[part 9 of 10: package /SoftwareComponents/CompositionSWComponents]
AUTOSAR XML (schema 00053)
package /SoftwareComponents/CompositionSWComponents  (continued)
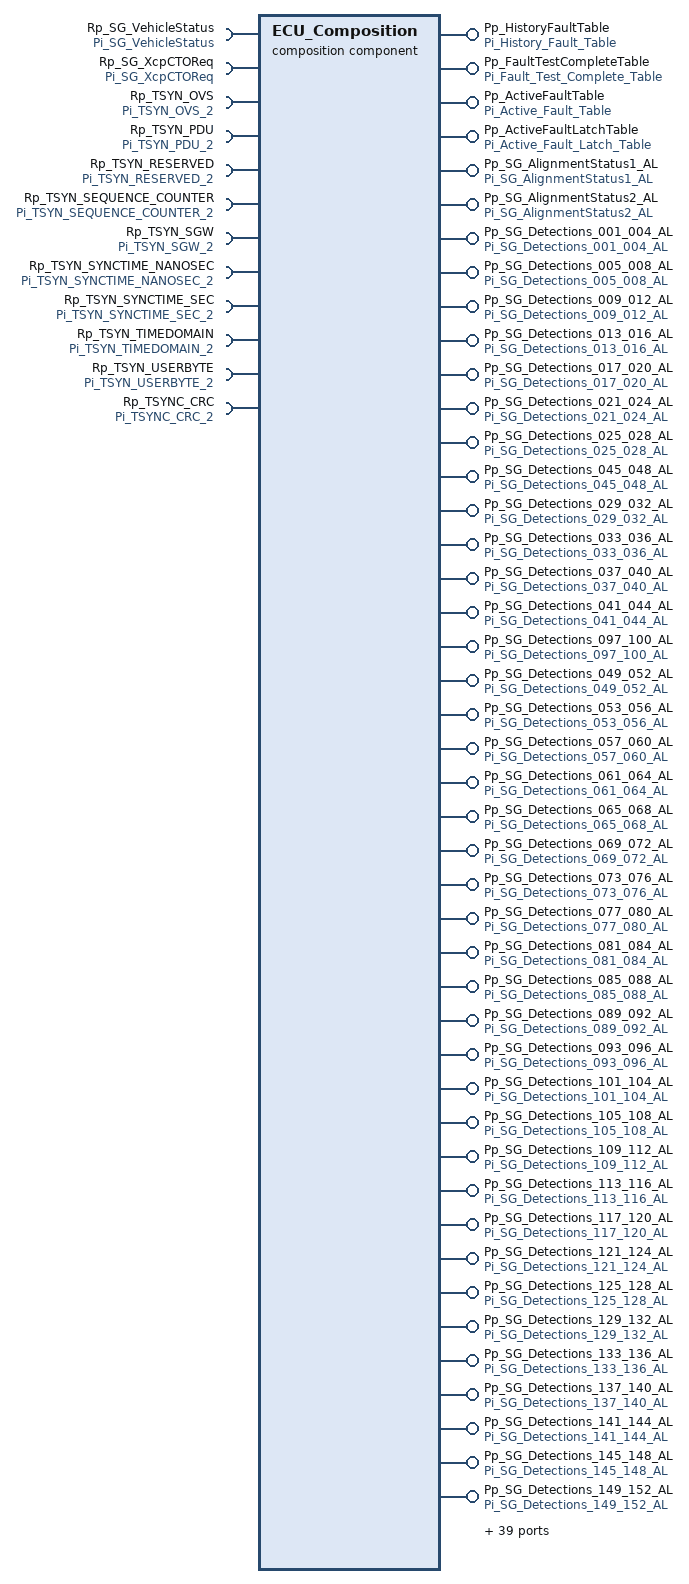
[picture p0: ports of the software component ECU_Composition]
  composition sw component type ECU_Composition  (continued)
    189 x provide port:  (continued)
      Pp_SG_Detections_361_364: nonqueued-sender-com-spec{data-element=Vdp_SG_Detections_361_364, init-value=fields=[DET_AZIMUTH_361:0, DET_AZIMUTH_362:0, DET_AZIMUTH_363:0, DET_AZIMUTH_364:0, DET_AZIMUTH_ERR_361:0, DET_AZIMUTH_ERR_362:0, DET_AZIMUTH_ERR_363:0, DET_AZIMUTH_ERR_364:0, DET_BI_STATIC_FLAG_361:0, DET_BI_STATIC_FLAG_362:0, DET_BI_STATIC_FLAG_363:0, DET_BI_STATIC_FLAG_364:0, DET_CONFD_AZIMUTH_361:0, DET_CONFD_AZIMUTH_362:0, DET_CONFD_AZIMUTH_363:0, DET_CONFD_AZIMUTH_364:0, DET_CONFD_ELEVATION_361:0, DET_CONFD_ELEVATION_362:0, DET_CONFD_ELEVATION_363:0, DET_CONFD_ELEVATION_364:0, DET_ELEVATION_361:0, DET_ELEVATION_362:0, DET_ELEVATION_363:0, DET_ELEVATION_364:0, DET_ELEVATION_ERR_361:0, DET_ELEVATION_ERR_362:0, DET_ELEVATION_ERR_363:0, DET_ELEVATION_ERR_364:0, DET_EXISTENCE_PROB_361:0, DET_EXISTENCE_PROB_362:0, DET_EXISTENCE_PROB_363:0, DET_EXISTENCE_PROB_364:0, DET_HVC_FLAG_361:0, DET_HVC_FLAG_362:0, DET_HVC_FLAG_363:0, DET_HVC_FLAG_364:0, DET_MH_CRC16_361_364:0, DET_MH_CYCLE_COUNTER_361_364:0, DET_MH_SCAN_INDEX_4LSB_361_364:0, DET_OUTSIDE_SECTOR_361:0, DET_OUTSIDE_SECTOR_362:0, DET_OUTSIDE_SECTOR_363:0, DET_OUTSIDE_SECTOR_364:0, DET_POINT_TARGET_PROB_361:0, DET_POINT_TARGET_PROB_362:0, DET_POINT_TARGET_PROB_363:0, DET_POINT_TARGET_PROB_364:0, DET_RANGE_361:0, DET_RANGE_362:0, DET_RANGE_363:0, DET_RANGE_364:0, DET_RANGE_ERR_361:0, DET_RANGE_ERR_362:0, DET_RANGE_ERR_363:0, DET_RANGE_ERR_364:0, DET_RANGE_VELOCITY_361:16384, DET_RANGE_VELOCITY_362:16384, DET_RANGE_VELOCITY_363:16384, DET_RANGE_VELOCITY_364:16384, DET_RANGE_VELOCITY_ERR_361:0, DET_RANGE_VELOCITY_ERR_362:0, DET_RANGE_VELOCITY_ERR_363:0, DET_RANGE_VELOCITY_ERR_364:0, DET_RCS_361:128, DET_RCS_362:128, DET_RCS_363:128, DET_RCS_364:128, DET_SNR_361:0, DET_SNR_362:0, DET_SNR_363:0, DET_SNR_364:0, DET_SUPER_RES_TARGET_361:0, DET_SUPER_RES_TARGET_362:0, DET_SUPER_RES_TARGET_363:0, DET_SUPER_RES_TARGET_364:0, DET_VALID_FLAG_361:0, DET_VALID_FLAG_362:0, DET_VALID_FLAG_363:0, DET_VALID_FLAG_364:0]}, provided-interface=Pi_SG_Detections_361_364
      Pp_SG_Detections_365_368: nonqueued-sender-com-spec{data-element=Vdp_SG_Detections_365_368, init-value=fields=[DET_AZIMUTH_365:0, DET_AZIMUTH_366:0, DET_AZIMUTH_367:0, DET_AZIMUTH_368:0, DET_AZIMUTH_ERR_365:0, DET_AZIMUTH_ERR_366:0, DET_AZIMUTH_ERR_367:0, DET_AZIMUTH_ERR_368:0, DET_BI_STATIC_FLAG_365:0, DET_BI_STATIC_FLAG_366:0, DET_BI_STATIC_FLAG_367:0, DET_BI_STATIC_FLAG_368:0, DET_CONFD_AZIMUTH_365:0, DET_CONFD_AZIMUTH_366:0, DET_CONFD_AZIMUTH_367:0, DET_CONFD_AZIMUTH_368:0, DET_CONFD_ELEVATION_365:0, DET_CONFD_ELEVATION_366:0, DET_CONFD_ELEVATION_367:0, DET_CONFD_ELEVATION_368:0, DET_ELEVATION_365:0, DET_ELEVATION_366:0, DET_ELEVATION_367:0, DET_ELEVATION_368:0, DET_ELEVATION_ERR_365:0, DET_ELEVATION_ERR_366:0, DET_ELEVATION_ERR_367:0, DET_ELEVATION_ERR_368:0, DET_EXISTENCE_PROB_365:0, DET_EXISTENCE_PROB_366:0, DET_EXISTENCE_PROB_367:0, DET_EXISTENCE_PROB_368:0, DET_HVC_FLAG_365:0, DET_HVC_FLAG_366:0, DET_HVC_FLAG_367:0, DET_HVC_FLAG_368:0, DET_MH_CRC16_365_368:0, DET_MH_CYCLE_COUNTER_365_368:0, DET_MH_SCAN_INDEX_4LSB_365_368:0, DET_OUTSIDE_SECTOR_365:0, DET_OUTSIDE_SECTOR_366:0, DET_OUTSIDE_SECTOR_367:0, DET_OUTSIDE_SECTOR_368:0, DET_POINT_TARGET_PROB_365:0, DET_POINT_TARGET_PROB_366:0, DET_POINT_TARGET_PROB_367:0, DET_POINT_TARGET_PROB_368:0, DET_RANGE_365:0, DET_RANGE_366:0, DET_RANGE_367:0, DET_RANGE_368:0, DET_RANGE_ERR_365:0, DET_RANGE_ERR_366:0, DET_RANGE_ERR_367:0, DET_RANGE_ERR_368:0, DET_RANGE_VELOCITY_365:16384, DET_RANGE_VELOCITY_366:16384, DET_RANGE_VELOCITY_367:16384, DET_RANGE_VELOCITY_368:16384, DET_RANGE_VELOCITY_ERR_365:0, DET_RANGE_VELOCITY_ERR_366:0, DET_RANGE_VELOCITY_ERR_367:0, DET_RANGE_VELOCITY_ERR_368:0, DET_RCS_365:128, DET_RCS_366:128, DET_RCS_367:128, DET_RCS_368:128, DET_SNR_365:0, DET_SNR_366:0, DET_SNR_367:0, DET_SNR_368:0, DET_SUPER_RES_TARGET_365:0, DET_SUPER_RES_TARGET_366:0, DET_SUPER_RES_TARGET_367:0, DET_SUPER_RES_TARGET_368:0, DET_VALID_FLAG_365:0, DET_VALID_FLAG_366:0, DET_VALID_FLAG_367:0, DET_VALID_FLAG_368:0]}, provided-interface=Pi_SG_Detections_365_368
      Pp_SG_Detections_369_372: nonqueued-sender-com-spec{data-element=Vdp_SG_Detections_369_372, init-value=fields=[DET_AZIMUTH_369:0, DET_AZIMUTH_370:0, DET_AZIMUTH_371:0, DET_AZIMUTH_372:0, DET_AZIMUTH_ERR_369:0, DET_AZIMUTH_ERR_370:0, DET_AZIMUTH_ERR_371:0, DET_AZIMUTH_ERR_372:0, DET_BI_STATIC_FLAG_369:0, DET_BI_STATIC_FLAG_370:0, DET_BI_STATIC_FLAG_371:0, DET_BI_STATIC_FLAG_372:0, DET_CONFD_AZIMUTH_369:0, DET_CONFD_AZIMUTH_370:0, DET_CONFD_AZIMUTH_371:0, DET_CONFD_AZIMUTH_372:0, DET_CONFD_ELEVATION_369:0, DET_CONFD_ELEVATION_370:0, DET_CONFD_ELEVATION_371:0, DET_CONFD_ELEVATION_372:0, DET_ELEVATION_369:0, DET_ELEVATION_370:0, DET_ELEVATION_371:0, DET_ELEVATION_372:0, DET_ELEVATION_ERR_369:0, DET_ELEVATION_ERR_370:0, DET_ELEVATION_ERR_371:0, DET_ELEVATION_ERR_372:0, DET_EXISTENCE_PROB_369:0, DET_EXISTENCE_PROB_370:0, DET_EXISTENCE_PROB_371:0, DET_EXISTENCE_PROB_372:0, DET_HVC_FLAG_369:0, DET_HVC_FLAG_370:0, DET_HVC_FLAG_371:0, DET_HVC_FLAG_372:0, DET_MH_CRC16_369_372:0, DET_MH_CYCLE_COUNTER_369_372:0, DET_MH_SCAN_INDEX_4LSB_369_372:0, DET_OUTSIDE_SECTOR_369:0, DET_OUTSIDE_SECTOR_370:0, DET_OUTSIDE_SECTOR_371:0, DET_OUTSIDE_SECTOR_372:0, DET_POINT_TARGET_PROB_369:0, DET_POINT_TARGET_PROB_370:0, DET_POINT_TARGET_PROB_371:0, DET_POINT_TARGET_PROB_372:0, DET_RANGE_369:0, DET_RANGE_370:0, DET_RANGE_371:0, DET_RANGE_372:0, DET_RANGE_ERR_369:0, DET_RANGE_ERR_370:0, DET_RANGE_ERR_371:0, DET_RANGE_ERR_372:0, DET_RANGE_VELOCITY_369:16384, DET_RANGE_VELOCITY_370:16384, DET_RANGE_VELOCITY_371:16384, DET_RANGE_VELOCITY_372:16384, DET_RANGE_VELOCITY_ERR_369:0, DET_RANGE_VELOCITY_ERR_370:0, DET_RANGE_VELOCITY_ERR_371:0, DET_RANGE_VELOCITY_ERR_372:0, DET_RCS_369:128, DET_RCS_370:128, DET_RCS_371:128, DET_RCS_372:128, DET_SNR_369:0, DET_SNR_370:0, DET_SNR_371:0, DET_SNR_372:0, DET_SUPER_RES_TARGET_369:0, DET_SUPER_RES_TARGET_370:0, DET_SUPER_RES_TARGET_371:0, DET_SUPER_RES_TARGET_372:0, DET_VALID_FLAG_369:0, DET_VALID_FLAG_370:0, DET_VALID_FLAG_371:0, DET_VALID_FLAG_372:0]}, provided-interface=Pi_SG_Detections_369_372
      Pp_SG_Detections_373_376: nonqueued-sender-com-spec{data-element=Vdp_SG_Detections_373_376, init-value=fields=[DET_AZIMUTH_373:0, DET_AZIMUTH_374:0, DET_AZIMUTH_375:0, DET_AZIMUTH_376:0, DET_AZIMUTH_ERR_373:0, DET_AZIMUTH_ERR_374:0, DET_AZIMUTH_ERR_375:0, DET_AZIMUTH_ERR_376:0, DET_BI_STATIC_FLAG_373:0, DET_BI_STATIC_FLAG_374:0, DET_BI_STATIC_FLAG_375:0, DET_BI_STATIC_FLAG_376:0, DET_CONFD_AZIMUTH_373:0, DET_CONFD_AZIMUTH_374:0, DET_CONFD_AZIMUTH_375:0, DET_CONFD_AZIMUTH_376:0, DET_CONFD_ELEVATION_373:0, DET_CONFD_ELEVATION_374:0, DET_CONFD_ELEVATION_375:0, DET_CONFD_ELEVATION_376:0, DET_ELEVATION_373:0, DET_ELEVATION_374:0, DET_ELEVATION_375:0, DET_ELEVATION_376:0, DET_ELEVATION_ERR_373:0, DET_ELEVATION_ERR_374:0, DET_ELEVATION_ERR_375:0, DET_ELEVATION_ERR_376:0, DET_EXISTENCE_PROB_373:0, DET_EXISTENCE_PROB_374:0, DET_EXISTENCE_PROB_375:0, DET_EXISTENCE_PROB_376:0, DET_HVC_FLAG_373:0, DET_HVC_FLAG_374:0, DET_HVC_FLAG_375:0, DET_HVC_FLAG_376:0, DET_MH_CRC16_373_376:0, DET_MH_CYCLE_COUNTER_373_376:0, DET_MH_SCAN_INDEX_4LSB_373_376:0, DET_OUTSIDE_SECTOR_373:0, DET_OUTSIDE_SECTOR_374:0, DET_OUTSIDE_SECTOR_375:0, DET_OUTSIDE_SECTOR_376:0, DET_POINT_TARGET_PROB_373:0, DET_POINT_TARGET_PROB_374:0, DET_POINT_TARGET_PROB_375:0, DET_POINT_TARGET_PROB_376:0, DET_RANGE_373:0, DET_RANGE_374:0, DET_RANGE_375:0, DET_RANGE_376:0, DET_RANGE_ERR_373:0, DET_RANGE_ERR_374:0, DET_RANGE_ERR_375:0, DET_RANGE_ERR_376:0, DET_RANGE_VELOCITY_373:16384, DET_RANGE_VELOCITY_374:16384, DET_RANGE_VELOCITY_375:16384, DET_RANGE_VELOCITY_376:16384, DET_RANGE_VELOCITY_ERR_373:0, DET_RANGE_VELOCITY_ERR_374:0, DET_RANGE_VELOCITY_ERR_375:0, DET_RANGE_VELOCITY_ERR_376:0, DET_RCS_373:128, DET_RCS_374:128, DET_RCS_375:128, DET_RCS_376:128, DET_SNR_373:0, DET_SNR_374:0, DET_SNR_375:0, DET_SNR_376:0, DET_SUPER_RES_TARGET_373:0, DET_SUPER_RES_TARGET_374:0, DET_SUPER_RES_TARGET_375:0, DET_SUPER_RES_TARGET_376:0, DET_VALID_FLAG_373:0, DET_VALID_FLAG_374:0, DET_VALID_FLAG_375:0, DET_VALID_FLAG_376:0]}, provided-interface=Pi_SG_Detections_373_376
      Pp_SG_Detections_377_380: nonqueued-sender-com-spec{data-element=Vdp_SG_Detections_377_380, init-value=fields=[DET_AZIMUTH_377:0, DET_AZIMUTH_378:0, DET_AZIMUTH_379:0, DET_AZIMUTH_380:0, DET_AZIMUTH_ERR_377:0, DET_AZIMUTH_ERR_378:0, DET_AZIMUTH_ERR_379:0, DET_AZIMUTH_ERR_380:0, DET_BI_STATIC_FLAG_377:0, DET_BI_STATIC_FLAG_378:0, DET_BI_STATIC_FLAG_379:0, DET_BI_STATIC_FLAG_380:0, DET_CONFD_AZIMUTH_377:0, DET_CONFD_AZIMUTH_378:0, DET_CONFD_AZIMUTH_379:0, DET_CONFD_AZIMUTH_380:0, DET_CONFD_ELEVATION_377:0, DET_CONFD_ELEVATION_378:0, DET_CONFD_ELEVATION_379:0, DET_CONFD_ELEVATION_380:0, DET_ELEVATION_377:0, DET_ELEVATION_378:0, DET_ELEVATION_379:0, DET_ELEVATION_380:0, DET_ELEVATION_ERR_377:0, DET_ELEVATION_ERR_378:0, DET_ELEVATION_ERR_379:0, DET_ELEVATION_ERR_380:0, DET_EXISTENCE_PROB_377:0, DET_EXISTENCE_PROB_378:0, DET_EXISTENCE_PROB_379:0, DET_EXISTENCE_PROB_380:0, DET_HVC_FLAG_377:0, DET_HVC_FLAG_378:0, DET_HVC_FLAG_379:0, DET_HVC_FLAG_380:0, DET_MH_CRC16_377_380:0, DET_MH_CYCLE_COUNTER_377_380:0, DET_MH_SCAN_INDEX_4LSB_377_380:0, DET_OUTSIDE_SECTOR_377:0, DET_OUTSIDE_SECTOR_378:0, DET_OUTSIDE_SECTOR_379:0, DET_OUTSIDE_SECTOR_380:0, DET_POINT_TARGET_PROB_377:0, DET_POINT_TARGET_PROB_378:0, DET_POINT_TARGET_PROB_379:0, DET_POINT_TARGET_PROB_380:0, DET_RANGE_377:0, DET_RANGE_378:0, DET_RANGE_379:0, DET_RANGE_380:0, DET_RANGE_ERR_377:0, DET_RANGE_ERR_378:0, DET_RANGE_ERR_379:0, DET_RANGE_ERR_380:0, DET_RANGE_VELOCITY_377:16384, DET_RANGE_VELOCITY_378:16384, DET_RANGE_VELOCITY_379:16384, DET_RANGE_VELOCITY_380:16384, DET_RANGE_VELOCITY_ERR_377:0, DET_RANGE_VELOCITY_ERR_378:0, DET_RANGE_VELOCITY_ERR_379:0, DET_RANGE_VELOCITY_ERR_380:0, DET_RCS_377:128, DET_RCS_378:128, DET_RCS_379:128, DET_RCS_380:128, DET_SNR_377:0, DET_SNR_378:0, DET_SNR_379:0, DET_SNR_380:0, DET_SUPER_RES_TARGET_377:0, DET_SUPER_RES_TARGET_378:0, DET_SUPER_RES_TARGET_379:0, DET_SUPER_RES_TARGET_380:0, DET_VALID_FLAG_377:0, DET_VALID_FLAG_378:0, DET_VALID_FLAG_379:0, DET_VALID_FLAG_380:0]}, provided-interface=Pi_SG_Detections_377_380
      Pp_SG_Detections_381_384: nonqueued-sender-com-spec{data-element=Vdp_SG_Detections_381_384, init-value=fields=[DET_AZIMUTH_381:0, DET_AZIMUTH_382:0, DET_AZIMUTH_383:0, DET_AZIMUTH_384:0, DET_AZIMUTH_ERR_381:0, DET_AZIMUTH_ERR_382:0, DET_AZIMUTH_ERR_383:0, DET_AZIMUTH_ERR_384:0, DET_BI_STATIC_FLAG_381:0, DET_BI_STATIC_FLAG_382:0, DET_BI_STATIC_FLAG_383:0, DET_BI_STATIC_FLAG_384:0, DET_CONFD_AZIMUTH_381:0, DET_CONFD_AZIMUTH_382:0, DET_CONFD_AZIMUTH_383:0, DET_CONFD_AZIMUTH_384:0, DET_CONFD_ELEVATION_381:0, DET_CONFD_ELEVATION_382:0, DET_CONFD_ELEVATION_383:0, DET_CONFD_ELEVATION_384:0, DET_ELEVATION_381:0, DET_ELEVATION_382:0, DET_ELEVATION_383:0, DET_ELEVATION_384:0, DET_ELEVATION_ERR_381:0, DET_ELEVATION_ERR_382:0, DET_ELEVATION_ERR_383:0, DET_ELEVATION_ERR_384:0, DET_EXISTENCE_PROB_381:0, DET_EXISTENCE_PROB_382:0, DET_EXISTENCE_PROB_383:0, DET_EXISTENCE_PROB_384:0, DET_HVC_FLAG_381:0, DET_HVC_FLAG_382:0, DET_HVC_FLAG_383:0, DET_HVC_FLAG_384:0, DET_MH_CRC16_381_384:0, DET_MH_CYCLE_COUNTER_381_384:0, DET_MH_SCAN_INDEX_4LSB_381_384:0, DET_OUTSIDE_SECTOR_381:0, DET_OUTSIDE_SECTOR_382:0, DET_OUTSIDE_SECTOR_383:0, DET_OUTSIDE_SECTOR_384:0, DET_POINT_TARGET_PROB_381:0, DET_POINT_TARGET_PROB_382:0, DET_POINT_TARGET_PROB_383:0, DET_POINT_TARGET_PROB_384:0, DET_RANGE_381:0, DET_RANGE_382:0, DET_RANGE_383:0, DET_RANGE_384:0, DET_RANGE_ERR_381:0, DET_RANGE_ERR_382:0, DET_RANGE_ERR_383:0, DET_RANGE_ERR_384:0, DET_RANGE_VELOCITY_381:16384, DET_RANGE_VELOCITY_382:16384, DET_RANGE_VELOCITY_383:16384, DET_RANGE_VELOCITY_384:16384, DET_RANGE_VELOCITY_ERR_381:0, DET_RANGE_VELOCITY_ERR_382:0, DET_RANGE_VELOCITY_ERR_383:0, DET_RANGE_VELOCITY_ERR_384:0, DET_RCS_381:128, DET_RCS_382:128, DET_RCS_383:128, DET_RCS_384:128, DET_SNR_381:0, DET_SNR_382:0, DET_SNR_383:0, DET_SNR_384:0, DET_SUPER_RES_TARGET_381:0, DET_SUPER_RES_TARGET_382:0, DET_SUPER_RES_TARGET_383:0, DET_SUPER_RES_TARGET_384:0, DET_VALID_FLAG_381:0, DET_VALID_FLAG_382:0, DET_VALID_FLAG_383:0, DET_VALID_FLAG_384:0]}, provided-interface=Pi_SG_Detections_381_384
      Pp_SG_Detections_385_388: nonqueued-sender-com-spec{data-element=Vdp_SG_Detections_385_388, init-value=fields=[DET_AZIMUTH_385:0, DET_AZIMUTH_386:0, DET_AZIMUTH_387:0, DET_AZIMUTH_388:0, DET_AZIMUTH_ERR_385:0, DET_AZIMUTH_ERR_386:0, DET_AZIMUTH_ERR_387:0, DET_AZIMUTH_ERR_388:0, DET_BI_STATIC_FLAG_385:0, DET_BI_STATIC_FLAG_386:0, DET_BI_STATIC_FLAG_387:0, DET_BI_STATIC_FLAG_388:0, DET_CONFD_AZIMUTH_385:0, DET_CONFD_AZIMUTH_386:0, DET_CONFD_AZIMUTH_387:0, DET_CONFD_AZIMUTH_388:0, DET_CONFD_ELEVATION_385:0, DET_CONFD_ELEVATION_386:0, DET_CONFD_ELEVATION_387:0, DET_CONFD_ELEVATION_388:0, DET_ELEVATION_385:0, DET_ELEVATION_386:0, DET_ELEVATION_387:0, DET_ELEVATION_388:0, DET_ELEVATION_ERR_385:0, DET_ELEVATION_ERR_386:0, DET_ELEVATION_ERR_387:0, DET_ELEVATION_ERR_388:0, DET_EXISTENCE_PROB_385:0, DET_EXISTENCE_PROB_386:0, DET_EXISTENCE_PROB_387:0, DET_EXISTENCE_PROB_388:0, DET_HVC_FLAG_385:0, DET_HVC_FLAG_386:0, DET_HVC_FLAG_387:0, DET_HVC_FLAG_388:0, DET_MH_CRC16_385_388:0, DET_MH_CYCLE_COUNTER_385_388:0, DET_MH_SCAN_INDEX_4LSB_385_388:0, DET_OUTSIDE_SECTOR_385:0, DET_OUTSIDE_SECTOR_386:0, DET_OUTSIDE_SECTOR_387:0, DET_OUTSIDE_SECTOR_388:0, DET_POINT_TARGET_PROB_385:0, DET_POINT_TARGET_PROB_386:0, DET_POINT_TARGET_PROB_387:0, DET_POINT_TARGET_PROB_388:0, DET_RANGE_385:0, DET_RANGE_386:0, DET_RANGE_387:0, DET_RANGE_388:0, DET_RANGE_ERR_385:0, DET_RANGE_ERR_386:0, DET_RANGE_ERR_387:0, DET_RANGE_ERR_388:0, DET_RANGE_VELOCITY_385:16384, DET_RANGE_VELOCITY_386:16384, DET_RANGE_VELOCITY_387:16384, DET_RANGE_VELOCITY_388:16384, DET_RANGE_VELOCITY_ERR_385:0, DET_RANGE_VELOCITY_ERR_386:0, DET_RANGE_VELOCITY_ERR_387:0, DET_RANGE_VELOCITY_ERR_388:0, DET_RCS_385:128, DET_RCS_386:128, DET_RCS_387:128, DET_RCS_388:128, DET_SNR_385:0, DET_SNR_386:0, DET_SNR_387:0, DET_SNR_388:0, DET_SUPER_RES_TARGET_385:0, DET_SUPER_RES_TARGET_386:0, DET_SUPER_RES_TARGET_387:0, DET_SUPER_RES_TARGET_388:0, DET_VALID_FLAG_385:0, DET_VALID_FLAG_386:0, DET_VALID_FLAG_387:0, DET_VALID_FLAG_388:0]}, provided-interface=Pi_SG_Detections_385_388
      Pp_SG_Detections_389_392: nonqueued-sender-com-spec{data-element=Vdp_SG_Detections_389_392, init-value=fields=[DET_AZIMUTH_389:0, DET_AZIMUTH_390:0, DET_AZIMUTH_391:0, DET_AZIMUTH_392:0, DET_AZIMUTH_ERR_389:0, DET_AZIMUTH_ERR_390:0, DET_AZIMUTH_ERR_391:0, DET_AZIMUTH_ERR_392:0, DET_BI_STATIC_FLAG_389:0, DET_BI_STATIC_FLAG_390:0, DET_BI_STATIC_FLAG_391:0, DET_BI_STATIC_FLAG_392:0, DET_CONFD_AZIMUTH_389:0, DET_CONFD_AZIMUTH_390:0, DET_CONFD_AZIMUTH_391:0, DET_CONFD_AZIMUTH_392:0, DET_CONFD_ELEVATION_389:0, DET_CONFD_ELEVATION_390:0, DET_CONFD_ELEVATION_391:0, DET_CONFD_ELEVATION_392:0, DET_ELEVATION_389:0, DET_ELEVATION_390:0, DET_ELEVATION_391:0, DET_ELEVATION_392:0, DET_ELEVATION_ERR_389:0, DET_ELEVATION_ERR_390:0, DET_ELEVATION_ERR_391:0, DET_ELEVATION_ERR_392:0, DET_EXISTENCE_PROB_389:0, DET_EXISTENCE_PROB_390:0, DET_EXISTENCE_PROB_391:0, DET_EXISTENCE_PROB_392:0, DET_HVC_FLAG_389:0, DET_HVC_FLAG_390:0, DET_HVC_FLAG_391:0, DET_HVC_FLAG_392:0, DET_MH_CRC16_389_392:0, DET_MH_CYCLE_COUNTER_389_392:0, DET_MH_SCAN_INDEX_4LSB_389_392:0, DET_OUTSIDE_SECTOR_389:0, DET_OUTSIDE_SECTOR_390:0, DET_OUTSIDE_SECTOR_391:0, DET_OUTSIDE_SECTOR_392:0, DET_POINT_TARGET_PROB_389:0, DET_POINT_TARGET_PROB_390:0, DET_POINT_TARGET_PROB_391:0, DET_POINT_TARGET_PROB_392:0, DET_RANGE_389:0, DET_RANGE_390:0, DET_RANGE_391:0, DET_RANGE_392:0, DET_RANGE_ERR_389:0, DET_RANGE_ERR_390:0, DET_RANGE_ERR_391:0, DET_RANGE_ERR_392:0, DET_RANGE_VELOCITY_389:16384, DET_RANGE_VELOCITY_390:16384, DET_RANGE_VELOCITY_391:16384, DET_RANGE_VELOCITY_392:16384, DET_RANGE_VELOCITY_ERR_389:0, DET_RANGE_VELOCITY_ERR_390:0, DET_RANGE_VELOCITY_ERR_391:0, DET_RANGE_VELOCITY_ERR_392:0, DET_RCS_389:128, DET_RCS_390:128, DET_RCS_391:128, DET_RCS_392:128, DET_SNR_389:0, DET_SNR_390:0, DET_SNR_391:0, DET_SNR_392:0, DET_SUPER_RES_TARGET_389:0, DET_SUPER_RES_TARGET_390:0, DET_SUPER_RES_TARGET_391:0, DET_SUPER_RES_TARGET_392:0, DET_VALID_FLAG_389:0, DET_VALID_FLAG_390:0, DET_VALID_FLAG_391:0, DET_VALID_FLAG_392:0]}, provided-interface=Pi_SG_Detections_389_392
      Pp_SG_Detections_393_396: nonqueued-sender-com-spec{data-element=Vdp_SG_Detections_393_396, init-value=fields=[DET_AZIMUTH_393:0, DET_AZIMUTH_394:0, DET_AZIMUTH_395:0, DET_AZIMUTH_396:0, DET_AZIMUTH_ERR_393:0, DET_AZIMUTH_ERR_394:0, DET_AZIMUTH_ERR_395:0, DET_AZIMUTH_ERR_396:0, DET_BI_STATIC_FLAG_393:0, DET_BI_STATIC_FLAG_394:0, DET_BI_STATIC_FLAG_395:0, DET_BI_STATIC_FLAG_396:0, DET_CONFD_AZIMUTH_393:0, DET_CONFD_AZIMUTH_394:0, DET_CONFD_AZIMUTH_395:0, DET_CONFD_AZIMUTH_396:0, DET_CONFD_ELEVATION_393:0, DET_CONFD_ELEVATION_394:0, DET_CONFD_ELEVATION_395:0, DET_CONFD_ELEVATION_396:0, DET_ELEVATION_393:0, DET_ELEVATION_394:0, DET_ELEVATION_395:0, DET_ELEVATION_396:0, DET_ELEVATION_ERR_393:0, DET_ELEVATION_ERR_394:0, DET_ELEVATION_ERR_395:0, DET_ELEVATION_ERR_396:0, DET_EXISTENCE_PROB_393:0, DET_EXISTENCE_PROB_394:0, DET_EXISTENCE_PROB_395:0, DET_EXISTENCE_PROB_396:0, DET_HVC_FLAG_393:0, DET_HVC_FLAG_394:0, DET_HVC_FLAG_395:0, DET_HVC_FLAG_396:0, DET_MH_CRC16_393_396:0, DET_MH_CYCLE_COUNTER_393_396:0, DET_MH_SCAN_INDEX_4LSB_393_396:0, DET_OUTSIDE_SECTOR_393:0, DET_OUTSIDE_SECTOR_394:0, DET_OUTSIDE_SECTOR_395:0, DET_OUTSIDE_SECTOR_396:0, DET_POINT_TARGET_PROB_393:0, DET_POINT_TARGET_PROB_394:0, DET_POINT_TARGET_PROB_395:0, DET_POINT_TARGET_PROB_396:0, DET_RANGE_393:0, DET_RANGE_394:0, DET_RANGE_395:0, DET_RANGE_396:0, DET_RANGE_ERR_393:0, DET_RANGE_ERR_394:0, DET_RANGE_ERR_395:0, DET_RANGE_ERR_396:0, DET_RANGE_VELOCITY_393:16384, DET_RANGE_VELOCITY_394:16384, DET_RANGE_VELOCITY_395:16384, DET_RANGE_VELOCITY_396:16384, DET_RANGE_VELOCITY_ERR_393:0, DET_RANGE_VELOCITY_ERR_394:0, DET_RANGE_VELOCITY_ERR_395:0, DET_RANGE_VELOCITY_ERR_396:0, DET_RCS_393:128, DET_RCS_394:128, DET_RCS_395:128, DET_RCS_396:128, DET_SNR_393:0, DET_SNR_394:0, DET_SNR_395:0, DET_SNR_396:0, DET_SUPER_RES_TARGET_393:0, DET_SUPER_RES_TARGET_394:0, DET_SUPER_RES_TARGET_395:0, DET_SUPER_RES_TARGET_396:0, DET_VALID_FLAG_393:0, DET_VALID_FLAG_394:0, DET_VALID_FLAG_395:0, DET_VALID_FLAG_396:0]}, provided-interface=Pi_SG_Detections_393_396
      Pp_SG_Detections_397_400: nonqueued-sender-com-spec{data-element=Vdp_SG_Detections_397_400, init-value=fields=[DET_AZIMUTH_397:0, DET_AZIMUTH_398:0, DET_AZIMUTH_399:0, DET_AZIMUTH_400:0, DET_AZIMUTH_ERR_397:0, DET_AZIMUTH_ERR_398:0, DET_AZIMUTH_ERR_399:0, DET_AZIMUTH_ERR_400:0, DET_BI_STATIC_FLAG_397:0, DET_BI_STATIC_FLAG_398:0, DET_BI_STATIC_FLAG_399:0, DET_BI_STATIC_FLAG_400:0, DET_CONFD_AZIMUTH_397:0, DET_CONFD_AZIMUTH_398:0, DET_CONFD_AZIMUTH_399:0, DET_CONFD_AZIMUTH_400:0, DET_CONFD_ELEVATION_397:0, DET_CONFD_ELEVATION_398:0, DET_CONFD_ELEVATION_399:0, DET_CONFD_ELEVATION_400:0, DET_ELEVATION_397:0, DET_ELEVATION_398:0, DET_ELEVATION_399:0, DET_ELEVATION_400:0, DET_ELEVATION_ERR_397:0, DET_ELEVATION_ERR_398:0, DET_ELEVATION_ERR_399:0, DET_ELEVATION_ERR_400:0, DET_EXISTENCE_PROB_397:0, DET_EXISTENCE_PROB_398:0, DET_EXISTENCE_PROB_399:0, DET_EXISTENCE_PROB_400:0, DET_HVC_FLAG_397:0, DET_HVC_FLAG_398:0, DET_HVC_FLAG_399:0, DET_HVC_FLAG_400:0, DET_MH_CRC16_397_400:0, DET_MH_CYCLE_COUNTER_397_400:0, DET_MH_SCAN_INDEX_4LSB_397_400:0, DET_OUTSIDE_SECTOR_397:0, DET_OUTSIDE_SECTOR_398:0, DET_OUTSIDE_SECTOR_399:0, DET_OUTSIDE_SECTOR_400:0, DET_POINT_TARGET_PROB_397:0, DET_POINT_TARGET_PROB_398:0, DET_POINT_TARGET_PROB_399:0, DET_POINT_TARGET_PROB_400:0, DET_RANGE_397:0, DET_RANGE_398:0, DET_RANGE_399:0, DET_RANGE_400:0, DET_RANGE_ERR_397:0, DET_RANGE_ERR_398:0, DET_RANGE_ERR_399:0, DET_RANGE_ERR_400:0, DET_RANGE_VELOCITY_397:16384, DET_RANGE_VELOCITY_398:16384, DET_RANGE_VELOCITY_399:16384, DET_RANGE_VELOCITY_400:16384, DET_RANGE_VELOCITY_ERR_397:0, DET_RANGE_VELOCITY_ERR_398:0, DET_RANGE_VELOCITY_ERR_399:0, DET_RANGE_VELOCITY_ERR_400:0, DET_RCS_397:128, DET_RCS_398:128, DET_RCS_399:128, DET_RCS_400:128, DET_SNR_397:0, DET_SNR_398:0, DET_SNR_399:0, DET_SNR_400:0, DET_SUPER_RES_TARGET_397:0, DET_SUPER_RES_TARGET_398:0, DET_SUPER_RES_TARGET_399:0, DET_SUPER_RES_TARGET_400:0, DET_VALID_FLAG_397:0, DET_VALID_FLAG_398:0, DET_VALID_FLAG_399:0, DET_VALID_FLAG_400:0]}, provided-interface=Pi_SG_Detections_397_400
      Pp_SG_RadarCapability: nonqueued-sender-com-spec{data-element=Vdp_SG_RadarCapability, init-value=fields=[CAP_AngleAzimuthRangeEnd:0, CAP_AngleAzimuthRangeStart:0, CAP_BlockageActive:1, CAP_BlockageProbability:0, CAP_BlockageSensitivity:1, CAP_BlockageStatus:3, CAP_BlockageValue:5, CAP_CYCLE_COUNTER:0, CAP_DampingActive:0, CAP_DampingCurrent:25500, CAP_DampingStandardDeviation:0, CAP_DampingStatus:3, CAP_FreeSightCheckActive:0, CAP_FreeSightCheckStatus:0, CAP_MaxDetectionRangeCar:0, CAP_MaxDetRangeMotorbike:0, CAP_MaxDetRangePedestrian:0, CAP_MH_CRC16:0, CAP_RangeEstimationActive:1, CAP_RangeEstimationStatus:3, CAP_SideLobeLevelBeamformer:0, CAP_SLBlockageFilterValue:0, CAP_SLBlockageFlag:0, CAP_SLLMonitoringActive:1, CAP_SLLMonitoringStatus:3]}, provided-interface=Pi_SG_RadarCapability
      Pp_SG_RadarHeader: nonqueued-sender-com-spec{data-element=Vdp_SG_RadarHeader, init-value=fields=[HED_AF_TIME_INST:0, HED_AF_TIME_PEAK:0, HED_ALIGN_HOR_QF:0, HED_ALIGN_HOR_REF:0, HED_ALIGN_VER_QF:0, HED_ALIGN_VER_REF:0, HED_DATA_QUALIFIER:0, HED_DET_BI_STATIC_COUNT:0, HED_DET_NUM_OF_1PASS:0, HED_DET_NUM_OF_2PASS:0, HED_DET_RANGE_MAX:0, HED_DET_RANGE_MIN:0, HED_DET_SPEED_RANGE_MAX:32768, HED_DET_SPEED_RANGE_MIN:32768, HED_FOV_HOR_MAX:0, HED_FOV_HOR_MIN:0, HED_FOV_VER_MAX:0, HED_FOV_VER_MIN:0, HED_INTRFC_VERSION_ID_MAJOR:0, HED_INTRFC_VERSION_ID_MINOR:0, HED_INTRFC_VERSION_ID_PATCH:0, HED_LOOK_ID:0, HED_LOOK_INDEX:0, HED_MAIN_CORE_TIME_INST:0, HED_MAIN_CORE_TIME_PEAK:0, HED_MAX_NUM_OF_DETECTIONS:0, HED_MH_CRC16:0, HED_MH_CYCLE_COUNTER:0, HED_NUM_OF_RESTBINS_USED:0, HED_NUM_OF_VALID_DETECTIONS:0, HED_OPERATION_MODE:0, HED_PROCESSED_RANGE:0, HED_RDD_CORE_TIME_INST:0, HED_RDD_CORE_TIME_PEAK:0, HED_SCAN_INDEX:0, HED_SENSOR_TIME_STAMP_NS:0, HED_SENSOR_TIME_STAMP_SEC:0, HED_SLOPE_CORR_EXECUTIONFLAG:0, HED_SP_CORE_TIME_INST:0, HED_SP_CORE_TIME_PEAK:0, HED_TIME_SYNC_SRC_MASTER:0, HED_TIME_SYNC_VALIDITY_FLAG:0, HED_TRIGGER_TIME:0]}, provided-interface=Pi_SG_RadarHeader
      Pp_SG_RadarStatus1: nonqueued-sender-com-spec{data-element=Vdp_SG_RadarStatus1, init-value=fields=[STS_DET_DBC_BASE_VER_MAJOR:0, STS_DET_DBC_BASE_VER_MINOR:0, STS_HARDWARE_VERSION:0, STS_MH_001_CRC16:0, STS_MH_001_CYCLE_COUNTER:0, STS_PBL_VERSION_FIELD1:0, STS_PBL_VERSION_FIELD2:0, STS_PBL_VERSION_FIELD3:0, STS_PBL_VERSION_FIELD4:0, STS_PCAN_PROTOCOL_VER_MAJOR:0, STS_PCAN_PROTOCOL_VER_MINOR:0, STS_PLATFORM_VARIANT:0, STS_SENSOR_HEIGHT:0, STS_SENSOR_MOUNT_LOCATION:0, STS_SENSOR_MOUNT_ORNT_PITCH:3927, STS_SENSOR_MOUNT_ORNT_ROLL:3927, STS_SENSOR_MOUNT_ORNT_YAW:3927, STS_SENSOR_MOUNT_POS_X:0, STS_SENSOR_MOUNT_POS_Y:0, STS_SENSOR_MOUNT_POS_Z:0, STS_SENSOR_POSITION:0, STS_SERIAL_NUM_JULIAN_DAY:0, STS_SERIAL_NUM_JULIAN_YEAR:0, STS_SERIAL_NUMBER_SEQUENCE:0, STS_SMC_CAL_VER_MAJOR:0, STS_SMC_CAL_VER_MINOR:0, STS_SMC_PLATFROM_VERSION:0, STS_SMC_SECTION_COMPTBLITY:0, STS_SW_VERSION_FIELD1:0, STS_SW_VERSION_FIELD2:0, STS_SW_VERSION_FIELD3:0, STS_SW_VERSION_FIELD4:0, STS_TIME_SINCE_POWER_ON:0, STS_USC_CAL_VER_MAJOR:0, STS_USC_CAL_VER_MINOR:0, STS_USC_SECTION_COMPTBLITY:0]}, provided-interface=Pi_SG_RadarStatus1
      Pp_SG_RadarStatus2: nonqueued-sender-com-spec{data-element=Vdp_SG_RadarStatus2, init-value=fields=[STS_AF_CORE_THROUGHPUT:0, STS_BRR_STATUS:0, STS_CORE_ACTIVE_FAULTS:0, STS_MCU_TEMP:0, STS_MH_002_CRC16:0, STS_MH_002_CYCLE_COUNTER:0, 0, STS_MMIC_TEMP_RX:0, STS_MMIC_TEMP_TX0:0, STS_MMIC_TEMP_TX1_2:0, STS_MMIC_TEMP_TX3_4:0, STS_NO_TSYN_ERROR:0, STS_POINT_OF_TRIGGER:0, STS_RDD_CORE_THROUGHPUT:0, STS_SCAN_TYPE:0, STS_STEERING_ANGLE:0, STS_STEERING_ANGLE_SIGN:0, STS_TIME_SYNC_OFFSET:0, STS_VEH_SPEED_DIRECTION:0, STS_VEHICLE_SPEED_CALC:0, STS_VEHICLE_SUPPLY_VOLTAGE:0, STS_XCVR_OPERATIONAL:0, STS_YAW_RATE_BIAS:0]}, provided-interface=Pi_SG_RadarStatus2
      Pp_SG_TrackerHeader: nonqueued-sender-com-spec{data-element=Vdp_SG_TrackerHeader, init-value=fields=[HED_MH_002_CRC16:0, HED_MH_002_CYCLE_COUNTER:0, HED_TRKR_DATA_QUALIFIER:0, HED_TRKR_IDX:0, HED_TRKR_NUM_OF_ACTIV_OBJS:0, HED_TRKR_OBJLST_TIME_STAMP_NS:0, HED_TRKR_OBJLST_TIME_STAMP_SC:0, HED_TRKR_TIME_INST:0, HED_TRKR_TIME_PEAK:0, HED_TRKR_VEH_COORD_TYPE:0, HED_TRKR_VEHICLE_IDX:0]}, provided-interface=Pi_SG_TrackerHeader
      Pp_SG_TrackerObject{001..064}: nonqueued-sender-com-spec{data-element=Vdp_SG_TrackerObject{001..064}, init-value=fields=[OBJ_ACCEL_ERR_CRR_COEF_{001..064}:120, OBJ_ACCELERATION_LAT_{001..064}:400, OBJ_ACCELERATION_LAT_ERR_{001..064}:0, OBJ_ACCELERATION_LONG_{001..064}:400, OBJ_ACCELERATION_LONG_ERR_{001..064}:0, OBJ_ALIVE_TIME_{001..064}:0, OBJ_CLS_TYPE1_{001..064}:0, OBJ_CLS_TYPE1_PROB_{001..064}:0, OBJ_CLS_TYPE2_{001..064}:0, OBJ_CLS_TYPE2_PROB_{001..064}:0, OBJ_CLS_TYPE3_{001..064}:0, OBJ_CLS_TYPE3_PROB_{001..064}:0, OBJ_CLS_TYPE4_{001..064}:0, OBJ_CLS_TYPE4_PROB_{001..064}:0, OBJ_CLS_TYPE5_{001..064}:0, OBJ_CLS_TYPE5_PROB_{001..064}:0, OBJ_CLS_TYPE6_{001..064}:0, OBJ_CLS_TYPE6_PROB_{001..064}:0, OBJ_DIMENSION_LENGTH_{001..064}:0, OBJ_DIMENSION_LENGTH_ERR_{001..064}:0, OBJ_DIMENSION_WIDTH_{001..064}:0, OBJ_DIMENSION_WIDTH_ERR_{001..064}:0, OBJ_EXISTENCE_PROB_{001..064}:0, OBJ_GROUP_ID_{001..064}:0, OBJ_ID_{001..064}:0, OBJ_MEASUREMENT_STATUS_{001..064}:0, OBJ_MH_CRC16_{001..064}:0, OBJ_MH_CYCLE_COUNTER_{001..064}:0, OBJ_MOVEMENT_STATUS_{001..064}:0, OBJ_POS_ERR_CRR_COEF_{001..064}:120, OBJ_POS_LAT_{001..064}:32700, OBJ_POS_LAT_ERR_{001..064}:0, OBJ_POS_LONG_{001..064}:32700, OBJ_POS_LONG_ERR_{001..064}:0, OBJ_RCS_{001..064}:64, OBJ_REF_PT_LAT_OFFSET_{001..064}:0, OBJ_REF_PT_LONG_OFFSET_{001..064}:0, OBJ_TIMESTAMP_OFFSET_{001..064}:127, OBJ_TRACK_MOTION_MODEL_{001..064}:0, OBJ_VEH_TRACK_FLAG_{001..064}:0, OBJ_VELOCITY_ERR_CRR_COEF_{001..064}:120, OBJ_VELOCITY_LAT_{001..064}:16300, OBJ_VELOCITY_LAT_ERR_{001..064}:0, OBJ_VELOCITY_LONG_{001..064}:16300, OBJ_VELOCITY_LONG_ERR_{001..064}:0, OBJ_YAW_ANGLE_{001..064}:2000, OBJ_YAW_ANGLE_ERR_{001..064}:0, OBJ_YAW_RATE_{001..064}:448, OBJ_YAW_RATE_ERR_{001..064}:0]}, provided-interface=Pi_SG_TrackerObject{001..064}
      Pp_SG_TrackerStatus: nonqueued-sender-com-spec{data-element=Vdp_SG_TrackerStatus, init-value=fields=[STS_MH_003_CRC16:0, STS_MH_003_CYCLE_COUNTER:0, STS_OBJ_DBC_BASE_VER_MAJOR:0, STS_OBJ_DBC_BASE_VER_MINOR:0, STS_PERCEPTION_MODULE_ID:0, STS_TRKR_MAJOR_VERSION:0, STS_TRKR_MINOR_VERSION:0, STS_TRKR_PATCH_VERSION:0]}, provided-interface=Pi_SG_TrackerStatus
      Pp_SG_XcpCTOResp: nonqueued-sender-com-spec{data-element=Vdp_SG_XcpCTOResp, init-value=fields=[STS_XCP_RES_CTO_Byte0:0, STS_XCP_RES_CTO_Byte1:0, STS_XCP_RES_CTO_Byte2:0, STS_XCP_RES_CTO_Byte3:0, STS_XCP_RES_CTO_Byte4:0, STS_XCP_RES_CTO_Byte5:0, STS_XCP_RES_CTO_Byte6:0, STS_XCP_RES_CTO_Byte7:0, STS_XCP_RES_CTO_Byte8:0, STS_XCP_RES_CTO_Byte9:0, STS_XCP_RES_CTO_Byte10:0, STS_XCP_RES_CTO_Byte11:0, STS_XCP_RES_CTO_Byte12:0, STS_XCP_RES_CTO_Byte13:0, STS_XCP_RES_CTO_Byte14:0, STS_XCP_RES_CTO_Byte15:0, STS_XCP_RES_CTO_Byte16:0, STS_XCP_RES_CTO_Byte17:0, STS_XCP_RES_CTO_Byte18:0, STS_XCP_RES_CTO_Byte19:0, STS_XCP_RES_CTO_Byte20:0, STS_XCP_RES_CTO_Byte21:0, STS_XCP_RES_CTO_Byte22:0, STS_XCP_RES_CTO_Byte23:0, STS_XCP_RES_CTO_Byte24:0, STS_XCP_RES_CTO_Byte25:0, STS_XCP_RES_CTO_Byte26:0, STS_XCP_RES_CTO_Byte27:0, STS_XCP_RES_CTO_Byte28:0, STS_XCP_RES_CTO_Byte29:0, STS_XCP_RES_CTO_Byte30:0, STS_XCP_RES_CTO_Byte31:0, STS_XCP_RES_CTO_Byte32:0, STS_XCP_RES_CTO_Byte33:0, STS_XCP_RES_CTO_Byte34:0, STS_XCP_RES_CTO_Byte35:0, STS_XCP_RES_CTO_Byte36:0, STS_XCP_RES_CTO_Byte37:0, STS_XCP_RES_CTO_Byte38:0, STS_XCP_RES_CTO_Byte39:0, STS_XCP_RES_CTO_Byte40:0, STS_XCP_RES_CTO_Byte41:0, STS_XCP_RES_CTO_Byte42:0, STS_XCP_RES_CTO_Byte43:0, STS_XCP_RES_CTO_Byte44:0, STS_XCP_RES_CTO_Byte45:0, STS_XCP_RES_CTO_Byte46:0, STS_XCP_RES_CTO_Byte47:0, STS_XCP_RES_CTO_Byte48:0, STS_XCP_RES_CTO_Byte49:0, STS_XCP_RES_CTO_Byte50:0, STS_XCP_RES_CTO_Byte51:0, STS_XCP_RES_CTO_Byte52:0, STS_XCP_RES_CTO_Byte53:0, STS_XCP_RES_CTO_Byte54:0, STS_XCP_RES_CTO_Byte55:0, STS_XCP_RES_CTO_Byte56:0, STS_XCP_RES_CTO_Byte57:0, STS_XCP_RES_CTO_Byte58:0, STS_XCP_RES_CTO_Byte59:0, STS_XCP_RES_CTO_Byte60:0, STS_XCP_RES_CTO_Byte61:0, STS_XCP_RES_CTO_Byte62:0, STS_XCP_RES_CTO_Byte63:0]}, provided-interface=Pi_SG_XcpCTOResp
      Pp_SG_XcpDAQResp: nonqueued-sender-com-spec{data-element=Vdp_SG_XcpDAQResp, init-value=fields=[STS_XCP_RES_DAQ_Byte0:0, STS_XCP_RES_DAQ_Byte1:0, STS_XCP_RES_DAQ_Byte2:0, STS_XCP_RES_DAQ_Byte3:0, STS_XCP_RES_DAQ_Byte4:0, STS_XCP_RES_DAQ_Byte5:0, STS_XCP_RES_DAQ_Byte6:0, STS_XCP_RES_DAQ_Byte7:0, STS_XCP_RES_DAQ_Byte8:0, STS_XCP_RES_DAQ_Byte9:0, STS_XCP_RES_DAQ_Byte10:0, STS_XCP_RES_DAQ_Byte11:0, STS_XCP_RES_DAQ_Byte12:0, STS_XCP_RES_DAQ_Byte13:0, STS_XCP_RES_DAQ_Byte14:0, STS_XCP_RES_DAQ_Byte15:0, STS_XCP_RES_DAQ_Byte16:0, STS_XCP_RES_DAQ_Byte17:0, STS_XCP_RES_DAQ_Byte18:0, STS_XCP_RES_DAQ_Byte19:0, STS_XCP_RES_DAQ_Byte20:0, STS_XCP_RES_DAQ_Byte21:0, STS_XCP_RES_DAQ_Byte22:0, STS_XCP_RES_DAQ_Byte23:0, STS_XCP_RES_DAQ_Byte24:0, STS_XCP_RES_DAQ_Byte25:0, STS_XCP_RES_DAQ_Byte26:0, STS_XCP_RES_DAQ_Byte27:0, STS_XCP_RES_DAQ_Byte28:0, STS_XCP_RES_DAQ_Byte29:0, STS_XCP_RES_DAQ_Byte30:0, STS_XCP_RES_DAQ_Byte31:0, STS_XCP_RES_DAQ_Byte32:0, STS_XCP_RES_DAQ_Byte33:0, STS_XCP_RES_DAQ_Byte34:0, STS_XCP_RES_DAQ_Byte35:0, STS_XCP_RES_DAQ_Byte36:0, STS_XCP_RES_DAQ_Byte37:0, STS_XCP_RES_DAQ_Byte38:0, STS_XCP_RES_DAQ_Byte39:0, STS_XCP_RES_DAQ_Byte40:0, STS_XCP_RES_DAQ_Byte41:0, STS_XCP_RES_DAQ_Byte42:0, STS_XCP_RES_DAQ_Byte43:0, STS_XCP_RES_DAQ_Byte44:0, STS_XCP_RES_DAQ_Byte45:0, STS_XCP_RES_DAQ_Byte46:0, STS_XCP_RES_DAQ_Byte47:0, STS_XCP_RES_DAQ_Byte48:0, STS_XCP_RES_DAQ_Byte49:0, STS_XCP_RES_DAQ_Byte50:0, STS_XCP_RES_DAQ_Byte51:0, STS_XCP_RES_DAQ_Byte52:0, STS_XCP_RES_DAQ_Byte53:0, STS_XCP_RES_DAQ_Byte54:0, STS_XCP_RES_DAQ_Byte55:0, STS_XCP_RES_DAQ_Byte56:0, STS_XCP_RES_DAQ_Byte57:0, STS_XCP_RES_DAQ_Byte58:0, STS_XCP_RES_DAQ_Byte59:0, STS_XCP_RES_DAQ_Byte60:0, STS_XCP_RES_DAQ_Byte61:0, STS_XCP_RES_DAQ_Byte62:0, STS_XCP_RES_DAQ_Byte63:0]}, provided-interface=Pi_SG_XcpDAQResp
    12 x require port:
      Rp_SG_VehicleStatus: nonqueued-receiver-com-spec{data-element=Vdp_SG_VehicleStatus, init-value=fields=[SSTS_CAN_PCAN_MAJOR_ADAS:0, SSTS_CAN_PCAN_MINOR_ADAS:0, SSTS_DRIVE_DIR:0, SSTS_DRIVE_REVERSE:0, SSTS_GEAR_POSITION:0, SSTS_IGN_STATUS:0, SSTS_LROS_DRIVE_DIR:0, SSTS_LROS_DRIVE_REVERSE:0, SSTS_MH_VS_CRC16:0, SSTS_MH_VS_CYCLE_COUNTER:0, SSTS_STEERING_ANGLE:0, SSTS_STEERING_ANGLE_SIGN:0, SSTS_SW_VERSION_ADAS:0, SSTS_VEH_AbsoluteTime_Day:1, SSTS_VEH_AbsoluteTime_Hour:0, SSTS_VEH_AbsoluteTime_Minute:0, SSTS_VEH_AbsoluteTime_Month:1, SSTS_VEH_AbsoluteTime_Second:0, SSTS_VEH_AbsoluteTime_Year:0, SSTS_VEH_ODOMETER:0, SSTS_VEH_POWER_MODE_STATUS:0, SSTS_VEH_SPD_COMP_FACTOR:0, SSTS_VEH_SYSTEM_VOLTAGE:0, SSTS_VEHICLE_SPEED_CALC:0, SSTS_VEHICLE_SPEED_CALC_QF:0, SSTS_VEHICLE_STATE:0, SSTS_YAW_RATE_BIAS:0, SSTS_YAW_RATE_CALC:448, SSTS_YAW_RATE_CALC_QF:0]}, required-interface=Pi_SG_VehicleStatus
      Rp_SG_XcpCTOReq: nonqueued-receiver-com-spec{data-element=Vdp_SG_XcpCTOReq, init-value=fields=[STS_PID:0, STS_XCP_REQ_CTO_Byte1:0, STS_XCP_REQ_CTO_Byte2:0, STS_XCP_REQ_CTO_Byte3:0, STS_XCP_REQ_CTO_Byte4:0, STS_XCP_REQ_CTO_Byte5:0, STS_XCP_REQ_CTO_Byte6:0, STS_XCP_REQ_CTO_Byte7:0, STS_XCP_REQ_CTO_Byte8:0, STS_XCP_REQ_CTO_Byte9:0, STS_XCP_REQ_CTO_Byte10:0, STS_XCP_REQ_CTO_Byte11:0, STS_XCP_REQ_CTO_Byte12:0, STS_XCP_REQ_CTO_Byte13:0, STS_XCP_REQ_CTO_Byte14:0, STS_XCP_REQ_CTO_Byte15:0, STS_XCP_REQ_CTO_Byte16:0, STS_XCP_REQ_CTO_Byte17:0, STS_XCP_REQ_CTO_Byte18:0, STS_XCP_REQ_CTO_Byte19:0, STS_XCP_REQ_CTO_Byte20:0, STS_XCP_REQ_CTO_Byte21:0, STS_XCP_REQ_CTO_Byte22:0, STS_XCP_REQ_CTO_Byte23:0, STS_XCP_REQ_CTO_Byte24:0, STS_XCP_REQ_CTO_Byte25:0, STS_XCP_REQ_CTO_Byte26:0, STS_XCP_REQ_CTO_Byte27:0, STS_XCP_REQ_CTO_Byte28:0, STS_XCP_REQ_CTO_Byte29:0, STS_XCP_REQ_CTO_Byte30:0, STS_XCP_REQ_CTO_Byte31:0, STS_XCP_REQ_CTO_Byte32:0, STS_XCP_REQ_CTO_Byte33:0, STS_XCP_REQ_CTO_Byte34:0, STS_XCP_REQ_CTO_Byte35:0, STS_XCP_REQ_CTO_Byte36:0, STS_XCP_REQ_CTO_Byte37:0, STS_XCP_REQ_CTO_Byte38:0, STS_XCP_REQ_CTO_Byte39:0, STS_XCP_REQ_CTO_Byte40:0, STS_XCP_REQ_CTO_Byte41:0, STS_XCP_REQ_CTO_Byte42:0, STS_XCP_REQ_CTO_Byte43:0, STS_XCP_REQ_CTO_Byte44:0, STS_XCP_REQ_CTO_Byte45:0, STS_XCP_REQ_CTO_Byte46:0, STS_XCP_REQ_CTO_Byte47:0, STS_XCP_REQ_CTO_Byte48:0, STS_XCP_REQ_CTO_Byte49:0, STS_XCP_REQ_CTO_Byte50:0, STS_XCP_REQ_CTO_Byte51:0, STS_XCP_REQ_CTO_Byte52:0, STS_XCP_REQ_CTO_Byte53:0, STS_XCP_REQ_CTO_Byte54:0, STS_XCP_REQ_CTO_Byte55:0, STS_XCP_REQ_CTO_Byte56:0, STS_XCP_REQ_CTO_Byte57:0, STS_XCP_REQ_CTO_Byte58:0, STS_XCP_REQ_CTO_Byte59:0, STS_XCP_REQ_CTO_Byte60:0, STS_XCP_REQ_CTO_Byte61:0, STS_XCP_REQ_CTO_Byte62:0, STS_XCP_REQ_CTO_Byte63:0]}, required-interface=Pi_SG_XcpCTOReq
      Rp_TSYN_OVS: nonqueued-receiver-com-spec{data-element=Vdp_TSYN_OVS, init-value=0}, required-interface=Pi_TSYN_OVS_2
      Rp_TSYN_PDU: nonqueued-receiver-com-spec{data-element=Vdp_TSYN_PDU, init-value=40}, required-interface=Pi_TSYN_PDU_2
      Rp_TSYN_RESERVED: nonqueued-receiver-com-spec{data-element=Vdp_TSYN_RESERVED, init-value=0}, required-interface=Pi_TSYN_RESERVED_2
      Rp_TSYN_SEQUENCE_COUNTER: nonqueued-receiver-com-spec{data-element=Vdp_TSYN_SEQUENCE_COUNTER, init-value=0}, required-interface=Pi_TSYN_SEQUENCE_COUNTER_2
      Rp_TSYN_SGW: nonqueued-receiver-com-spec{data-element=Vdp_TSYN_SGW, init-value=0}, required-interface=Pi_TSYN_SGW_2
      Rp_TSYN_SYNCTIME_NANOSEC: nonqueued-receiver-com-spec{data-element=Vdp_TSYN_SYNCTIME_NANOSEC, init-value=0}, required-interface=Pi_TSYN_SYNCTIME_NANOSEC_2
      Rp_TSYN_SYNCTIME_SEC: nonqueued-receiver-com-spec{data-element=Vdp_TSYN_SYNCTIME_SEC, init-value=0}, required-interface=Pi_TSYN_SYNCTIME_SEC_2
      Rp_TSYN_TIMEDOMAIN: nonqueued-receiver-com-spec{data-element=Vdp_TSYN_TIMEDOMAIN, init-value=0}, required-interface=Pi_TSYN_TIMEDOMAIN_2
      Rp_TSYN_USERBYTE: nonqueued-receiver-com-spec{data-element=Vdp_TSYN_USERBYTE, init-value=0}, required-interface=Pi_TSYN_USERBYTE_2
      Rp_TSYNC_CRC: nonqueued-receiver-com-spec{data-element=Vdp_TSYNC_CRC, init-value=0}, required-interface=Pi_TSYNC_CRC_2
    106 x provide port:
      Pp_HistoryFaultTable: nonqueued-sender-com-spec{data-element=De_HistoryFaultTable, init-value=constant-reference=C_Fault_T}, provided-interface=Pi_History_Fault_Table
      Pp_FaultTestCompleteTable: nonqueued-sender-com-spec{data-element=De_FaultTestCompleteTable, init-value=constant-reference=C_Fault_T}, provided-interface=Pi_Fault_Test_Complete_Table
      Pp_ActiveFaultTable: nonqueued-sender-com-spec{data-element=De_ActiveFaultTable, init-value=constant-reference=C_Fault_T}, provided-interface=Pi_Active_Fault_Table
      Pp_ActiveFaultLatchTable: nonqueued-sender-com-spec{data-element=De_ActiveFaultLatchTable, init-value=constant-reference=C_Fault_T}, provided-interface=Pi_Active_Fault_Latch_Table
      Pp_SG_AlignmentStatus1_AL: nonqueued-sender-com-spec{data-element=Vdp_SG_AlignmentStatus1_AL, init-value=fields=[AL_STS_001_CYCLE_COUNTER:0, AL_STS_001_MH_CRC16:0, STS_AAAzimuthStd:0, STS_AACurrentAzimuth:0, STS_AACurrentElevation:0, STS_AACurrentRoll:0, STS_AAElevationStd:0, STS_AARoll_Std:0, STS_AlignmentAutoStatus:0, STS_AlignmentAzimuth:0, STS_AlignmentElevation:0, STS_AlignmentError:0, STS_AlignmentModeIn:0, STS_AlignmentModeOut:0, STS_AutoAlignmentFailRootCause:5, STS_AzimuthErrorNegative:0, STS_AzimuthErrorPositive:0, STS_AzimuthStd:0, STS_AzimuthUpdates:0, STS_CalDisplay:0, STS_CalTime:0, STS_CoordinateSystemInput:0, STS_ElevationErrorNegative:0, STS_ElevationErrorPositive:0, STS_ElevationStd:0, STS_ElevationUpdates:0, STS_HostSpdCompensationFactorQF:0, STS_HostSpeedCompensationFactor:100, 0, 0, 0, 0, 100, 0, STS_ProgressPercent:0, STS_RadarTypeInput:0, STS_Roll_Updates:0, STS_RollErrorNegative:0, STS_RollErrorPositive:0, STS_StartAzimuth:0, STS_StartElevation:0, STS_StartRoll:0]}, provided-interface=Pi_SG_AlignmentStatus1_AL
      Pp_SG_AlignmentStatus2_AL: nonqueued-sender-com-spec{data-element=Vdp_SG_AlignmentStatus2_AL, init-value=fields=[AL_STS_002_CYCLE_COUNTER:0, AL_STS_002_MH_CRC16:0, STS_AlignmentServiceStatus:0, STS_AlignmentShortTrackStatus:0, STS_AlignmentStaticStatus:0, STS_AverageNumberOfDetections:0, STS_AverageSpeed:0, STS_DistanceAbsolute:0, STS_DistanceEffective:0, STS_DurationAbsolute:0, STS_DurationEffective:0, STS_ImpactByInterference:0, STS_Measured_Range:0, STS_MeasuredAmpSTD:0, STS_MeasuredRangeRate:0, STS_MeasuredRangeRateStd:0, STS_MeasuredRangeStd:0, STS_MeasuredRawAmplitude:0, STS_VehicleCondition:6]}, provided-interface=Pi_SG_AlignmentStatus2_AL
      Pp_SG_Detections_001_004_AL: nonqueued-sender-com-spec{data-element=Vdp_SG_Detections_001_004_AL, init-value=fields=[DET_AZIMUTH_001:0, DET_AZIMUTH_002:0, DET_AZIMUTH_003:0, DET_AZIMUTH_004:0, DET_AZIMUTH_ERR_001:0, DET_AZIMUTH_ERR_002:0, DET_AZIMUTH_ERR_003:0, DET_AZIMUTH_ERR_004:0, DET_BELOW_RAIN_THOLD_001:0, DET_BELOW_RAIN_THOLD_002:0, DET_BELOW_RAIN_THOLD_003:0, DET_BELOW_RAIN_THOLD_004:0, DET_BI_STATIC_FLAG_001:0, DET_BI_STATIC_FLAG_002:0, DET_BI_STATIC_FLAG_003:0, DET_BI_STATIC_FLAG_004:0, DET_CONFD_AZIMUTH_001:0, DET_CONFD_AZIMUTH_002:0, DET_CONFD_AZIMUTH_003:0, DET_CONFD_AZIMUTH_004:0, DET_CONFD_ELEVATION_001:0, DET_CONFD_ELEVATION_002:0, DET_CONFD_ELEVATION_003:0, DET_CONFD_ELEVATION_004:0, DET_ELEVATION_001:0, DET_ELEVATION_002:0, DET_ELEVATION_003:0, DET_ELEVATION_004:0, DET_ELEVATION_ERR_001:0, DET_ELEVATION_ERR_002:0, DET_ELEVATION_ERR_003:0, DET_ELEVATION_ERR_004:0, DET_EXISTENCE_PROB_001:0, DET_EXISTENCE_PROB_002:0, DET_EXISTENCE_PROB_003:0, DET_EXISTENCE_PROB_004:0, DET_HVC_FLAG_001:0, DET_HVC_FLAG_002:0, DET_HVC_FLAG_003:0, DET_HVC_FLAG_004:0, DET_IDM_001:0, DET_IDM_002:0, DET_IDM_003:0, DET_IDM_004:0, DET_MH_CRC16_001_004:0, DET_MH_CYCLE_COUNTER_001_004:0, DET_MH_SCAN_INDEX_4LSB_001_004:0, DET_MTD_001:0, DET_MTD_002:0, DET_MTD_003:0, DET_MTD_004:0, DET_PROB_1STAZHYPO_001:0, DET_PROB_1STAZHYPO_002:0, DET_PROB_1STAZHYPO_003:0, DET_PROB_1STAZHYPO_004:0, DET_RANGE_001:0, DET_RANGE_002:0, DET_RANGE_003:0, DET_RANGE_004:0, DET_RANGE_ERR_001:0, DET_RANGE_ERR_002:0, DET_RANGE_ERR_003:0, DET_RANGE_ERR_004:0, DET_RANGE_VELOCITY_001:16384, DET_RANGE_VELOCITY_002:16384, DET_RANGE_VELOCITY_003:16384, DET_RANGE_VELOCITY_004:16384, DET_RANGE_VELOCITY_ERR_001:0, DET_RANGE_VELOCITY_ERR_002:0, DET_RANGE_VELOCITY_ERR_003:0, DET_RANGE_VELOCITY_ERR_004:0, DET_RCS_001:128, DET_RCS_002:128, DET_RCS_003:128, DET_RCS_004:128, DET_SNR_001:0, DET_SNR_002:0, DET_SNR_003:0, DET_SNR_004:0, DET_SUPER_RES_TARGET_001:0, DET_SUPER_RES_TARGET_002:0, DET_SUPER_RES_TARGET_003:0, DET_SUPER_RES_TARGET_004:0]}, provided-interface=Pi_SG_Detections_001_004_AL
      Pp_SG_Detections_005_008_AL: nonqueued-sender-com-spec{data-element=Vdp_SG_Detections_005_008_AL, init-value=fields=[DET_AZIMUTH_005:0, DET_AZIMUTH_006:0, DET_AZIMUTH_007:0, DET_AZIMUTH_008:0, DET_AZIMUTH_ERR_005:0, DET_AZIMUTH_ERR_006:0, DET_AZIMUTH_ERR_007:0, DET_AZIMUTH_ERR_008:0, DET_BELOW_RAIN_THOLD_005:0, DET_BELOW_RAIN_THOLD_006:0, DET_BELOW_RAIN_THOLD_007:0, DET_BELOW_RAIN_THOLD_008:0, DET_BI_STATIC_FLAG_005:0, DET_BI_STATIC_FLAG_006:0, DET_BI_STATIC_FLAG_007:0, DET_BI_STATIC_FLAG_008:0, DET_CONFD_AZIMUTH_005:0, DET_CONFD_AZIMUTH_006:0, DET_CONFD_AZIMUTH_007:0, DET_CONFD_AZIMUTH_008:0, DET_CONFD_ELEVATION_005:0, DET_CONFD_ELEVATION_006:0, DET_CONFD_ELEVATION_007:0, DET_CONFD_ELEVATION_008:0, DET_ELEVATION_005:0, DET_ELEVATION_006:0, DET_ELEVATION_007:0, DET_ELEVATION_008:0, DET_ELEVATION_ERR_005:0, DET_ELEVATION_ERR_006:0, DET_ELEVATION_ERR_007:0, DET_ELEVATION_ERR_008:0, DET_EXISTENCE_PROB_005:0, DET_EXISTENCE_PROB_006:0, DET_EXISTENCE_PROB_007:0, DET_EXISTENCE_PROB_008:0, DET_HVC_FLAG_005:0, DET_HVC_FLAG_006:0, DET_HVC_FLAG_007:0, DET_HVC_FLAG_008:0, DET_IDM_005:0, DET_IDM_006:0, DET_IDM_007:0, DET_IDM_008:0, DET_MH_CRC16_005_008:0, DET_MH_CYCLE_COUNTER_005_008:0, DET_MH_SCAN_INDEX_4LSB_005_008:0, DET_MTD_005:0, DET_MTD_006:0, DET_MTD_007:0, DET_MTD_008:0, DET_PROB_1STAZHYPO_005:0, DET_PROB_1STAZHYPO_006:0, DET_PROB_1STAZHYPO_007:0, DET_PROB_1STAZHYPO_008:0, DET_RANGE_005:0, DET_RANGE_006:0, DET_RANGE_007:0, DET_RANGE_008:0, DET_RANGE_ERR_005:0, DET_RANGE_ERR_006:0, DET_RANGE_ERR_007:0, DET_RANGE_ERR_008:0, DET_RANGE_VELOCITY_005:16384, DET_RANGE_VELOCITY_006:16384, DET_RANGE_VELOCITY_007:16384, DET_RANGE_VELOCITY_008:16384, DET_RANGE_VELOCITY_ERR_005:0, DET_RANGE_VELOCITY_ERR_006:0, DET_RANGE_VELOCITY_ERR_007:0, DET_RANGE_VELOCITY_ERR_008:0, DET_RCS_005:128, DET_RCS_006:128, DET_RCS_007:128, DET_RCS_008:128, DET_SNR_005:0, DET_SNR_006:0, DET_SNR_007:0, DET_SNR_008:0, DET_SUPER_RES_TARGET_005:0, DET_SUPER_RES_TARGET_006:0, DET_SUPER_RES_TARGET_007:0, DET_SUPER_RES_TARGET_008:0]}, provided-interface=Pi_SG_Detections_005_008_AL
      Pp_SG_Detections_009_012_AL: nonqueued-sender-com-spec{data-element=Vdp_SG_Detections_009_012_AL, init-value=fields=[DET_AZIMUTH_009:0, DET_AZIMUTH_010:0, DET_AZIMUTH_011:0, DET_AZIMUTH_012:0, DET_AZIMUTH_ERR_009:0, DET_AZIMUTH_ERR_010:0, DET_AZIMUTH_ERR_011:0, DET_AZIMUTH_ERR_012:0, DET_BELOW_RAIN_THOLD_009:0, DET_BELOW_RAIN_THOLD_010:0, DET_BELOW_RAIN_THOLD_011:0, DET_BELOW_RAIN_THOLD_012:0, DET_BI_STATIC_FLAG_009:0, DET_BI_STATIC_FLAG_010:0, DET_BI_STATIC_FLAG_011:0, DET_BI_STATIC_FLAG_012:0, DET_CONFD_AZIMUTH_009:0, DET_CONFD_AZIMUTH_010:0, DET_CONFD_AZIMUTH_011:0, DET_CONFD_AZIMUTH_012:0, DET_CONFD_ELEVATION_009:0, DET_CONFD_ELEVATION_010:0, DET_CONFD_ELEVATION_011:0, DET_CONFD_ELEVATION_012:0, DET_ELEVATION_009:0, DET_ELEVATION_010:0, DET_ELEVATION_011:0, DET_ELEVATION_012:0, DET_ELEVATION_ERR_009:0, DET_ELEVATION_ERR_010:0, DET_ELEVATION_ERR_011:0, DET_ELEVATION_ERR_012:0, DET_EXISTENCE_PROB_009:0, DET_EXISTENCE_PROB_010:0, DET_EXISTENCE_PROB_011:0, DET_EXISTENCE_PROB_012:0, DET_HVC_FLAG_009:0, DET_HVC_FLAG_010:0, DET_HVC_FLAG_011:0, DET_HVC_FLAG_012:0, DET_IDM_009:0, DET_IDM_010:0, DET_IDM_011:0, DET_IDM_012:0, DET_MH_CRC16_009_012:0, DET_MH_CYCLE_COUNTER_009_012:0, DET_MH_SCAN_INDEX_4LSB_009_012:0, DET_MTD_009:0, DET_MTD_010:0, DET_MTD_011:0, DET_MTD_012:0, DET_PROB_1STAZHYPO_009:0, DET_PROB_1STAZHYPO_010:0, DET_PROB_1STAZHYPO_011:0, DET_PROB_1STAZHYPO_012:0, DET_RANGE_009:0, DET_RANGE_010:0, DET_RANGE_011:0, DET_RANGE_012:0, DET_RANGE_ERR_009:0, DET_RANGE_ERR_010:0, DET_RANGE_ERR_011:0, DET_RANGE_ERR_012:0, DET_RANGE_VELOCITY_009:16384, DET_RANGE_VELOCITY_010:16384, DET_RANGE_VELOCITY_011:16384, DET_RANGE_VELOCITY_012:16384, DET_RANGE_VELOCITY_ERR_009:0, DET_RANGE_VELOCITY_ERR_010:0, DET_RANGE_VELOCITY_ERR_011:0, DET_RANGE_VELOCITY_ERR_012:0, DET_RCS_009:128, DET_RCS_010:128, DET_RCS_011:128, DET_RCS_012:128, DET_SNR_009:0, DET_SNR_010:0, DET_SNR_011:0, DET_SNR_012:0, DET_SUPER_RES_TARGET_009:0, DET_SUPER_RES_TARGET_010:0, DET_SUPER_RES_TARGET_011:0, DET_SUPER_RES_TARGET_012:0]}, provided-interface=Pi_SG_Detections_009_012_AL
      Pp_SG_Detections_013_016_AL: nonqueued-sender-com-spec{data-element=Vdp_SG_Detections_013_016_AL, init-value=fields=[DET_AZIMUTH_013:0, DET_AZIMUTH_014:0, DET_AZIMUTH_015:0, DET_AZIMUTH_016:0, DET_AZIMUTH_ERR_013:0, DET_AZIMUTH_ERR_014:0, DET_AZIMUTH_ERR_015:0, DET_AZIMUTH_ERR_016:0, DET_BELOW_RAIN_THOLD_013:0, DET_BELOW_RAIN_THOLD_014:0, DET_BELOW_RAIN_THOLD_015:0, DET_BELOW_RAIN_THOLD_016:0, DET_BI_STATIC_FLAG_013:0, DET_BI_STATIC_FLAG_014:0, DET_BI_STATIC_FLAG_015:0, DET_BI_STATIC_FLAG_016:0, DET_CONFD_AZIMUTH_013:0, DET_CONFD_AZIMUTH_014:0, DET_CONFD_AZIMUTH_015:0, DET_CONFD_AZIMUTH_016:0, DET_CONFD_ELEVATION_013:0, DET_CONFD_ELEVATION_014:0, DET_CONFD_ELEVATION_015:0, DET_CONFD_ELEVATION_016:0, DET_ELEVATION_013:0, DET_ELEVATION_014:0, DET_ELEVATION_015:0, DET_ELEVATION_016:0, DET_ELEVATION_ERR_013:0, DET_ELEVATION_ERR_014:0, DET_ELEVATION_ERR_015:0, DET_ELEVATION_ERR_016:0, DET_EXISTENCE_PROB_013:0, DET_EXISTENCE_PROB_014:0, DET_EXISTENCE_PROB_015:0, DET_EXISTENCE_PROB_016:0, DET_HVC_FLAG_013:0, DET_HVC_FLAG_014:0, DET_HVC_FLAG_015:0, DET_HVC_FLAG_016:0, DET_IDM_013:0, DET_IDM_014:0, DET_IDM_015:0, DET_IDM_016:0, DET_MH_CRC16_013_016:0, DET_MH_CYCLE_COUNTER_013_016:0, DET_MH_SCAN_INDEX_4LSB_013_016:0, DET_MTD_013:0, DET_MTD_014:0, DET_MTD_015:0, DET_MTD_016:0, DET_PROB_1STAZHYPO_013:0, DET_PROB_1STAZHYPO_014:0, DET_PROB_1STAZHYPO_015:0, DET_PROB_1STAZHYPO_016:0, DET_RANGE_013:0, DET_RANGE_014:0, DET_RANGE_015:0, DET_RANGE_016:0, DET_RANGE_ERR_013:0, DET_RANGE_ERR_014:0, DET_RANGE_ERR_015:0, DET_RANGE_ERR_016:0, DET_RANGE_VELOCITY_013:16384, DET_RANGE_VELOCITY_014:16384, DET_RANGE_VELOCITY_015:16384, DET_RANGE_VELOCITY_016:16384, DET_RANGE_VELOCITY_ERR_013:0, DET_RANGE_VELOCITY_ERR_014:0, DET_RANGE_VELOCITY_ERR_015:0, DET_RANGE_VELOCITY_ERR_016:0, DET_RCS_013:128, DET_RCS_014:128, DET_RCS_015:128, DET_RCS_016:128, DET_SNR_013:0, DET_SNR_014:0, DET_SNR_015:0, DET_SNR_016:0, DET_SUPER_RES_TARGET_013:0, DET_SUPER_RES_TARGET_014:0, DET_SUPER_RES_TARGET_015:0, DET_SUPER_RES_TARGET_016:0]}, provided-interface=Pi_SG_Detections_013_016_AL
      Pp_SG_Detections_017_020_AL: nonqueued-sender-com-spec{data-element=Vdp_SG_Detections_017_020_AL, init-value=fields=[DET_AZIMUTH_017:0, DET_AZIMUTH_018:0, DET_AZIMUTH_019:0, DET_AZIMUTH_020:0, DET_AZIMUTH_ERR_017:0, DET_AZIMUTH_ERR_018:0, DET_AZIMUTH_ERR_019:0, DET_AZIMUTH_ERR_020:0, DET_BELOW_RAIN_THOLD_017:0, DET_BELOW_RAIN_THOLD_018:0, DET_BELOW_RAIN_THOLD_019:0, DET_BELOW_RAIN_THOLD_020:0, DET_BI_STATIC_FLAG_017:0, DET_BI_STATIC_FLAG_018:0, DET_BI_STATIC_FLAG_019:0, DET_BI_STATIC_FLAG_020:0, DET_CONFD_AZIMUTH_017:0, DET_CONFD_AZIMUTH_018:0, DET_CONFD_AZIMUTH_019:0, DET_CONFD_AZIMUTH_020:0, DET_CONFD_ELEVATION_017:0, DET_CONFD_ELEVATION_018:0, DET_CONFD_ELEVATION_019:0, DET_CONFD_ELEVATION_020:0, DET_ELEVATION_017:0, DET_ELEVATION_018:0, DET_ELEVATION_019:0, DET_ELEVATION_020:0, DET_ELEVATION_ERR_017:0, DET_ELEVATION_ERR_018:0, DET_ELEVATION_ERR_019:0, DET_ELEVATION_ERR_020:0, DET_EXISTENCE_PROB_017:0, DET_EXISTENCE_PROB_018:0, DET_EXISTENCE_PROB_019:0, DET_EXISTENCE_PROB_020:0, DET_HVC_FLAG_017:0, DET_HVC_FLAG_018:0, DET_HVC_FLAG_019:0, DET_HVC_FLAG_020:0, DET_IDM_017:0, DET_IDM_018:0, DET_IDM_019:0, DET_IDM_020:0, DET_MH_CRC16_017_020:0, DET_MH_CYCLE_COUNTER_017_020:0, DET_MH_SCAN_INDEX_4LSB_017_020:0, DET_MTD_017:0, DET_MTD_018:0, DET_MTD_019:0, DET_MTD_020:0, DET_PROB_1STAZHYPO_017:0, DET_PROB_1STAZHYPO_018:0, DET_PROB_1STAZHYPO_019:0, DET_PROB_1STAZHYPO_020:0, DET_RANGE_017:0, DET_RANGE_018:0, DET_RANGE_019:0, DET_RANGE_020:0, DET_RANGE_ERR_017:0, DET_RANGE_ERR_018:0, DET_RANGE_ERR_019:0, DET_RANGE_ERR_020:0, DET_RANGE_VELOCITY_017:16384, DET_RANGE_VELOCITY_018:16384, DET_RANGE_VELOCITY_019:16384, DET_RANGE_VELOCITY_020:16384, DET_RANGE_VELOCITY_ERR_017:0, DET_RANGE_VELOCITY_ERR_018:0, DET_RANGE_VELOCITY_ERR_019:0, DET_RANGE_VELOCITY_ERR_020:0, DET_RCS_017:128, DET_RCS_018:128, DET_RCS_019:128, DET_RCS_020:128, DET_SNR_017:0, DET_SNR_018:0, DET_SNR_019:0, DET_SNR_020:0, DET_SUPER_RES_TARGET_017:0, DET_SUPER_RES_TARGET_018:0, DET_SUPER_RES_TARGET_019:0, DET_SUPER_RES_TARGET_020:0]}, provided-interface=Pi_SG_Detections_017_020_AL
      Pp_SG_Detections_021_024_AL: nonqueued-sender-com-spec{data-element=Vdp_SG_Detections_021_024_AL, init-value=fields=[DET_AZIMUTH_021:0, DET_AZIMUTH_022:0, DET_AZIMUTH_023:0, DET_AZIMUTH_024:0, DET_AZIMUTH_ERR_021:0, DET_AZIMUTH_ERR_022:0, DET_AZIMUTH_ERR_023:0, DET_AZIMUTH_ERR_024:0, DET_BELOW_RAIN_THOLD_021:0, DET_BELOW_RAIN_THOLD_022:0, DET_BELOW_RAIN_THOLD_023:0, DET_BELOW_RAIN_THOLD_024:0, DET_BI_STATIC_FLAG_021:0, DET_BI_STATIC_FLAG_022:0, DET_BI_STATIC_FLAG_023:0, DET_BI_STATIC_FLAG_024:0, DET_CONFD_AZIMUTH_021:0, DET_CONFD_AZIMUTH_022:0, DET_CONFD_AZIMUTH_023:0, DET_CONFD_AZIMUTH_024:0, DET_CONFD_ELEVATION_021:0, DET_CONFD_ELEVATION_022:0, DET_CONFD_ELEVATION_023:0, DET_CONFD_ELEVATION_024:0, DET_ELEVATION_021:0, DET_ELEVATION_022:0, DET_ELEVATION_023:0, DET_ELEVATION_024:0, DET_ELEVATION_ERR_021:0, DET_ELEVATION_ERR_022:0, DET_ELEVATION_ERR_023:0, DET_ELEVATION_ERR_024:0, DET_EXISTENCE_PROB_021:0, DET_EXISTENCE_PROB_022:0, DET_EXISTENCE_PROB_023:0, DET_EXISTENCE_PROB_024:0, DET_HVC_FLAG_021:0, DET_HVC_FLAG_022:0, DET_HVC_FLAG_023:0, DET_HVC_FLAG_024:0, DET_IDM_021:0, DET_IDM_022:0, DET_IDM_023:0, DET_IDM_024:0, DET_MH_CRC16_021_024:0, DET_MH_CYCLE_COUNTER_021_024:0, DET_MH_SCAN_INDEX_4LSB_021_024:0, DET_MTD_021:0, DET_MTD_022:0, DET_MTD_023:0, DET_MTD_024:0, DET_PROB_1STAZHYPO_021:0, DET_PROB_1STAZHYPO_022:0, DET_PROB_1STAZHYPO_023:0, DET_PROB_1STAZHYPO_024:0, DET_RANGE_021:0, DET_RANGE_022:0, DET_RANGE_023:0, DET_RANGE_024:0, DET_RANGE_ERR_021:0, DET_RANGE_ERR_022:0, DET_RANGE_ERR_023:0, DET_RANGE_ERR_024:0, DET_RANGE_VELOCITY_021:16384, DET_RANGE_VELOCITY_022:16384, DET_RANGE_VELOCITY_023:16384, DET_RANGE_VELOCITY_024:16384, DET_RANGE_VELOCITY_ERR_021:0, DET_RANGE_VELOCITY_ERR_022:0, DET_RANGE_VELOCITY_ERR_023:0, DET_RANGE_VELOCITY_ERR_024:0, DET_RCS_021:128, DET_RCS_022:128, DET_RCS_023:128, DET_RCS_024:128, DET_SNR_021:0, DET_SNR_022:0, DET_SNR_023:0, DET_SNR_024:0, DET_SUPER_RES_TARGET_021:0, DET_SUPER_RES_TARGET_022:0, DET_SUPER_RES_TARGET_023:0, DET_SUPER_RES_TARGET_024:0]}, provided-interface=Pi_SG_Detections_021_024_AL
      Pp_SG_Detections_025_028_AL: nonqueued-sender-com-spec{data-element=Vdp_SG_Detections_025_028_AL, init-value=fields=[DET_AZIMUTH_025:0, DET_AZIMUTH_026:0, DET_AZIMUTH_027:0, DET_AZIMUTH_028:0, DET_AZIMUTH_ERR_025:0, DET_AZIMUTH_ERR_026:0, DET_AZIMUTH_ERR_027:0, DET_AZIMUTH_ERR_028:0, DET_BELOW_RAIN_THOLD_025:0, DET_BELOW_RAIN_THOLD_026:0, DET_BELOW_RAIN_THOLD_027:0, DET_BELOW_RAIN_THOLD_028:0, DET_BI_STATIC_FLAG_025:0, DET_BI_STATIC_FLAG_026:0, DET_BI_STATIC_FLAG_027:0, DET_BI_STATIC_FLAG_028:0, DET_CONFD_AZIMUTH_025:0, DET_CONFD_AZIMUTH_026:0, DET_CONFD_AZIMUTH_027:0, DET_CONFD_AZIMUTH_028:0, DET_CONFD_ELEVATION_025:0, DET_CONFD_ELEVATION_026:0, DET_CONFD_ELEVATION_027:0, DET_CONFD_ELEVATION_028:0, DET_ELEVATION_025:0, DET_ELEVATION_026:0, DET_ELEVATION_027:0, DET_ELEVATION_028:0, DET_ELEVATION_ERR_025:0, DET_ELEVATION_ERR_026:0, DET_ELEVATION_ERR_027:0, DET_ELEVATION_ERR_028:0, DET_EXISTENCE_PROB_025:0, DET_EXISTENCE_PROB_026:0, DET_EXISTENCE_PROB_027:0, DET_EXISTENCE_PROB_028:0, DET_HVC_FLAG_025:0, DET_HVC_FLAG_026:0, DET_HVC_FLAG_027:0, DET_HVC_FLAG_028:0, DET_IDM_025:0, DET_IDM_026:0, DET_IDM_027:0, DET_IDM_028:0, DET_MH_CRC16_025_028:0, DET_MH_CYCLE_COUNTER_025_028:0, DET_MH_SCAN_INDEX_4LSB_025_028:0, DET_MTD_025:0, DET_MTD_026:0, DET_MTD_027:0, DET_MTD_028:0, DET_PROB_1STAZHYPO_025:0, DET_PROB_1STAZHYPO_026:0, DET_PROB_1STAZHYPO_027:0, DET_PROB_1STAZHYPO_028:0, DET_RANGE_025:0, DET_RANGE_026:0, DET_RANGE_027:0, DET_RANGE_028:0, DET_RANGE_ERR_025:0, DET_RANGE_ERR_026:0, DET_RANGE_ERR_027:0, DET_RANGE_ERR_028:0, DET_RANGE_VELOCITY_025:16384, DET_RANGE_VELOCITY_026:16384, DET_RANGE_VELOCITY_027:16384, DET_RANGE_VELOCITY_028:16384, DET_RANGE_VELOCITY_ERR_025:0, DET_RANGE_VELOCITY_ERR_026:0, DET_RANGE_VELOCITY_ERR_027:0, DET_RANGE_VELOCITY_ERR_028:0, DET_RCS_025:128, DET_RCS_026:128, DET_RCS_027:128, DET_RCS_028:128, DET_SNR_025:0, DET_SNR_026:0, DET_SNR_027:0, DET_SNR_028:0, DET_SUPER_RES_TARGET_025:0, DET_SUPER_RES_TARGET_026:0, DET_SUPER_RES_TARGET_027:0, DET_SUPER_RES_TARGET_028:0]}, provided-interface=Pi_SG_Detections_025_028_AL
      Pp_SG_Detections_045_048_AL: nonqueued-sender-com-spec{data-element=Vdp_SG_Detections_045_048_AL, init-value=fields=[DET_AZIMUTH_045:0, DET_AZIMUTH_046:0, DET_AZIMUTH_047:0, DET_AZIMUTH_048:0, DET_AZIMUTH_ERR_045:0, DET_AZIMUTH_ERR_046:0, DET_AZIMUTH_ERR_047:0, DET_AZIMUTH_ERR_048:0, DET_BELOW_RAIN_THOLD_045:0, DET_BELOW_RAIN_THOLD_046:0, DET_BELOW_RAIN_THOLD_047:0, DET_BELOW_RAIN_THOLD_048:0, DET_BI_STATIC_FLAG_045:0, DET_BI_STATIC_FLAG_046:0, DET_BI_STATIC_FLAG_047:0, DET_BI_STATIC_FLAG_048:0, DET_CONFD_AZIMUTH_045:0, DET_CONFD_AZIMUTH_046:0, DET_CONFD_AZIMUTH_047:0, DET_CONFD_AZIMUTH_048:0, DET_CONFD_ELEVATION_045:0, DET_CONFD_ELEVATION_046:0, DET_CONFD_ELEVATION_047:0, DET_CONFD_ELEVATION_048:0, DET_ELEVATION_045:0, DET_ELEVATION_046:0, DET_ELEVATION_047:0, DET_ELEVATION_048:0, DET_ELEVATION_ERR_045:0, DET_ELEVATION_ERR_046:0, DET_ELEVATION_ERR_047:0, DET_ELEVATION_ERR_048:0, DET_EXISTENCE_PROB_045:0, DET_EXISTENCE_PROB_046:0, DET_EXISTENCE_PROB_047:0, DET_EXISTENCE_PROB_048:0, DET_HVC_FLAG_045:0, DET_HVC_FLAG_046:0, DET_HVC_FLAG_047:0, DET_HVC_FLAG_048:0, DET_IDM_045:0, DET_IDM_046:0, DET_IDM_047:0, DET_IDM_048:0, DET_MH_CRC16_045_048:0, DET_MH_CYCLE_COUNTER_045_048:0, DET_MH_SCAN_INDEX_4LSB_045_048:0, DET_MTD_045:0, DET_MTD_046:0, DET_MTD_047:0, DET_MTD_048:0, DET_PROB_1STAZHYPO_045:0, DET_PROB_1STAZHYPO_046:0, DET_PROB_1STAZHYPO_047:0, DET_PROB_1STAZHYPO_048:0, DET_RANGE_045:0, DET_RANGE_046:0, DET_RANGE_047:0, DET_RANGE_048:0, DET_RANGE_ERR_045:0, DET_RANGE_ERR_046:0, DET_RANGE_ERR_047:0, DET_RANGE_ERR_048:0, DET_RANGE_VELOCITY_045:16384, DET_RANGE_VELOCITY_046:16384, DET_RANGE_VELOCITY_047:16384, DET_RANGE_VELOCITY_048:16384, DET_RANGE_VELOCITY_ERR_045:0, DET_RANGE_VELOCITY_ERR_046:0, DET_RANGE_VELOCITY_ERR_047:0, DET_RANGE_VELOCITY_ERR_048:0, DET_RCS_045:128, DET_RCS_046:128, DET_RCS_047:128, DET_RCS_048:128, DET_SNR_045:0, DET_SNR_046:0, DET_SNR_047:0, DET_SNR_048:0, DET_SUPER_RES_TARGET_045:0, DET_SUPER_RES_TARGET_046:0, DET_SUPER_RES_TARGET_047:0, DET_SUPER_RES_TARGET_048:0]}, provided-interface=Pi_SG_Detections_045_048_AL
      Pp_SG_Detections_029_032_AL: nonqueued-sender-com-spec{data-element=Vdp_SG_Detections_029_032_AL, init-value=fields=[DET_AZIMUTH_029:0, DET_AZIMUTH_030:0, DET_AZIMUTH_031:0, DET_AZIMUTH_032:0, DET_AZIMUTH_ERR_029:0, DET_AZIMUTH_ERR_030:0, DET_AZIMUTH_ERR_031:0, DET_AZIMUTH_ERR_032:0, DET_BELOW_RAIN_THOLD_029:0, DET_BELOW_RAIN_THOLD_030:0, DET_BELOW_RAIN_THOLD_031:0, DET_BELOW_RAIN_THOLD_032:0, DET_BI_STATIC_FLAG_029:0, DET_BI_STATIC_FLAG_030:0, DET_BI_STATIC_FLAG_031:0, DET_BI_STATIC_FLAG_032:0, DET_CONFD_AZIMUTH_029:0, DET_CONFD_AZIMUTH_030:0, DET_CONFD_AZIMUTH_031:0, DET_CONFD_AZIMUTH_032:0, DET_CONFD_ELEVATION_029:0, DET_CONFD_ELEVATION_030:0, DET_CONFD_ELEVATION_031:0, DET_CONFD_ELEVATION_032:0, DET_ELEVATION_029:0, DET_ELEVATION_030:0, DET_ELEVATION_031:0, DET_ELEVATION_032:0, DET_ELEVATION_ERR_029:0, DET_ELEVATION_ERR_030:0, DET_ELEVATION_ERR_031:0, DET_ELEVATION_ERR_032:0, DET_EXISTENCE_PROB_029:0, DET_EXISTENCE_PROB_030:0, DET_EXISTENCE_PROB_031:0, DET_EXISTENCE_PROB_032:0, DET_HVC_FLAG_029:0, DET_HVC_FLAG_030:0, DET_HVC_FLAG_031:0, DET_HVC_FLAG_032:0, DET_IDM_029:0, DET_IDM_030:0, DET_IDM_031:0, DET_IDM_032:0, DET_MH_CRC16_029_032:0, DET_MH_CYCLE_COUNTER_029_032:0, DET_MH_SCAN_INDEX_4LSB_029_032:0, DET_MTD_029:0, DET_MTD_030:0, DET_MTD_031:0, DET_MTD_032:0, DET_PROB_1STAZHYPO_029:0, DET_PROB_1STAZHYPO_030:0, DET_PROB_1STAZHYPO_031:0, DET_PROB_1STAZHYPO_032:0, DET_RANGE_029:0, DET_RANGE_030:0, DET_RANGE_031:0, DET_RANGE_032:0, DET_RANGE_ERR_029:0, DET_RANGE_ERR_030:0, DET_RANGE_ERR_031:0, DET_RANGE_ERR_032:0, DET_RANGE_VELOCITY_029:16384, DET_RANGE_VELOCITY_030:16384, DET_RANGE_VELOCITY_031:16384, DET_RANGE_VELOCITY_032:16384, DET_RANGE_VELOCITY_ERR_029:0, DET_RANGE_VELOCITY_ERR_030:0, DET_RANGE_VELOCITY_ERR_031:0, DET_RANGE_VELOCITY_ERR_032:0, DET_RCS_029:128, DET_RCS_030:128, DET_RCS_031:128, DET_RCS_032:128, DET_SNR_029:0, DET_SNR_030:0, DET_SNR_031:0, DET_SNR_032:0, DET_SUPER_RES_TARGET_029:0, DET_SUPER_RES_TARGET_030:0, DET_SUPER_RES_TARGET_031:0, DET_SUPER_RES_TARGET_032:0]}, provided-interface=Pi_SG_Detections_029_032_AL
      Pp_SG_Detections_033_036_AL: nonqueued-sender-com-spec{data-element=Vdp_SG_Detections_033_036_AL, init-value=fields=[DET_AZIMUTH_033:0, DET_AZIMUTH_034:0, DET_AZIMUTH_035:0, DET_AZIMUTH_036:0, DET_AZIMUTH_ERR_033:0, DET_AZIMUTH_ERR_034:0, DET_AZIMUTH_ERR_035:0, DET_AZIMUTH_ERR_036:0, DET_BELOW_RAIN_THOLD_033:0, DET_BELOW_RAIN_THOLD_034:0, DET_BELOW_RAIN_THOLD_035:0, DET_BELOW_RAIN_THOLD_036:0, DET_BI_STATIC_FLAG_033:0, DET_BI_STATIC_FLAG_034:0, DET_BI_STATIC_FLAG_035:0, DET_BI_STATIC_FLAG_036:0, DET_CONFD_AZIMUTH_033:0, DET_CONFD_AZIMUTH_034:0, DET_CONFD_AZIMUTH_035:0, DET_CONFD_AZIMUTH_036:0, DET_CONFD_ELEVATION_033:0, DET_CONFD_ELEVATION_034:0, DET_CONFD_ELEVATION_035:0, DET_CONFD_ELEVATION_036:0, DET_ELEVATION_033:0, DET_ELEVATION_034:0, DET_ELEVATION_035:0, DET_ELEVATION_036:0, DET_ELEVATION_ERR_033:0, DET_ELEVATION_ERR_034:0, DET_ELEVATION_ERR_035:0, DET_ELEVATION_ERR_036:0, DET_EXISTENCE_PROB_033:0, DET_EXISTENCE_PROB_034:0, DET_EXISTENCE_PROB_035:0, DET_EXISTENCE_PROB_036:0, DET_HVC_FLAG_033:0, DET_HVC_FLAG_034:0, DET_HVC_FLAG_035:0, DET_HVC_FLAG_036:0, DET_IDM_033:0, DET_IDM_034:0, DET_IDM_035:0, DET_IDM_036:0, DET_MH_CRC16_033_036:0, DET_MH_CYCLE_COUNTER_033_036:0, DET_MH_SCAN_INDEX_4LSB_033_036:0, DET_MTD_033:0, DET_MTD_034:0, DET_MTD_035:0, DET_MTD_036:0, DET_PROB_1STAZHYPO_033:0, DET_PROB_1STAZHYPO_034:0, DET_PROB_1STAZHYPO_035:0, DET_PROB_1STAZHYPO_036:0, DET_RANGE_033:0, DET_RANGE_034:0, DET_RANGE_035:0, DET_RANGE_036:0, DET_RANGE_ERR_033:0, DET_RANGE_ERR_034:0, DET_RANGE_ERR_035:0, DET_RANGE_ERR_036:0, DET_RANGE_VELOCITY_033:16384, DET_RANGE_VELOCITY_034:16384, DET_RANGE_VELOCITY_035:16384, DET_RANGE_VELOCITY_036:16384, DET_RANGE_VELOCITY_ERR_033:0, DET_RANGE_VELOCITY_ERR_034:0, DET_RANGE_VELOCITY_ERR_035:0, DET_RANGE_VELOCITY_ERR_036:0, DET_RCS_033:128, DET_RCS_034:128, DET_RCS_035:128, DET_RCS_036:128, DET_SNR_033:0, DET_SNR_034:0, DET_SNR_035:0, DET_SNR_036:0, DET_SUPER_RES_TARGET_033:0, DET_SUPER_RES_TARGET_034:0, DET_SUPER_RES_TARGET_035:0, DET_SUPER_RES_TARGET_036:0]}, provided-interface=Pi_SG_Detections_033_036_AL
      Pp_SG_Detections_037_040_AL: nonqueued-sender-com-spec{data-element=Vdp_SG_Detections_037_040_AL, init-value=fields=[DET_AZIMUTH_037:0, DET_AZIMUTH_038:0, DET_AZIMUTH_039:0, DET_AZIMUTH_040:0, DET_AZIMUTH_ERR_037:0, DET_AZIMUTH_ERR_038:0, DET_AZIMUTH_ERR_039:0, DET_AZIMUTH_ERR_040:0, DET_BELOW_RAIN_THOLD_037:0, DET_BELOW_RAIN_THOLD_038:0, DET_BELOW_RAIN_THOLD_039:0, DET_BELOW_RAIN_THOLD_040:0, DET_BI_STATIC_FLAG_037:0, DET_BI_STATIC_FLAG_038:0, DET_BI_STATIC_FLAG_039:0, DET_BI_STATIC_FLAG_040:0, DET_CONFD_AZIMUTH_037:0, DET_CONFD_AZIMUTH_038:0, DET_CONFD_AZIMUTH_039:0, DET_CONFD_AZIMUTH_040:0, DET_CONFD_ELEVATION_037:0, DET_CONFD_ELEVATION_038:0, DET_CONFD_ELEVATION_039:0, DET_CONFD_ELEVATION_040:0, DET_ELEVATION_037:0, DET_ELEVATION_038:0, DET_ELEVATION_039:0, DET_ELEVATION_040:0, DET_ELEVATION_ERR_037:0, DET_ELEVATION_ERR_038:0, DET_ELEVATION_ERR_039:0, DET_ELEVATION_ERR_040:0, DET_EXISTENCE_PROB_037:0, DET_EXISTENCE_PROB_038:0, DET_EXISTENCE_PROB_039:0, DET_EXISTENCE_PROB_040:0, DET_HVC_FLAG_037:0, DET_HVC_FLAG_038:0, DET_HVC_FLAG_039:0, DET_HVC_FLAG_040:0, DET_IDM_037:0, DET_IDM_038:0, DET_IDM_039:0, DET_IDM_040:0, DET_MH_CRC16_037_040:0, DET_MH_CYCLE_COUNTER_037_040:0, DET_MH_SCAN_INDEX_4LSB_037_040:0, DET_MTD_037:0, DET_MTD_038:0, DET_MTD_039:0, DET_MTD_040:0, DET_PROB_1STAZHYPO_037:0, DET_PROB_1STAZHYPO_038:0, DET_PROB_1STAZHYPO_039:0, DET_PROB_1STAZHYPO_040:0, DET_RANGE_037:0, DET_RANGE_038:0, DET_RANGE_039:0, DET_RANGE_040:0, DET_RANGE_ERR_037:0, DET_RANGE_ERR_038:0, DET_RANGE_ERR_039:0, DET_RANGE_ERR_040:0, DET_RANGE_VELOCITY_037:16384, DET_RANGE_VELOCITY_038:16384, DET_RANGE_VELOCITY_039:16384, DET_RANGE_VELOCITY_040:16384, DET_RANGE_VELOCITY_ERR_037:0, DET_RANGE_VELOCITY_ERR_038:0, DET_RANGE_VELOCITY_ERR_039:0, DET_RANGE_VELOCITY_ERR_040:0, DET_RCS_037:128, DET_RCS_038:128, DET_RCS_039:128, DET_RCS_040:128, DET_SNR_037:0, DET_SNR_038:0, DET_SNR_039:0, DET_SNR_040:0, DET_SUPER_RES_TARGET_037:0, DET_SUPER_RES_TARGET_038:0, DET_SUPER_RES_TARGET_039:0, DET_SUPER_RES_TARGET_040:0]}, provided-interface=Pi_SG_Detections_037_040_AL
      Pp_SG_Detections_041_044_AL: nonqueued-sender-com-spec{data-element=Vdp_SG_Detections_041_044_AL, init-value=fields=[DET_AZIMUTH_041:0, DET_AZIMUTH_042:0, DET_AZIMUTH_043:0, DET_AZIMUTH_044:0, DET_AZIMUTH_ERR_041:0, DET_AZIMUTH_ERR_042:0, DET_AZIMUTH_ERR_043:0, DET_AZIMUTH_ERR_044:0, DET_BELOW_RAIN_THOLD_041:0, DET_BELOW_RAIN_THOLD_042:0, DET_BELOW_RAIN_THOLD_043:0, DET_BELOW_RAIN_THOLD_044:0, DET_BI_STATIC_FLAG_041:0, DET_BI_STATIC_FLAG_042:0, DET_BI_STATIC_FLAG_043:0, DET_BI_STATIC_FLAG_044:0, DET_CONFD_AZIMUTH_041:0, DET_CONFD_AZIMUTH_042:0, DET_CONFD_AZIMUTH_043:0, DET_CONFD_AZIMUTH_044:0, DET_CONFD_ELEVATION_041:0, DET_CONFD_ELEVATION_042:0, DET_CONFD_ELEVATION_043:0, DET_CONFD_ELEVATION_044:0, DET_ELEVATION_041:0, DET_ELEVATION_042:0, DET_ELEVATION_043:0, DET_ELEVATION_044:0, DET_ELEVATION_ERR_041:0, DET_ELEVATION_ERR_042:0, DET_ELEVATION_ERR_043:0, DET_ELEVATION_ERR_044:0, DET_EXISTENCE_PROB_041:0, DET_EXISTENCE_PROB_042:0, DET_EXISTENCE_PROB_043:0, DET_EXISTENCE_PROB_044:0, DET_HVC_FLAG_041:0, DET_HVC_FLAG_042:0, DET_HVC_FLAG_043:0, DET_HVC_FLAG_044:0, DET_IDM_041:0, DET_IDM_042:0, DET_IDM_043:0, DET_IDM_044:0, DET_MH_CRC16_041_044:0, DET_MH_CYCLE_COUNTER_041_044:0, DET_MH_SCAN_INDEX_4LSB_041_044:0, DET_MTD_041:0, DET_MTD_042:0, DET_MTD_043:0, DET_MTD_044:0, DET_PROB_1STAZHYPO_041:0, DET_PROB_1STAZHYPO_042:0, DET_PROB_1STAZHYPO_043:0, DET_PROB_1STAZHYPO_044:0, DET_RANGE_041:0, DET_RANGE_042:0, DET_RANGE_043:0, DET_RANGE_044:0, DET_RANGE_ERR_041:0, DET_RANGE_ERR_042:0, DET_RANGE_ERR_043:0, DET_RANGE_ERR_044:0, DET_RANGE_VELOCITY_041:16384, DET_RANGE_VELOCITY_042:16384, DET_RANGE_VELOCITY_043:16384, DET_RANGE_VELOCITY_044:16384, DET_RANGE_VELOCITY_ERR_041:0, DET_RANGE_VELOCITY_ERR_042:0, DET_RANGE_VELOCITY_ERR_043:0, DET_RANGE_VELOCITY_ERR_044:0, DET_RCS_041:128, DET_RCS_042:128, DET_RCS_043:128, DET_RCS_044:128, DET_SNR_041:0, DET_SNR_042:0, DET_SNR_043:0, DET_SNR_044:0, DET_SUPER_RES_TARGET_041:0, DET_SUPER_RES_TARGET_042:0, DET_SUPER_RES_TARGET_043:0, DET_SUPER_RES_TARGET_044:0]}, provided-interface=Pi_SG_Detections_041_044_AL
      Pp_SG_Detections_097_100_AL: nonqueued-sender-com-spec{data-element=Vdp_SG_Detections_097_100_AL, init-value=fields=[DET_AZIMUTH_097:0, DET_AZIMUTH_098:0, DET_AZIMUTH_099:0, DET_AZIMUTH_100:0, DET_AZIMUTH_ERR_097:0, DET_AZIMUTH_ERR_098:0, DET_AZIMUTH_ERR_099:0, DET_AZIMUTH_ERR_100:0, DET_BELOW_RAIN_THOLD_097:0, DET_BELOW_RAIN_THOLD_098:0, DET_BELOW_RAIN_THOLD_099:0, DET_BELOW_RAIN_THOLD_100:0, DET_BI_STATIC_FLAG_097:0, DET_BI_STATIC_FLAG_098:0, DET_BI_STATIC_FLAG_099:0, DET_BI_STATIC_FLAG_100:0, DET_CONFD_AZIMUTH_097:0, DET_CONFD_AZIMUTH_098:0, DET_CONFD_AZIMUTH_099:0, DET_CONFD_AZIMUTH_100:0, DET_CONFD_ELEVATION_097:0, DET_CONFD_ELEVATION_098:0, DET_CONFD_ELEVATION_099:0, DET_CONFD_ELEVATION_100:0, DET_ELEVATION_097:0, DET_ELEVATION_098:0, DET_ELEVATION_099:0, DET_ELEVATION_100:0, DET_ELEVATION_ERR_097:0, DET_ELEVATION_ERR_098:0, DET_ELEVATION_ERR_099:0, DET_ELEVATION_ERR_100:0, DET_EXISTENCE_PROB_097:0, DET_EXISTENCE_PROB_098:0, DET_EXISTENCE_PROB_099:0, DET_EXISTENCE_PROB_100:0, DET_HVC_FLAG_097:0, DET_HVC_FLAG_098:0, DET_HVC_FLAG_099:0, DET_HVC_FLAG_100:0, DET_IDM_097:0, DET_IDM_098:0, DET_IDM_099:0, DET_IDM_100:0, DET_MH_CRC16_097_100:0, DET_MH_CYCLE_COUNTER_097_100:0, DET_MH_SCAN_INDEX_4LSB_097_100:0, DET_MTD_097:0, DET_MTD_098:0, DET_MTD_099:0, DET_MTD_100:0, DET_PROB_1STAZHYPO_097:0, DET_PROB_1STAZHYPO_098:0, DET_PROB_1STAZHYPO_099:0, DET_PROB_1STAZHYPO_100:0, DET_RANGE_097:0, DET_RANGE_098:0, DET_RANGE_099:0, DET_RANGE_100:0, DET_RANGE_ERR_097:0, DET_RANGE_ERR_098:0, DET_RANGE_ERR_099:0, DET_RANGE_ERR_100:0, DET_RANGE_VELOCITY_097:16384, DET_RANGE_VELOCITY_098:16384, DET_RANGE_VELOCITY_099:16384, DET_RANGE_VELOCITY_100:16384, DET_RANGE_VELOCITY_ERR_097:0, DET_RANGE_VELOCITY_ERR_098:0, DET_RANGE_VELOCITY_ERR_099:0, DET_RANGE_VELOCITY_ERR_100:0, DET_RCS_097:128, DET_RCS_098:128, DET_RCS_099:128, DET_RCS_100:128, DET_SNR_097:0, DET_SNR_098:0, DET_SNR_099:0, DET_SNR_100:0, DET_SUPER_RES_TARGET_097:0, DET_SUPER_RES_TARGET_098:0, DET_SUPER_RES_TARGET_099:0, DET_SUPER_RES_TARGET_100:0]}, provided-interface=Pi_SG_Detections_097_100_AL
      Pp_SG_Detections_049_052_AL: nonqueued-sender-com-spec{data-element=Vdp_SG_Detections_049_052_AL, init-value=fields=[DET_AZIMUTH_049:0, DET_AZIMUTH_050:0, DET_AZIMUTH_051:0, DET_AZIMUTH_052:0, DET_AZIMUTH_ERR_049:0, DET_AZIMUTH_ERR_050:0, DET_AZIMUTH_ERR_051:0, DET_AZIMUTH_ERR_052:0, DET_BELOW_RAIN_THOLD_049:0, DET_BELOW_RAIN_THOLD_050:0, DET_BELOW_RAIN_THOLD_051:0, DET_BELOW_RAIN_THOLD_052:0, DET_BI_STATIC_FLAG_049:0, DET_BI_STATIC_FLAG_050:0, DET_BI_STATIC_FLAG_051:0, DET_BI_STATIC_FLAG_052:0, DET_CONFD_AZIMUTH_049:0, DET_CONFD_AZIMUTH_050:0, DET_CONFD_AZIMUTH_051:0, DET_CONFD_AZIMUTH_052:0, DET_CONFD_ELEVATION_049:0, DET_CONFD_ELEVATION_050:0, DET_CONFD_ELEVATION_051:0, DET_CONFD_ELEVATION_052:0, DET_ELEVATION_049:0, DET_ELEVATION_050:0, DET_ELEVATION_051:0, DET_ELEVATION_052:0, DET_ELEVATION_ERR_049:0, DET_ELEVATION_ERR_050:0, DET_ELEVATION_ERR_051:0, DET_ELEVATION_ERR_052:0, DET_EXISTENCE_PROB_049:0, DET_EXISTENCE_PROB_050:0, DET_EXISTENCE_PROB_051:0, DET_EXISTENCE_PROB_052:0, DET_HVC_FLAG_049:0, DET_HVC_FLAG_050:0, DET_HVC_FLAG_051:0, DET_HVC_FLAG_052:0, DET_IDM_049:0, DET_IDM_050:0, DET_IDM_051:0, DET_IDM_052:0, DET_MH_CRC16_049_052:0, DET_MH_CYCLE_COUNTER_049_052:0, DET_MH_SCAN_INDEX_4LSB_049_052:0, DET_MTD_049:0, DET_MTD_050:0, DET_MTD_051:0, DET_MTD_052:0, DET_PROB_1STAZHYPO_049:0, DET_PROB_1STAZHYPO_050:0, DET_PROB_1STAZHYPO_051:0, DET_PROB_1STAZHYPO_052:0, DET_RANGE_049:0, DET_RANGE_050:0, DET_RANGE_051:0, DET_RANGE_052:0, DET_RANGE_ERR_049:0, DET_RANGE_ERR_050:0, DET_RANGE_ERR_051:0, DET_RANGE_ERR_052:0, DET_RANGE_VELOCITY_049:16384, DET_RANGE_VELOCITY_050:16384, DET_RANGE_VELOCITY_051:16384, DET_RANGE_VELOCITY_052:16384, DET_RANGE_VELOCITY_ERR_049:0, DET_RANGE_VELOCITY_ERR_050:0, DET_RANGE_VELOCITY_ERR_051:0, DET_RANGE_VELOCITY_ERR_052:0, DET_RCS_049:128, DET_RCS_050:128, DET_RCS_051:128, DET_RCS_052:128, DET_SNR_049:0, DET_SNR_050:0, DET_SNR_051:0, DET_SNR_052:0, DET_SUPER_RES_TARGET_049:0, DET_SUPER_RES_TARGET_050:0, DET_SUPER_RES_TARGET_051:0, DET_SUPER_RES_TARGET_052:0]}, provided-interface=Pi_SG_Detections_049_052_AL
      Pp_SG_Detections_053_056_AL: nonqueued-sender-com-spec{data-element=Vdp_SG_Detections_053_056_AL, init-value=fields=[DET_AZIMUTH_053:0, DET_AZIMUTH_054:0, DET_AZIMUTH_055:0, DET_AZIMUTH_056:0, DET_AZIMUTH_ERR_053:0, DET_AZIMUTH_ERR_054:0, DET_AZIMUTH_ERR_055:0, DET_AZIMUTH_ERR_056:0, DET_BELOW_RAIN_THOLD_053:0, DET_BELOW_RAIN_THOLD_054:0, DET_BELOW_RAIN_THOLD_055:0, DET_BELOW_RAIN_THOLD_056:0, DET_BI_STATIC_FLAG_053:0, DET_BI_STATIC_FLAG_054:0, DET_BI_STATIC_FLAG_055:0, DET_BI_STATIC_FLAG_056:0, DET_CONFD_AZIMUTH_053:0, DET_CONFD_AZIMUTH_054:0, DET_CONFD_AZIMUTH_055:0, DET_CONFD_AZIMUTH_056:0, DET_CONFD_ELEVATION_053:0, DET_CONFD_ELEVATION_054:0, DET_CONFD_ELEVATION_055:0, DET_CONFD_ELEVATION_056:0, DET_ELEVATION_053:0, DET_ELEVATION_054:0, DET_ELEVATION_055:0, DET_ELEVATION_056:0, DET_ELEVATION_ERR_053:0, DET_ELEVATION_ERR_054:0, DET_ELEVATION_ERR_055:0, DET_ELEVATION_ERR_056:0, DET_EXISTENCE_PROB_053:0, DET_EXISTENCE_PROB_054:0, DET_EXISTENCE_PROB_055:0, DET_EXISTENCE_PROB_056:0, DET_HVC_FLAG_053:0, DET_HVC_FLAG_054:0, DET_HVC_FLAG_055:0, DET_HVC_FLAG_056:0, DET_IDM_053:0, DET_IDM_054:0, DET_IDM_055:0, DET_IDM_056:0, DET_MH_CRC16_053_056:0, DET_MH_CYCLE_COUNTER_053_056:0, DET_MH_SCAN_INDEX_4LSB_053_056:0, DET_MTD_053:0, DET_MTD_054:0, DET_MTD_055:0, DET_MTD_056:0, DET_PROB_1STAZHYPO_053:0, DET_PROB_1STAZHYPO_054:0, DET_PROB_1STAZHYPO_055:0, DET_PROB_1STAZHYPO_056:0, DET_RANGE_053:0, DET_RANGE_054:0, DET_RANGE_055:0, DET_RANGE_056:0, DET_RANGE_ERR_053:0, DET_RANGE_ERR_054:0, DET_RANGE_ERR_055:0, DET_RANGE_ERR_056:0, DET_RANGE_VELOCITY_053:16384, DET_RANGE_VELOCITY_054:16384, DET_RANGE_VELOCITY_055:16384, DET_RANGE_VELOCITY_056:16384, DET_RANGE_VELOCITY_ERR_053:0, DET_RANGE_VELOCITY_ERR_054:0, DET_RANGE_VELOCITY_ERR_055:0, DET_RANGE_VELOCITY_ERR_056:0, DET_RCS_053:128, DET_RCS_054:128, DET_RCS_055:128, DET_RCS_056:128, DET_SNR_053:0, DET_SNR_054:0, DET_SNR_055:0, DET_SNR_056:0, DET_SUPER_RES_TARGET_053:0, DET_SUPER_RES_TARGET_054:0, DET_SUPER_RES_TARGET_055:0, DET_SUPER_RES_TARGET_056:0]}, provided-interface=Pi_SG_Detections_053_056_AL
      Pp_SG_Detections_057_060_AL: nonqueued-sender-com-spec{data-element=Vdp_SG_Detections_057_060_AL, init-value=fields=[DET_AZIMUTH_057:0, DET_AZIMUTH_058:0, DET_AZIMUTH_059:0, DET_AZIMUTH_060:0, DET_AZIMUTH_ERR_057:0, DET_AZIMUTH_ERR_058:0, DET_AZIMUTH_ERR_059:0, DET_AZIMUTH_ERR_060:0, DET_BELOW_RAIN_THOLD_057:0, DET_BELOW_RAIN_THOLD_058:0, DET_BELOW_RAIN_THOLD_059:0, DET_BELOW_RAIN_THOLD_060:0, DET_BI_STATIC_FLAG_057:0, DET_BI_STATIC_FLAG_058:0, DET_BI_STATIC_FLAG_059:0, DET_BI_STATIC_FLAG_060:0, DET_CONFD_AZIMUTH_057:0, DET_CONFD_AZIMUTH_058:0, DET_CONFD_AZIMUTH_059:0, DET_CONFD_AZIMUTH_060:0, DET_CONFD_ELEVATION_057:0, DET_CONFD_ELEVATION_058:0, DET_CONFD_ELEVATION_059:0, DET_CONFD_ELEVATION_060:0, DET_ELEVATION_057:0, DET_ELEVATION_058:0, DET_ELEVATION_059:0, DET_ELEVATION_060:0, DET_ELEVATION_ERR_057:0, DET_ELEVATION_ERR_058:0, DET_ELEVATION_ERR_059:0, DET_ELEVATION_ERR_060:0, DET_EXISTENCE_PROB_057:0, DET_EXISTENCE_PROB_058:0, DET_EXISTENCE_PROB_059:0, DET_EXISTENCE_PROB_060:0, DET_HVC_FLAG_057:0, DET_HVC_FLAG_058:0, DET_HVC_FLAG_059:0, DET_HVC_FLAG_060:0, DET_IDM_057:0, DET_IDM_058:0, DET_IDM_059:0, DET_IDM_060:0, DET_MH_CRC16_057_060:0, DET_MH_CYCLE_COUNTER_057_060:0, DET_MH_SCAN_INDEX_4LSB_057_060:0, DET_MTD_057:0, DET_MTD_058:0, DET_MTD_059:0, DET_MTD_060:0, DET_PROB_1STAZHYPO_057:0, DET_PROB_1STAZHYPO_058:0, DET_PROB_1STAZHYPO_059:0, DET_PROB_1STAZHYPO_060:0, DET_RANGE_057:0, DET_RANGE_058:0, DET_RANGE_059:0, DET_RANGE_060:0, DET_RANGE_ERR_057:0, DET_RANGE_ERR_058:0, DET_RANGE_ERR_059:0, DET_RANGE_ERR_060:0, DET_RANGE_VELOCITY_057:16384, DET_RANGE_VELOCITY_058:16384, DET_RANGE_VELOCITY_059:16384, DET_RANGE_VELOCITY_060:16384, DET_RANGE_VELOCITY_ERR_057:0, DET_RANGE_VELOCITY_ERR_058:0, DET_RANGE_VELOCITY_ERR_059:0, DET_RANGE_VELOCITY_ERR_060:0, DET_RCS_057:128, DET_RCS_058:128, DET_RCS_059:128, DET_RCS_060:128, DET_SNR_057:0, DET_SNR_058:0, DET_SNR_059:0, DET_SNR_060:0, DET_SUPER_RES_TARGET_057:0, DET_SUPER_RES_TARGET_058:0, DET_SUPER_RES_TARGET_059:0, DET_SUPER_RES_TARGET_060:0]}, provided-interface=Pi_SG_Detections_057_060_AL
      Pp_SG_Detections_061_064_AL: nonqueued-sender-com-spec{data-element=Vdp_SG_Detections_061_064_AL, init-value=fields=[DET_AZIMUTH_061:0, DET_AZIMUTH_062:0, DET_AZIMUTH_063:0, DET_AZIMUTH_064:0, DET_AZIMUTH_ERR_061:0, DET_AZIMUTH_ERR_062:0, DET_AZIMUTH_ERR_063:0, DET_AZIMUTH_ERR_064:0, DET_BELOW_RAIN_THOLD_061:0, DET_BELOW_RAIN_THOLD_062:0, DET_BELOW_RAIN_THOLD_063:0, DET_BELOW_RAIN_THOLD_064:0, DET_BI_STATIC_FLAG_061:0, DET_BI_STATIC_FLAG_062:0, DET_BI_STATIC_FLAG_063:0, DET_BI_STATIC_FLAG_064:0, DET_CONFD_AZIMUTH_061:0, DET_CONFD_AZIMUTH_062:0, DET_CONFD_AZIMUTH_063:0, DET_CONFD_AZIMUTH_064:0, DET_CONFD_ELEVATION_061:0, DET_CONFD_ELEVATION_062:0, DET_CONFD_ELEVATION_063:0, DET_CONFD_ELEVATION_064:0, DET_ELEVATION_061:0, DET_ELEVATION_062:0, DET_ELEVATION_063:0, DET_ELEVATION_064:0, DET_ELEVATION_ERR_061:0, DET_ELEVATION_ERR_062:0, DET_ELEVATION_ERR_063:0, DET_ELEVATION_ERR_064:0, DET_EXISTENCE_PROB_061:0, DET_EXISTENCE_PROB_062:0, DET_EXISTENCE_PROB_063:0, DET_EXISTENCE_PROB_064:0, DET_HVC_FLAG_061:0, DET_HVC_FLAG_062:0, DET_HVC_FLAG_063:0, DET_HVC_FLAG_064:0, DET_IDM_061:0, DET_IDM_062:0, DET_IDM_063:0, DET_IDM_064:0, DET_MH_CRC16_061_064:0, DET_MH_CYCLE_COUNTER_061_064:0, DET_MH_SCAN_INDEX_4LSB_061_064:0, DET_MTD_061:0, DET_MTD_062:0, DET_MTD_063:0, DET_MTD_064:0, DET_PROB_1STAZHYPO_061:0, DET_PROB_1STAZHYPO_062:0, DET_PROB_1STAZHYPO_063:0, DET_PROB_1STAZHYPO_064:0, DET_RANGE_061:0, DET_RANGE_062:0, DET_RANGE_063:0, DET_RANGE_064:0, DET_RANGE_ERR_061:0, DET_RANGE_ERR_062:0, DET_RANGE_ERR_063:0, DET_RANGE_ERR_064:0, DET_RANGE_VELOCITY_061:16384, DET_RANGE_VELOCITY_062:16384, DET_RANGE_VELOCITY_063:16384, DET_RANGE_VELOCITY_064:16384, DET_RANGE_VELOCITY_ERR_061:0, DET_RANGE_VELOCITY_ERR_062:0, DET_RANGE_VELOCITY_ERR_063:0, DET_RANGE_VELOCITY_ERR_064:0, DET_RCS_061:128, DET_RCS_062:128, DET_RCS_063:128, DET_RCS_064:128, DET_SNR_061:0, DET_SNR_062:0, DET_SNR_063:0, DET_SNR_064:0, DET_SUPER_RES_TARGET_061:0, DET_SUPER_RES_TARGET_062:0, DET_SUPER_RES_TARGET_063:0, DET_SUPER_RES_TARGET_064:0]}, provided-interface=Pi_SG_Detections_061_064_AL
      Pp_SG_Detections_065_068_AL: nonqueued-sender-com-spec{data-element=Vdp_SG_Detections_065_068_AL, init-value=fields=[DET_AZIMUTH_065:0, DET_AZIMUTH_066:0, DET_AZIMUTH_067:0, DET_AZIMUTH_068:0, DET_AZIMUTH_ERR_065:0, DET_AZIMUTH_ERR_066:0, DET_AZIMUTH_ERR_067:0, DET_AZIMUTH_ERR_068:0, DET_BELOW_RAIN_THOLD_065:0, DET_BELOW_RAIN_THOLD_066:0, DET_BELOW_RAIN_THOLD_067:0, DET_BELOW_RAIN_THOLD_068:0, DET_BI_STATIC_FLAG_065:0, DET_BI_STATIC_FLAG_066:0, DET_BI_STATIC_FLAG_067:0, DET_BI_STATIC_FLAG_068:0, DET_CONFD_AZIMUTH_065:0, DET_CONFD_AZIMUTH_066:0, DET_CONFD_AZIMUTH_067:0, DET_CONFD_AZIMUTH_068:0, DET_CONFD_ELEVATION_065:0, DET_CONFD_ELEVATION_066:0, DET_CONFD_ELEVATION_067:0, DET_CONFD_ELEVATION_068:0, DET_ELEVATION_065:0, DET_ELEVATION_066:0, DET_ELEVATION_067:0, DET_ELEVATION_068:0, DET_ELEVATION_ERR_065:0, DET_ELEVATION_ERR_066:0, DET_ELEVATION_ERR_067:0, DET_ELEVATION_ERR_068:0, DET_EXISTENCE_PROB_065:0, DET_EXISTENCE_PROB_066:0, DET_EXISTENCE_PROB_067:0, DET_EXISTENCE_PROB_068:0, DET_HVC_FLAG_065:0, DET_HVC_FLAG_066:0, DET_HVC_FLAG_067:0, DET_HVC_FLAG_068:0, DET_IDM_065:0, DET_IDM_066:0, DET_IDM_067:0, DET_IDM_068:0, DET_MH_CRC16_065_068:0, DET_MH_CYCLE_COUNTER_065_068:0, DET_MH_SCAN_INDEX_4LSB_065_068:0, DET_MTD_065:0, DET_MTD_066:0, DET_MTD_067:0, DET_MTD_068:0, DET_PROB_1STAZHYPO_065:0, DET_PROB_1STAZHYPO_066:0, DET_PROB_1STAZHYPO_067:0, DET_PROB_1STAZHYPO_068:0, DET_RANGE_065:0, DET_RANGE_066:0, DET_RANGE_067:0, DET_RANGE_068:0, DET_RANGE_ERR_065:0, DET_RANGE_ERR_066:0, DET_RANGE_ERR_067:0, DET_RANGE_ERR_068:0, DET_RANGE_VELOCITY_065:16384, DET_RANGE_VELOCITY_066:16384, DET_RANGE_VELOCITY_067:16384, DET_RANGE_VELOCITY_068:16384, DET_RANGE_VELOCITY_ERR_065:0, DET_RANGE_VELOCITY_ERR_066:0, DET_RANGE_VELOCITY_ERR_067:0, DET_RANGE_VELOCITY_ERR_068:0, DET_RCS_065:128, DET_RCS_066:128, DET_RCS_067:128, DET_RCS_068:128, DET_SNR_065:0, DET_SNR_066:0, DET_SNR_067:0, DET_SNR_068:0, DET_SUPER_RES_TARGET_065:0, DET_SUPER_RES_TARGET_066:0, DET_SUPER_RES_TARGET_067:0, DET_SUPER_RES_TARGET_068:0]}, provided-interface=Pi_SG_Detections_065_068_AL
      Pp_SG_Detections_069_072_AL: nonqueued-sender-com-spec{data-element=Vdp_SG_Detections_069_072_AL, init-value=fields=[DET_AZIMUTH_069:0, DET_AZIMUTH_070:0, DET_AZIMUTH_071:0, DET_AZIMUTH_072:0, DET_AZIMUTH_ERR_069:0, DET_AZIMUTH_ERR_070:0, DET_AZIMUTH_ERR_071:0, DET_AZIMUTH_ERR_072:0, DET_BELOW_RAIN_THOLD_069:0, DET_BELOW_RAIN_THOLD_070:0, DET_BELOW_RAIN_THOLD_071:0, DET_BELOW_RAIN_THOLD_072:0, DET_BI_STATIC_FLAG_069:0, DET_BI_STATIC_FLAG_070:0, DET_BI_STATIC_FLAG_071:0, DET_BI_STATIC_FLAG_072:0, DET_CONFD_AZIMUTH_069:0, DET_CONFD_AZIMUTH_070:0, DET_CONFD_AZIMUTH_071:0, DET_CONFD_AZIMUTH_072:0, DET_CONFD_ELEVATION_069:0, DET_CONFD_ELEVATION_070:0, DET_CONFD_ELEVATION_071:0, DET_CONFD_ELEVATION_072:0, DET_ELEVATION_069:0, DET_ELEVATION_070:0, DET_ELEVATION_071:0, DET_ELEVATION_072:0, DET_ELEVATION_ERR_069:0, DET_ELEVATION_ERR_070:0, DET_ELEVATION_ERR_071:0, DET_ELEVATION_ERR_072:0, DET_EXISTENCE_PROB_069:0, DET_EXISTENCE_PROB_070:0, DET_EXISTENCE_PROB_071:0, DET_EXISTENCE_PROB_072:0, DET_HVC_FLAG_069:0, DET_HVC_FLAG_070:0, DET_HVC_FLAG_071:0, DET_HVC_FLAG_072:0, DET_IDM_069:0, DET_IDM_070:0, DET_IDM_071:0, DET_IDM_072:0, DET_MH_CRC16_069_072:0, DET_MH_CYCLE_COUNTER_069_072:0, DET_MH_SCAN_INDEX_4LSB_069_072:0, DET_MTD_069:0, DET_MTD_070:0, DET_MTD_071:0, DET_MTD_072:0, DET_PROB_1STAZHYPO_069:0, DET_PROB_1STAZHYPO_070:0, DET_PROB_1STAZHYPO_071:0, DET_PROB_1STAZHYPO_072:0, DET_RANGE_069:0, DET_RANGE_070:0, DET_RANGE_071:0, DET_RANGE_072:0, DET_RANGE_ERR_069:0, DET_RANGE_ERR_070:0, DET_RANGE_ERR_071:0, DET_RANGE_ERR_072:0, DET_RANGE_VELOCITY_069:16384, DET_RANGE_VELOCITY_070:16384, DET_RANGE_VELOCITY_071:16384, DET_RANGE_VELOCITY_072:16384, DET_RANGE_VELOCITY_ERR_069:0, DET_RANGE_VELOCITY_ERR_070:0, DET_RANGE_VELOCITY_ERR_071:0, DET_RANGE_VELOCITY_ERR_072:0, DET_RCS_069:128, DET_RCS_070:128, DET_RCS_071:128, DET_RCS_072:128, DET_SNR_069:0, DET_SNR_070:0, DET_SNR_071:0, DET_SNR_072:0, DET_SUPER_RES_TARGET_069:0, DET_SUPER_RES_TARGET_070:0, DET_SUPER_RES_TARGET_071:0, DET_SUPER_RES_TARGET_072:0]}, provided-interface=Pi_SG_Detections_069_072_AL
      Pp_SG_Detections_073_076_AL: nonqueued-sender-com-spec{data-element=Vdp_SG_Detections_073_076_AL, init-value=fields=[DET_AZIMUTH_073:0, DET_AZIMUTH_074:0, DET_AZIMUTH_075:0, DET_AZIMUTH_076:0, DET_AZIMUTH_ERR_073:0, DET_AZIMUTH_ERR_074:0, DET_AZIMUTH_ERR_075:0, DET_AZIMUTH_ERR_076:0, DET_BELOW_RAIN_THOLD_073:0, DET_BELOW_RAIN_THOLD_074:0, DET_BELOW_RAIN_THOLD_075:0, DET_BELOW_RAIN_THOLD_076:0, DET_BI_STATIC_FLAG_073:0, DET_BI_STATIC_FLAG_074:0, DET_BI_STATIC_FLAG_075:0, DET_BI_STATIC_FLAG_076:0, DET_CONFD_AZIMUTH_073:0, DET_CONFD_AZIMUTH_074:0, DET_CONFD_AZIMUTH_075:0, DET_CONFD_AZIMUTH_076:0, DET_CONFD_ELEVATION_073:0, DET_CONFD_ELEVATION_074:0, DET_CONFD_ELEVATION_075:0, DET_CONFD_ELEVATION_076:0, DET_ELEVATION_073:0, DET_ELEVATION_074:0, DET_ELEVATION_075:0, DET_ELEVATION_076:0, DET_ELEVATION_ERR_073:0, DET_ELEVATION_ERR_074:0, DET_ELEVATION_ERR_075:0, DET_ELEVATION_ERR_076:0, DET_EXISTENCE_PROB_073:0, DET_EXISTENCE_PROB_074:0, DET_EXISTENCE_PROB_075:0, DET_EXISTENCE_PROB_076:0, DET_HVC_FLAG_073:0, DET_HVC_FLAG_074:0, DET_HVC_FLAG_075:0, DET_HVC_FLAG_076:0, DET_IDM_073:0, DET_IDM_074:0, DET_IDM_075:0, DET_IDM_076:0, DET_MH_CRC16_073_076:0, DET_MH_CYCLE_COUNTER_073_076:0, DET_MH_SCAN_INDEX_4LSB_073_076:0, DET_MTD_073:0, DET_MTD_074:0, DET_MTD_075:0, DET_MTD_076:0, DET_PROB_1STAZHYPO_073:0, DET_PROB_1STAZHYPO_074:0, DET_PROB_1STAZHYPO_075:0, DET_PROB_1STAZHYPO_076:0, DET_RANGE_073:0, DET_RANGE_074:0, DET_RANGE_075:0, DET_RANGE_076:0, DET_RANGE_ERR_073:0, DET_RANGE_ERR_074:0, DET_RANGE_ERR_075:0, DET_RANGE_ERR_076:0, DET_RANGE_VELOCITY_073:16384, DET_RANGE_VELOCITY_074:16384, DET_RANGE_VELOCITY_075:16384, DET_RANGE_VELOCITY_076:16384, DET_RANGE_VELOCITY_ERR_073:0, DET_RANGE_VELOCITY_ERR_074:0, DET_RANGE_VELOCITY_ERR_075:0, DET_RANGE_VELOCITY_ERR_076:0, DET_RCS_073:128, DET_RCS_074:128, DET_RCS_075:128, DET_RCS_076:128, DET_SNR_073:0, DET_SNR_074:0, DET_SNR_075:0, DET_SNR_076:0, DET_SUPER_RES_TARGET_073:0, DET_SUPER_RES_TARGET_074:0, DET_SUPER_RES_TARGET_075:0, DET_SUPER_RES_TARGET_076:0]}, provided-interface=Pi_SG_Detections_073_076_AL
      Pp_SG_Detections_077_080_AL: nonqueued-sender-com-spec{data-element=Vdp_SG_Detections_077_080_AL, init-value=fields=[DET_AZIMUTH_077:0, DET_AZIMUTH_078:0, DET_AZIMUTH_079:0, DET_AZIMUTH_080:0, DET_AZIMUTH_ERR_077:0, DET_AZIMUTH_ERR_078:0, DET_AZIMUTH_ERR_079:0, DET_AZIMUTH_ERR_080:0, DET_BELOW_RAIN_THOLD_077:0, DET_BELOW_RAIN_THOLD_078:0, DET_BELOW_RAIN_THOLD_079:0, DET_BELOW_RAIN_THOLD_080:0, DET_BI_STATIC_FLAG_077:0, DET_BI_STATIC_FLAG_078:0, DET_BI_STATIC_FLAG_079:0, DET_BI_STATIC_FLAG_080:0, DET_CONFD_AZIMUTH_077:0, DET_CONFD_AZIMUTH_078:0, DET_CONFD_AZIMUTH_079:0, DET_CONFD_AZIMUTH_080:0, DET_CONFD_ELEVATION_077:0, DET_CONFD_ELEVATION_078:0, DET_CONFD_ELEVATION_079:0, DET_CONFD_ELEVATION_080:0, DET_ELEVATION_077:0, DET_ELEVATION_078:0, DET_ELEVATION_079:0, DET_ELEVATION_080:0, DET_ELEVATION_ERR_077:0, DET_ELEVATION_ERR_078:0, DET_ELEVATION_ERR_079:0, DET_ELEVATION_ERR_080:0, DET_EXISTENCE_PROB_077:0, DET_EXISTENCE_PROB_078:0, DET_EXISTENCE_PROB_079:0, DET_EXISTENCE_PROB_080:0, DET_HVC_FLAG_077:0, DET_HVC_FLAG_078:0, DET_HVC_FLAG_079:0, DET_HVC_FLAG_080:0, DET_IDM_077:0, DET_IDM_078:0, DET_IDM_079:0, DET_IDM_080:0, DET_MH_CRC16_077_080:0, DET_MH_CYCLE_COUNTER_077_080:0, DET_MH_SCAN_INDEX_4LSB_077_080:0, DET_MTD_077:0, DET_MTD_078:0, DET_MTD_079:0, DET_MTD_080:0, DET_PROB_1STAZHYPO_077:0, DET_PROB_1STAZHYPO_078:0, DET_PROB_1STAZHYPO_079:0, DET_PROB_1STAZHYPO_080:0, DET_RANGE_077:0, DET_RANGE_078:0, DET_RANGE_079:0, DET_RANGE_080:0, DET_RANGE_ERR_077:0, DET_RANGE_ERR_078:0, DET_RANGE_ERR_079:0, DET_RANGE_ERR_080:0, DET_RANGE_VELOCITY_077:16384, DET_RANGE_VELOCITY_078:16384, DET_RANGE_VELOCITY_079:16384, DET_RANGE_VELOCITY_080:16384, DET_RANGE_VELOCITY_ERR_077:0, DET_RANGE_VELOCITY_ERR_078:0, DET_RANGE_VELOCITY_ERR_079:0, DET_RANGE_VELOCITY_ERR_080:0, DET_RCS_077:128, DET_RCS_078:128, DET_RCS_079:128, DET_RCS_080:128, DET_SNR_077:0, DET_SNR_078:0, DET_SNR_079:0, DET_SNR_080:0, DET_SUPER_RES_TARGET_077:0, DET_SUPER_RES_TARGET_078:0, DET_SUPER_RES_TARGET_079:0, DET_SUPER_RES_TARGET_080:0]}, provided-interface=Pi_SG_Detections_077_080_AL
      Pp_SG_Detections_081_084_AL: nonqueued-sender-com-spec{data-element=Vdp_SG_Detections_081_084_AL, init-value=fields=[DET_AZIMUTH_081:0, DET_AZIMUTH_082:0, DET_AZIMUTH_083:0, DET_AZIMUTH_084:0, DET_AZIMUTH_ERR_081:0, DET_AZIMUTH_ERR_082:0, DET_AZIMUTH_ERR_083:0, DET_AZIMUTH_ERR_084:0, DET_BELOW_RAIN_THOLD_081:0, DET_BELOW_RAIN_THOLD_082:0, DET_BELOW_RAIN_THOLD_083:0, DET_BELOW_RAIN_THOLD_084:0, DET_BI_STATIC_FLAG_081:0, DET_BI_STATIC_FLAG_082:0, DET_BI_STATIC_FLAG_083:0, DET_BI_STATIC_FLAG_084:0, DET_CONFD_AZIMUTH_081:0, DET_CONFD_AZIMUTH_082:0, DET_CONFD_AZIMUTH_083:0, DET_CONFD_AZIMUTH_084:0, DET_CONFD_ELEVATION_081:0, DET_CONFD_ELEVATION_082:0, DET_CONFD_ELEVATION_083:0, DET_CONFD_ELEVATION_084:0, DET_ELEVATION_081:0, DET_ELEVATION_082:0, DET_ELEVATION_083:0, DET_ELEVATION_084:0, DET_ELEVATION_ERR_081:0, DET_ELEVATION_ERR_082:0, DET_ELEVATION_ERR_083:0, DET_ELEVATION_ERR_084:0, DET_EXISTENCE_PROB_081:0, DET_EXISTENCE_PROB_082:0, DET_EXISTENCE_PROB_083:0, DET_EXISTENCE_PROB_084:0, DET_HVC_FLAG_081:0, DET_HVC_FLAG_082:0, DET_HVC_FLAG_083:0, DET_HVC_FLAG_084:0, DET_IDM_081:0, DET_IDM_082:0, DET_IDM_083:0, DET_IDM_084:0, DET_MH_CRC16_081_084:0, DET_MH_CYCLE_COUNTER_081_084:0, DET_MH_SCAN_INDEX_4LSB_081_084:0, DET_MTD_081:0, DET_MTD_082:0, DET_MTD_083:0, DET_MTD_084:0, DET_PROB_1STAZHYPO_081:0, DET_PROB_1STAZHYPO_082:0, DET_PROB_1STAZHYPO_083:0, DET_PROB_1STAZHYPO_084:0, DET_RANGE_081:0, DET_RANGE_082:0, DET_RANGE_083:0, DET_RANGE_084:0, DET_RANGE_ERR_081:0, DET_RANGE_ERR_082:0, DET_RANGE_ERR_083:0, DET_RANGE_ERR_084:0, DET_RANGE_VELOCITY_081:16384, DET_RANGE_VELOCITY_082:16384, DET_RANGE_VELOCITY_083:16384, DET_RANGE_VELOCITY_084:16384, DET_RANGE_VELOCITY_ERR_081:0, DET_RANGE_VELOCITY_ERR_082:0, DET_RANGE_VELOCITY_ERR_083:0, DET_RANGE_VELOCITY_ERR_084:0, DET_RCS_081:128, DET_RCS_082:128, DET_RCS_083:128, DET_RCS_084:128, DET_SNR_081:0, DET_SNR_082:0, DET_SNR_083:0, DET_SNR_084:0, DET_SUPER_RES_TARGET_081:0, DET_SUPER_RES_TARGET_082:0, DET_SUPER_RES_TARGET_083:0, DET_SUPER_RES_TARGET_084:0]}, provided-interface=Pi_SG_Detections_081_084_AL
      Pp_SG_Detections_085_088_AL: nonqueued-sender-com-spec{data-element=Vdp_SG_Detections_085_088_AL, init-value=fields=[DET_AZIMUTH_085:0, DET_AZIMUTH_086:0, DET_AZIMUTH_087:0, DET_AZIMUTH_088:0, DET_AZIMUTH_ERR_085:0, DET_AZIMUTH_ERR_086:0, DET_AZIMUTH_ERR_087:0, DET_AZIMUTH_ERR_088:0, DET_BELOW_RAIN_THOLD_085:0, DET_BELOW_RAIN_THOLD_086:0, DET_BELOW_RAIN_THOLD_087:0, DET_BELOW_RAIN_THOLD_088:0, DET_BI_STATIC_FLAG_085:0, DET_BI_STATIC_FLAG_086:0, DET_BI_STATIC_FLAG_087:0, DET_BI_STATIC_FLAG_088:0, DET_CONFD_AZIMUTH_085:0, DET_CONFD_AZIMUTH_086:0, DET_CONFD_AZIMUTH_087:0, DET_CONFD_AZIMUTH_088:0, DET_CONFD_ELEVATION_085:0, DET_CONFD_ELEVATION_086:0, DET_CONFD_ELEVATION_087:0, DET_CONFD_ELEVATION_088:0, DET_ELEVATION_085:0, DET_ELEVATION_086:0, DET_ELEVATION_087:0, DET_ELEVATION_088:0, DET_ELEVATION_ERR_085:0, DET_ELEVATION_ERR_086:0, DET_ELEVATION_ERR_087:0, DET_ELEVATION_ERR_088:0, DET_EXISTENCE_PROB_085:0, DET_EXISTENCE_PROB_086:0, DET_EXISTENCE_PROB_087:0, DET_EXISTENCE_PROB_088:0, DET_HVC_FLAG_085:0, DET_HVC_FLAG_086:0, DET_HVC_FLAG_087:0, DET_HVC_FLAG_088:0, DET_IDM_085:0, DET_IDM_086:0, DET_IDM_087:0, DET_IDM_088:0, DET_MH_CRC16_085_088:0, DET_MH_CYCLE_COUNTER_085_088:0, DET_MH_SCAN_INDEX_4LSB_085_088:0, DET_MTD_085:0, DET_MTD_086:0, DET_MTD_087:0, DET_MTD_088:0, DET_PROB_1STAZHYPO_085:0, DET_PROB_1STAZHYPO_086:0, DET_PROB_1STAZHYPO_087:0, DET_PROB_1STAZHYPO_088:0, DET_RANGE_085:0, DET_RANGE_086:0, DET_RANGE_087:0, DET_RANGE_088:0, DET_RANGE_ERR_085:0, DET_RANGE_ERR_086:0, DET_RANGE_ERR_087:0, DET_RANGE_ERR_088:0, DET_RANGE_VELOCITY_085:16384, DET_RANGE_VELOCITY_086:16384, DET_RANGE_VELOCITY_087:16384, DET_RANGE_VELOCITY_088:16384, DET_RANGE_VELOCITY_ERR_085:0, DET_RANGE_VELOCITY_ERR_086:0, DET_RANGE_VELOCITY_ERR_087:0, DET_RANGE_VELOCITY_ERR_088:0, DET_RCS_085:128, DET_RCS_086:128, DET_RCS_087:128, DET_RCS_088:128, DET_SNR_085:0, DET_SNR_086:0, DET_SNR_087:0, DET_SNR_088:0, DET_SUPER_RES_TARGET_085:0, DET_SUPER_RES_TARGET_086:0, DET_SUPER_RES_TARGET_087:0, DET_SUPER_RES_TARGET_088:0]}, provided-interface=Pi_SG_Detections_085_088_AL
      Pp_SG_Detections_089_092_AL: nonqueued-sender-com-spec{data-element=Vdp_SG_Detections_089_092_AL, init-value=fields=[DET_AZIMUTH_089:0, DET_AZIMUTH_090:0, DET_AZIMUTH_091:0, DET_AZIMUTH_092:0, DET_AZIMUTH_ERR_089:0, DET_AZIMUTH_ERR_090:0, DET_AZIMUTH_ERR_091:0, DET_AZIMUTH_ERR_092:0, DET_BELOW_RAIN_THOLD_089:0, DET_BELOW_RAIN_THOLD_090:0, DET_BELOW_RAIN_THOLD_091:0, DET_BELOW_RAIN_THOLD_092:0, DET_BI_STATIC_FLAG_089:0, DET_BI_STATIC_FLAG_090:0, DET_BI_STATIC_FLAG_091:0, DET_BI_STATIC_FLAG_092:0, DET_CONFD_AZIMUTH_089:0, DET_CONFD_AZIMUTH_090:0, DET_CONFD_AZIMUTH_091:0, DET_CONFD_AZIMUTH_092:0, DET_CONFD_ELEVATION_089:0, DET_CONFD_ELEVATION_090:0, DET_CONFD_ELEVATION_091:0, DET_CONFD_ELEVATION_092:0, DET_ELEVATION_089:0, DET_ELEVATION_090:0, DET_ELEVATION_091:0, DET_ELEVATION_092:0, DET_ELEVATION_ERR_089:0, DET_ELEVATION_ERR_090:0, DET_ELEVATION_ERR_091:0, DET_ELEVATION_ERR_092:0, DET_EXISTENCE_PROB_089:0, DET_EXISTENCE_PROB_090:0, DET_EXISTENCE_PROB_091:0, DET_EXISTENCE_PROB_092:0, DET_HVC_FLAG_089:0, DET_HVC_FLAG_090:0, DET_HVC_FLAG_091:0, DET_HVC_FLAG_092:0, DET_IDM_089:0, DET_IDM_090:0, DET_IDM_091:0, DET_IDM_092:0, DET_MH_CRC16_089_092:0, DET_MH_CYCLE_COUNTER_089_092:0, DET_MH_SCAN_INDEX_4LSB_089_092:0, DET_MTD_089:0, DET_MTD_090:0, DET_MTD_091:0, DET_MTD_092:0, DET_PROB_1STAZHYPO_089:0, DET_PROB_1STAZHYPO_090:0, DET_PROB_1STAZHYPO_091:0, DET_PROB_1STAZHYPO_092:0, DET_RANGE_089:0, DET_RANGE_090:0, DET_RANGE_091:0, DET_RANGE_092:0, DET_RANGE_ERR_089:0, DET_RANGE_ERR_090:0, DET_RANGE_ERR_091:0, DET_RANGE_ERR_092:0, DET_RANGE_VELOCITY_089:16384, DET_RANGE_VELOCITY_090:16384, DET_RANGE_VELOCITY_091:16384, DET_RANGE_VELOCITY_092:16384, DET_RANGE_VELOCITY_ERR_089:0, DET_RANGE_VELOCITY_ERR_090:0, DET_RANGE_VELOCITY_ERR_091:0, DET_RANGE_VELOCITY_ERR_092:0, DET_RCS_089:128, DET_RCS_090:128, DET_RCS_091:128, DET_RCS_092:128, DET_SNR_089:0, DET_SNR_090:0, DET_SNR_091:0, DET_SNR_092:0, DET_SUPER_RES_TARGET_089:0, DET_SUPER_RES_TARGET_090:0, DET_SUPER_RES_TARGET_091:0, DET_SUPER_RES_TARGET_092:0]}, provided-interface=Pi_SG_Detections_089_092_AL
      Pp_SG_Detections_093_096_AL: nonqueued-sender-com-spec{data-element=Vdp_SG_Detections_093_096_AL, init-value=fields=[DET_AZIMUTH_093:0, DET_AZIMUTH_094:0, DET_AZIMUTH_095:0, DET_AZIMUTH_096:0, DET_AZIMUTH_ERR_093:0, DET_AZIMUTH_ERR_094:0, DET_AZIMUTH_ERR_095:0, DET_AZIMUTH_ERR_096:0, DET_BELOW_RAIN_THOLD_093:0, DET_BELOW_RAIN_THOLD_094:0, DET_BELOW_RAIN_THOLD_095:0, DET_BELOW_RAIN_THOLD_096:0, DET_BI_STATIC_FLAG_093:0, DET_BI_STATIC_FLAG_094:0, DET_BI_STATIC_FLAG_095:0, DET_BI_STATIC_FLAG_096:0, DET_CONFD_AZIMUTH_093:0, DET_CONFD_AZIMUTH_094:0, DET_CONFD_AZIMUTH_095:0, DET_CONFD_AZIMUTH_096:0, DET_CONFD_ELEVATION_093:0, DET_CONFD_ELEVATION_094:0, DET_CONFD_ELEVATION_095:0, DET_CONFD_ELEVATION_096:0, DET_ELEVATION_093:0, DET_ELEVATION_094:0, DET_ELEVATION_095:0, DET_ELEVATION_096:0, DET_ELEVATION_ERR_093:0, DET_ELEVATION_ERR_094:0, DET_ELEVATION_ERR_095:0, DET_ELEVATION_ERR_096:0, DET_EXISTENCE_PROB_093:0, DET_EXISTENCE_PROB_094:0, DET_EXISTENCE_PROB_095:0, DET_EXISTENCE_PROB_096:0, DET_HVC_FLAG_093:0, DET_HVC_FLAG_094:0, DET_HVC_FLAG_095:0, DET_HVC_FLAG_096:0, DET_IDM_093:0, DET_IDM_094:0, DET_IDM_095:0, DET_IDM_096:0, DET_MH_CRC16_093_096:0, DET_MH_CYCLE_COUNTER_093_096:0, DET_MH_SCAN_INDEX_4LSB_093_096:0, DET_MTD_093:0, DET_MTD_094:0, DET_MTD_095:0, DET_MTD_096:0, DET_PROB_1STAZHYPO_093:0, DET_PROB_1STAZHYPO_094:0, DET_PROB_1STAZHYPO_095:0, DET_PROB_1STAZHYPO_096:0, DET_RANGE_093:0, DET_RANGE_094:0, DET_RANGE_095:0, DET_RANGE_096:0, DET_RANGE_ERR_093:0, DET_RANGE_ERR_094:0, DET_RANGE_ERR_095:0, DET_RANGE_ERR_096:0, DET_RANGE_VELOCITY_093:16384, DET_RANGE_VELOCITY_094:16384, DET_RANGE_VELOCITY_095:16384, DET_RANGE_VELOCITY_096:16384, DET_RANGE_VELOCITY_ERR_093:0, DET_RANGE_VELOCITY_ERR_094:0, DET_RANGE_VELOCITY_ERR_095:0, DET_RANGE_VELOCITY_ERR_096:0, DET_RCS_093:128, DET_RCS_094:128, DET_RCS_095:128, DET_RCS_096:128, DET_SNR_093:0, DET_SNR_094:0, DET_SNR_095:0, DET_SNR_096:0, DET_SUPER_RES_TARGET_093:0, DET_SUPER_RES_TARGET_094:0, DET_SUPER_RES_TARGET_095:0, DET_SUPER_RES_TARGET_096:0]}, provided-interface=Pi_SG_Detections_093_096_AL
      Pp_SG_Detections_101_104_AL: nonqueued-sender-com-spec{data-element=Vdp_SG_Detections_101_104_AL, init-value=fields=[DET_AZIMUTH_101:0, DET_AZIMUTH_102:0, DET_AZIMUTH_103:0, DET_AZIMUTH_104:0, DET_AZIMUTH_ERR_101:0, DET_AZIMUTH_ERR_102:0, DET_AZIMUTH_ERR_103:0, DET_AZIMUTH_ERR_104:0, DET_BELOW_RAIN_THOLD_101:0, DET_BELOW_RAIN_THOLD_102:0, DET_BELOW_RAIN_THOLD_103:0, DET_BELOW_RAIN_THOLD_104:0, DET_BI_STATIC_FLAG_101:0, DET_BI_STATIC_FLAG_102:0, DET_BI_STATIC_FLAG_103:0, DET_BI_STATIC_FLAG_104:0, DET_CONFD_AZIMUTH_101:0, DET_CONFD_AZIMUTH_102:0, DET_CONFD_AZIMUTH_103:0, DET_CONFD_AZIMUTH_104:0, DET_CONFD_ELEVATION_101:0, DET_CONFD_ELEVATION_102:0, DET_CONFD_ELEVATION_103:0, DET_CONFD_ELEVATION_104:0, DET_ELEVATION_101:0, DET_ELEVATION_102:0, DET_ELEVATION_103:0, DET_ELEVATION_104:0, DET_ELEVATION_ERR_101:0, DET_ELEVATION_ERR_102:0, DET_ELEVATION_ERR_103:0, DET_ELEVATION_ERR_104:0, DET_EXISTENCE_PROB_101:0, DET_EXISTENCE_PROB_102:0, DET_EXISTENCE_PROB_103:0, DET_EXISTENCE_PROB_104:0, DET_HVC_FLAG_101:0, DET_HVC_FLAG_102:0, DET_HVC_FLAG_103:0, DET_HVC_FLAG_104:0, DET_IDM_101:0, DET_IDM_102:0, DET_IDM_103:0, DET_IDM_104:0, DET_MH_CRC16_101_104:0, DET_MH_CYCLE_COUNTER_101_104:0, DET_MH_SCAN_INDEX_4LSB_101_104:0, DET_MTD_101:0, DET_MTD_102:0, DET_MTD_103:0, DET_MTD_104:0, DET_PROB_1STAZHYPO_101:0, DET_PROB_1STAZHYPO_102:0, DET_PROB_1STAZHYPO_103:0, DET_PROB_1STAZHYPO_104:0, DET_RANGE_101:0, DET_RANGE_102:0, DET_RANGE_103:0, DET_RANGE_104:0, DET_RANGE_ERR_101:0, DET_RANGE_ERR_102:0, DET_RANGE_ERR_103:0, DET_RANGE_ERR_104:0, DET_RANGE_VELOCITY_101:16384, DET_RANGE_VELOCITY_102:16384, DET_RANGE_VELOCITY_103:16384, DET_RANGE_VELOCITY_104:16384, DET_RANGE_VELOCITY_ERR_101:0, DET_RANGE_VELOCITY_ERR_102:0, DET_RANGE_VELOCITY_ERR_103:0, DET_RANGE_VELOCITY_ERR_104:0, DET_RCS_101:128, DET_RCS_102:128, DET_RCS_103:128, DET_RCS_104:128, DET_SNR_101:0, DET_SNR_102:0, DET_SNR_103:0, DET_SNR_104:0, DET_SUPER_RES_TARGET_101:0, DET_SUPER_RES_TARGET_102:0, DET_SUPER_RES_TARGET_103:0, DET_SUPER_RES_TARGET_104:0]}, provided-interface=Pi_SG_Detections_101_104_AL
      Pp_SG_Detections_105_108_AL: nonqueued-sender-com-spec{data-element=Vdp_SG_Detections_105_108_AL, init-value=fields=[DET_AZIMUTH_105:0, DET_AZIMUTH_106:0, DET_AZIMUTH_107:0, DET_AZIMUTH_108:0, DET_AZIMUTH_ERR_105:0, DET_AZIMUTH_ERR_106:0, DET_AZIMUTH_ERR_107:0, DET_AZIMUTH_ERR_108:0, DET_BELOW_RAIN_THOLD_105:0, DET_BELOW_RAIN_THOLD_106:0, DET_BELOW_RAIN_THOLD_107:0, DET_BELOW_RAIN_THOLD_108:0, DET_BI_STATIC_FLAG_105:0, DET_BI_STATIC_FLAG_106:0, DET_BI_STATIC_FLAG_107:0, DET_BI_STATIC_FLAG_108:0, DET_CONFD_AZIMUTH_105:0, DET_CONFD_AZIMUTH_106:0, DET_CONFD_AZIMUTH_107:0, DET_CONFD_AZIMUTH_108:0, DET_CONFD_ELEVATION_105:0, DET_CONFD_ELEVATION_106:0, DET_CONFD_ELEVATION_107:0, DET_CONFD_ELEVATION_108:0, DET_ELEVATION_105:0, DET_ELEVATION_106:0, DET_ELEVATION_107:0, DET_ELEVATION_108:0, DET_ELEVATION_ERR_105:0, DET_ELEVATION_ERR_106:0, DET_ELEVATION_ERR_107:0, DET_ELEVATION_ERR_108:0, DET_EXISTENCE_PROB_105:0, DET_EXISTENCE_PROB_106:0, DET_EXISTENCE_PROB_107:0, DET_EXISTENCE_PROB_108:0, DET_HVC_FLAG_105:0, DET_HVC_FLAG_106:0, DET_HVC_FLAG_107:0, DET_HVC_FLAG_108:0, DET_IDM_105:0, DET_IDM_106:0, DET_IDM_107:0, DET_IDM_108:0, DET_MH_CRC16_105_108:0, DET_MH_CYCLE_COUNTER_105_108:0, DET_MH_SCAN_INDEX_4LSB_105_108:0, DET_MTD_105:0, DET_MTD_106:0, DET_MTD_107:0, DET_MTD_108:0, DET_PROB_1STAZHYPO_105:0, DET_PROB_1STAZHYPO_106:0, DET_PROB_1STAZHYPO_107:0, DET_PROB_1STAZHYPO_108:0, DET_RANGE_105:0, DET_RANGE_106:0, DET_RANGE_107:0, DET_RANGE_108:0, DET_RANGE_ERR_105:0, DET_RANGE_ERR_106:0, DET_RANGE_ERR_107:0, DET_RANGE_ERR_108:0, DET_RANGE_VELOCITY_105:16384, DET_RANGE_VELOCITY_106:16384, DET_RANGE_VELOCITY_107:16384, DET_RANGE_VELOCITY_108:16384, DET_RANGE_VELOCITY_ERR_105:0, DET_RANGE_VELOCITY_ERR_106:0, DET_RANGE_VELOCITY_ERR_107:0, DET_RANGE_VELOCITY_ERR_108:0, DET_RCS_105:128, DET_RCS_106:128, DET_RCS_107:128, DET_RCS_108:128, DET_SNR_105:0, DET_SNR_106:0, DET_SNR_107:0, DET_SNR_108:0, DET_SUPER_RES_TARGET_105:0, DET_SUPER_RES_TARGET_106:0, DET_SUPER_RES_TARGET_107:0, DET_SUPER_RES_TARGET_108:0]}, provided-interface=Pi_SG_Detections_105_108_AL
      Pp_SG_Detections_109_112_AL: nonqueued-sender-com-spec{data-element=Vdp_SG_Detections_109_112_AL, init-value=fields=[DET_AZIMUTH_109:0, DET_AZIMUTH_110:0, DET_AZIMUTH_111:0, DET_AZIMUTH_112:0, DET_AZIMUTH_ERR_109:0, DET_AZIMUTH_ERR_110:0, DET_AZIMUTH_ERR_111:0, DET_AZIMUTH_ERR_112:0, DET_BELOW_RAIN_THOLD_109:0, DET_BELOW_RAIN_THOLD_110:0, DET_BELOW_RAIN_THOLD_111:0, DET_BELOW_RAIN_THOLD_112:0, DET_BI_STATIC_FLAG_109:0, DET_BI_STATIC_FLAG_110:0, DET_BI_STATIC_FLAG_111:0, DET_BI_STATIC_FLAG_112:0, DET_CONFD_AZIMUTH_109:0, DET_CONFD_AZIMUTH_110:0, DET_CONFD_AZIMUTH_111:0, DET_CONFD_AZIMUTH_112:0, DET_CONFD_ELEVATION_109:0, DET_CONFD_ELEVATION_110:0, DET_CONFD_ELEVATION_111:0, DET_CONFD_ELEVATION_112:0, DET_ELEVATION_109:0, DET_ELEVATION_110:0, DET_ELEVATION_111:0, DET_ELEVATION_112:0, DET_ELEVATION_ERR_109:0, DET_ELEVATION_ERR_110:0, DET_ELEVATION_ERR_111:0, DET_ELEVATION_ERR_112:0, DET_EXISTENCE_PROB_109:0, DET_EXISTENCE_PROB_110:0, DET_EXISTENCE_PROB_111:0, DET_EXISTENCE_PROB_112:0, DET_HVC_FLAG_109:0, DET_HVC_FLAG_110:0, DET_HVC_FLAG_111:0, DET_HVC_FLAG_112:0, DET_IDM_109:0, DET_IDM_110:0, DET_IDM_111:0, DET_IDM_112:0, DET_MH_CRC16_109_112:0, DET_MH_CYCLE_COUNTER_109_112:0, DET_MH_SCAN_INDEX_4LSB_109_112:0, DET_MTD_109:0, DET_MTD_110:0, DET_MTD_111:0, DET_MTD_112:0, DET_PROB_1STAZHYPO_109:0, DET_PROB_1STAZHYPO_110:0, DET_PROB_1STAZHYPO_111:0, DET_PROB_1STAZHYPO_112:0, DET_RANGE_109:0, DET_RANGE_110:0, DET_RANGE_111:0, DET_RANGE_112:0, DET_RANGE_ERR_109:0, DET_RANGE_ERR_110:0, DET_RANGE_ERR_111:0, DET_RANGE_ERR_112:0, DET_RANGE_VELOCITY_109:16384, DET_RANGE_VELOCITY_110:16384, DET_RANGE_VELOCITY_111:16384, DET_RANGE_VELOCITY_112:16384, DET_RANGE_VELOCITY_ERR_109:0, DET_RANGE_VELOCITY_ERR_110:0, DET_RANGE_VELOCITY_ERR_111:0, DET_RANGE_VELOCITY_ERR_112:0, DET_RCS_109:128, DET_RCS_110:128, DET_RCS_111:128, DET_RCS_112:128, DET_SNR_109:0, DET_SNR_110:0, DET_SNR_111:0, DET_SNR_112:0, DET_SUPER_RES_TARGET_109:0, DET_SUPER_RES_TARGET_110:0, DET_SUPER_RES_TARGET_111:0, DET_SUPER_RES_TARGET_112:0]}, provided-interface=Pi_SG_Detections_109_112_AL
      Pp_SG_Detections_113_116_AL: nonqueued-sender-com-spec{data-element=Vdp_SG_Detections_113_116_AL, init-value=fields=[DET_AZIMUTH_113:0, DET_AZIMUTH_114:0, DET_AZIMUTH_115:0, DET_AZIMUTH_116:0, DET_AZIMUTH_ERR_113:0, DET_AZIMUTH_ERR_114:0, DET_AZIMUTH_ERR_115:0, DET_AZIMUTH_ERR_116:0, DET_BELOW_RAIN_THOLD_113:0, DET_BELOW_RAIN_THOLD_114:0, DET_BELOW_RAIN_THOLD_115:0, DET_BELOW_RAIN_THOLD_116:0, DET_BI_STATIC_FLAG_113:0, DET_BI_STATIC_FLAG_114:0, DET_BI_STATIC_FLAG_115:0, DET_BI_STATIC_FLAG_116:0, DET_CONFD_AZIMUTH_113:0, DET_CONFD_AZIMUTH_114:0, DET_CONFD_AZIMUTH_115:0, DET_CONFD_AZIMUTH_116:0, DET_CONFD_ELEVATION_113:0, DET_CONFD_ELEVATION_114:0, DET_CONFD_ELEVATION_115:0, DET_CONFD_ELEVATION_116:0, DET_ELEVATION_113:0, DET_ELEVATION_114:0, DET_ELEVATION_115:0, DET_ELEVATION_116:0, DET_ELEVATION_ERR_113:0, DET_ELEVATION_ERR_114:0, DET_ELEVATION_ERR_115:0, DET_ELEVATION_ERR_116:0, DET_EXISTENCE_PROB_113:0, DET_EXISTENCE_PROB_114:0, DET_EXISTENCE_PROB_115:0, DET_EXISTENCE_PROB_116:0, DET_HVC_FLAG_113:0, DET_HVC_FLAG_114:0, DET_HVC_FLAG_115:0, DET_HVC_FLAG_116:0, DET_IDM_113:0, DET_IDM_114:0, DET_IDM_115:0, DET_IDM_116:0, DET_MH_CRC16_113_116:0, DET_MH_CYCLE_COUNTER_113_116:0, DET_MH_SCAN_INDEX_4LSB_113_116:0, DET_MTD_113:0, DET_MTD_114:0, DET_MTD_115:0, DET_MTD_116:0, DET_PROB_1STAZHYPO_113:0, DET_PROB_1STAZHYPO_114:0, DET_PROB_1STAZHYPO_115:0, DET_PROB_1STAZHYPO_116:0, DET_RANGE_113:0, DET_RANGE_114:0, DET_RANGE_115:0, DET_RANGE_116:0, DET_RANGE_ERR_113:0, DET_RANGE_ERR_114:0, DET_RANGE_ERR_115:0, DET_RANGE_ERR_116:0, DET_RANGE_VELOCITY_113:16384, DET_RANGE_VELOCITY_114:16384, DET_RANGE_VELOCITY_115:16384, DET_RANGE_VELOCITY_116:16384, DET_RANGE_VELOCITY_ERR_113:0, DET_RANGE_VELOCITY_ERR_114:0, DET_RANGE_VELOCITY_ERR_115:0, DET_RANGE_VELOCITY_ERR_116:0, DET_RCS_113:128, DET_RCS_114:128, DET_RCS_115:128, DET_RCS_116:128, DET_SNR_113:0, DET_SNR_114:0, DET_SNR_115:0, DET_SNR_116:0, DET_SUPER_RES_TARGET_113:0, DET_SUPER_RES_TARGET_114:0, DET_SUPER_RES_TARGET_115:0, DET_SUPER_RES_TARGET_116:0]}, provided-interface=Pi_SG_Detections_113_116_AL
      Pp_SG_Detections_117_120_AL: nonqueued-sender-com-spec{data-element=Vdp_SG_Detections_117_120_AL, init-value=fields=[DET_AZIMUTH_117:0, DET_AZIMUTH_118:0, DET_AZIMUTH_119:0, DET_AZIMUTH_120:0, DET_AZIMUTH_ERR_117:0, DET_AZIMUTH_ERR_118:0, DET_AZIMUTH_ERR_119:0, DET_AZIMUTH_ERR_120:0, DET_BELOW_RAIN_THOLD_117:0, DET_BELOW_RAIN_THOLD_118:0, DET_BELOW_RAIN_THOLD_119:0, DET_BELOW_RAIN_THOLD_120:0, DET_BI_STATIC_FLAG_117:0, DET_BI_STATIC_FLAG_118:0, DET_BI_STATIC_FLAG_119:0, DET_BI_STATIC_FLAG_120:0, DET_CONFD_AZIMUTH_117:0, DET_CONFD_AZIMUTH_118:0, DET_CONFD_AZIMUTH_119:0, DET_CONFD_AZIMUTH_120:0, DET_CONFD_ELEVATION_117:0, DET_CONFD_ELEVATION_118:0, DET_CONFD_ELEVATION_119:0, DET_CONFD_ELEVATION_120:0, DET_ELEVATION_117:0, DET_ELEVATION_118:0, DET_ELEVATION_119:0, DET_ELEVATION_120:0, DET_ELEVATION_ERR_117:0, DET_ELEVATION_ERR_118:0, DET_ELEVATION_ERR_119:0, DET_ELEVATION_ERR_120:0, DET_EXISTENCE_PROB_117:0, DET_EXISTENCE_PROB_118:0, DET_EXISTENCE_PROB_119:0, DET_EXISTENCE_PROB_120:0, DET_HVC_FLAG_117:0, DET_HVC_FLAG_118:0, DET_HVC_FLAG_119:0, DET_HVC_FLAG_120:0, DET_IDM_117:0, DET_IDM_118:0, DET_IDM_119:0, DET_IDM_120:0, DET_MH_CRC16_117_120:0, DET_MH_CYCLE_COUNTER_117_120:0, DET_MH_SCAN_INDEX_4LSB_117_120:0, DET_MTD_117:0, DET_MTD_118:0, DET_MTD_119:0, DET_MTD_120:0, DET_PROB_1STAZHYPO_117:0, DET_PROB_1STAZHYPO_118:0, DET_PROB_1STAZHYPO_119:0, DET_PROB_1STAZHYPO_120:0, DET_RANGE_117:0, DET_RANGE_118:0, DET_RANGE_119:0, DET_RANGE_120:0, DET_RANGE_ERR_117:0, DET_RANGE_ERR_118:0, DET_RANGE_ERR_119:0, DET_RANGE_ERR_120:0, DET_RANGE_VELOCITY_117:16384, DET_RANGE_VELOCITY_118:16384, DET_RANGE_VELOCITY_119:16384, DET_RANGE_VELOCITY_120:16384, DET_RANGE_VELOCITY_ERR_117:0, DET_RANGE_VELOCITY_ERR_118:0, DET_RANGE_VELOCITY_ERR_119:0, DET_RANGE_VELOCITY_ERR_120:0, DET_RCS_117:128, DET_RCS_118:128, DET_RCS_119:128, DET_RCS_120:128, DET_SNR_117:0, DET_SNR_118:0, DET_SNR_119:0, DET_SNR_120:0, DET_SUPER_RES_TARGET_117:0, DET_SUPER_RES_TARGET_118:0, DET_SUPER_RES_TARGET_119:0, DET_SUPER_RES_TARGET_120:0]}, provided-interface=Pi_SG_Detections_117_120_AL
      Pp_SG_Detections_121_124_AL: nonqueued-sender-com-spec{data-element=Vdp_SG_Detections_121_124_AL, init-value=fields=[DET_AZIMUTH_121:0, DET_AZIMUTH_122:0, DET_AZIMUTH_123:0, DET_AZIMUTH_124:0, DET_AZIMUTH_ERR_121:0, DET_AZIMUTH_ERR_122:0, DET_AZIMUTH_ERR_123:0, DET_AZIMUTH_ERR_124:0, DET_BELOW_RAIN_THOLD_121:0, DET_BELOW_RAIN_THOLD_122:0, DET_BELOW_RAIN_THOLD_123:0, DET_BELOW_RAIN_THOLD_124:0, DET_BI_STATIC_FLAG_121:0, DET_BI_STATIC_FLAG_122:0, DET_BI_STATIC_FLAG_123:0, DET_BI_STATIC_FLAG_124:0, DET_CONFD_AZIMUTH_121:0, DET_CONFD_AZIMUTH_122:0, DET_CONFD_AZIMUTH_123:0, DET_CONFD_AZIMUTH_124:0, DET_CONFD_ELEVATION_121:0, DET_CONFD_ELEVATION_122:0, DET_CONFD_ELEVATION_123:0, DET_CONFD_ELEVATION_124:0, DET_ELEVATION_121:0, DET_ELEVATION_122:0, DET_ELEVATION_123:0, DET_ELEVATION_124:0, DET_ELEVATION_ERR_121:0, DET_ELEVATION_ERR_122:0, DET_ELEVATION_ERR_123:0, DET_ELEVATION_ERR_124:0, DET_EXISTENCE_PROB_121:0, DET_EXISTENCE_PROB_122:0, DET_EXISTENCE_PROB_123:0, DET_EXISTENCE_PROB_124:0, DET_HVC_FLAG_121:0, DET_HVC_FLAG_122:0, DET_HVC_FLAG_123:0, DET_HVC_FLAG_124:0, DET_IDM_121:0, DET_IDM_122:0, DET_IDM_123:0, DET_IDM_124:0, DET_MH_CRC16_121_124:0, DET_MH_CYCLE_COUNTER_121_124:0, DET_MH_SCAN_INDEX_4LSB_121_124:0, DET_MTD_121:0, DET_MTD_122:0, DET_MTD_123:0, DET_MTD_124:0, DET_PROB_1STAZHYPO_121:0, DET_PROB_1STAZHYPO_122:0, DET_PROB_1STAZHYPO_123:0, DET_PROB_1STAZHYPO_124:0, DET_RANGE_121:0, DET_RANGE_122:0, DET_RANGE_123:0, DET_RANGE_124:0, DET_RANGE_ERR_121:0, DET_RANGE_ERR_122:0, DET_RANGE_ERR_123:0, DET_RANGE_ERR_124:0, DET_RANGE_VELOCITY_121:16384, DET_RANGE_VELOCITY_122:16384, DET_RANGE_VELOCITY_123:16384, DET_RANGE_VELOCITY_124:16384, DET_RANGE_VELOCITY_ERR_121:0, DET_RANGE_VELOCITY_ERR_122:0, DET_RANGE_VELOCITY_ERR_123:0, DET_RANGE_VELOCITY_ERR_124:0, DET_RCS_121:128, DET_RCS_122:128, DET_RCS_123:128, DET_RCS_124:128, DET_SNR_121:0, DET_SNR_122:0, DET_SNR_123:0, DET_SNR_124:0, DET_SUPER_RES_TARGET_121:0, DET_SUPER_RES_TARGET_122:0, DET_SUPER_RES_TARGET_123:0, DET_SUPER_RES_TARGET_124:0]}, provided-interface=Pi_SG_Detections_121_124_AL
      Pp_SG_Detections_125_128_AL: nonqueued-sender-com-spec{data-element=Vdp_SG_Detections_125_128_AL, init-value=fields=[DET_AZIMUTH_125:0, DET_AZIMUTH_126:0, DET_AZIMUTH_127:0, DET_AZIMUTH_128:0, DET_AZIMUTH_ERR_125:0, DET_AZIMUTH_ERR_126:0, DET_AZIMUTH_ERR_127:0, DET_AZIMUTH_ERR_128:0, DET_BELOW_RAIN_THOLD_125:0, DET_BELOW_RAIN_THOLD_126:0, DET_BELOW_RAIN_THOLD_127:0, DET_BELOW_RAIN_THOLD_128:0, DET_BI_STATIC_FLAG_125:0, DET_BI_STATIC_FLAG_126:0, DET_BI_STATIC_FLAG_127:0, DET_BI_STATIC_FLAG_128:0, DET_CONFD_AZIMUTH_125:0, DET_CONFD_AZIMUTH_126:0, DET_CONFD_AZIMUTH_127:0, DET_CONFD_AZIMUTH_128:0, DET_CONFD_ELEVATION_125:0, DET_CONFD_ELEVATION_126:0, DET_CONFD_ELEVATION_127:0, DET_CONFD_ELEVATION_128:0, DET_ELEVATION_125:0, DET_ELEVATION_126:0, DET_ELEVATION_127:0, DET_ELEVATION_128:0, DET_ELEVATION_ERR_125:0, DET_ELEVATION_ERR_126:0, DET_ELEVATION_ERR_127:0, DET_ELEVATION_ERR_128:0, DET_EXISTENCE_PROB_125:0, DET_EXISTENCE_PROB_126:0, DET_EXISTENCE_PROB_127:0, DET_EXISTENCE_PROB_128:0, DET_HVC_FLAG_125:0, DET_HVC_FLAG_126:0, DET_HVC_FLAG_127:0, DET_HVC_FLAG_128:0, DET_IDM_125:0, DET_IDM_126:0, DET_IDM_127:0, DET_IDM_128:0, DET_MH_CRC16_125_128:0, DET_MH_CYCLE_COUNTER_125_128:0, DET_MH_SCAN_INDEX_4LSB_125_128:0, DET_MTD_125:0, DET_MTD_126:0, DET_MTD_127:0, DET_MTD_128:0, DET_PROB_1STAZHYPO_125:0, DET_PROB_1STAZHYPO_126:0, DET_PROB_1STAZHYPO_127:0, DET_PROB_1STAZHYPO_128:0, DET_RANGE_125:0, DET_RANGE_126:0, DET_RANGE_127:0, DET_RANGE_128:0, DET_RANGE_ERR_125:0, DET_RANGE_ERR_126:0, DET_RANGE_ERR_127:0, DET_RANGE_ERR_128:0, DET_RANGE_VELOCITY_125:16384, DET_RANGE_VELOCITY_126:16384, DET_RANGE_VELOCITY_127:16384, DET_RANGE_VELOCITY_128:16384, DET_RANGE_VELOCITY_ERR_125:0, DET_RANGE_VELOCITY_ERR_126:0, DET_RANGE_VELOCITY_ERR_127:0, DET_RANGE_VELOCITY_ERR_128:0, DET_RCS_125:128, DET_RCS_126:128, DET_RCS_127:128, DET_RCS_128:128, DET_SNR_125:0, DET_SNR_126:0, DET_SNR_127:0, DET_SNR_128:0, DET_SUPER_RES_TARGET_125:0, DET_SUPER_RES_TARGET_126:0, DET_SUPER_RES_TARGET_127:0, DET_SUPER_RES_TARGET_128:0]}, provided-interface=Pi_SG_Detections_125_128_AL
      Pp_SG_Detections_129_132_AL: nonqueued-sender-com-spec{data-element=Vdp_SG_Detections_129_132_AL, init-value=fields=[DET_AZIMUTH_129:0, DET_AZIMUTH_130:0, DET_AZIMUTH_131:0, DET_AZIMUTH_132:0, DET_AZIMUTH_ERR_129:0, DET_AZIMUTH_ERR_130:0, DET_AZIMUTH_ERR_131:0, DET_AZIMUTH_ERR_132:0, DET_BELOW_RAIN_THOLD_129:0, DET_BELOW_RAIN_THOLD_130:0, DET_BELOW_RAIN_THOLD_131:0, DET_BELOW_RAIN_THOLD_132:0, DET_BI_STATIC_FLAG_129:0, DET_BI_STATIC_FLAG_130:0, DET_BI_STATIC_FLAG_131:0, DET_BI_STATIC_FLAG_132:0, DET_CONFD_AZIMUTH_129:0, DET_CONFD_AZIMUTH_130:0, DET_CONFD_AZIMUTH_131:0, DET_CONFD_AZIMUTH_132:0, DET_CONFD_ELEVATION_129:0, DET_CONFD_ELEVATION_130:0, DET_CONFD_ELEVATION_131:0, DET_CONFD_ELEVATION_132:0, DET_ELEVATION_129:0, DET_ELEVATION_130:0, DET_ELEVATION_131:0, DET_ELEVATION_132:0, DET_ELEVATION_ERR_129:0, DET_ELEVATION_ERR_130:0, DET_ELEVATION_ERR_131:0, DET_ELEVATION_ERR_132:0, DET_EXISTENCE_PROB_129:0, DET_EXISTENCE_PROB_130:0, DET_EXISTENCE_PROB_131:0, DET_EXISTENCE_PROB_132:0, DET_HVC_FLAG_129:0, DET_HVC_FLAG_130:0, DET_HVC_FLAG_131:0, DET_HVC_FLAG_132:0, DET_IDM_129:0, DET_IDM_130:0, DET_IDM_131:0, DET_IDM_132:0, DET_MH_CRC16_129_132:0, DET_MH_CYCLE_COUNTER_129_132:0, DET_MH_SCAN_INDEX_4LSB_129_132:0, DET_MTD_129:0, DET_MTD_130:0, DET_MTD_131:0, DET_MTD_132:0, DET_PROB_1STAZHYPO_129:0, DET_PROB_1STAZHYPO_130:0, DET_PROB_1STAZHYPO_131:0, DET_PROB_1STAZHYPO_132:0, DET_RANGE_129:0, DET_RANGE_130:0, DET_RANGE_131:0, DET_RANGE_132:0, DET_RANGE_ERR_129:0, DET_RANGE_ERR_130:0, DET_RANGE_ERR_131:0, DET_RANGE_ERR_132:0, DET_RANGE_VELOCITY_129:16384, DET_RANGE_VELOCITY_130:16384, DET_RANGE_VELOCITY_131:16384, DET_RANGE_VELOCITY_132:16384, DET_RANGE_VELOCITY_ERR_129:0, DET_RANGE_VELOCITY_ERR_130:0, DET_RANGE_VELOCITY_ERR_131:0, DET_RANGE_VELOCITY_ERR_132:0, DET_RCS_129:128, DET_RCS_130:128, DET_RCS_131:128, DET_RCS_132:128, DET_SNR_129:0, DET_SNR_130:0, DET_SNR_131:0, DET_SNR_132:0, DET_SUPER_RES_TARGET_129:0, DET_SUPER_RES_TARGET_130:0, DET_SUPER_RES_TARGET_131:0, DET_SUPER_RES_TARGET_132:0]}, provided-interface=Pi_SG_Detections_129_132_AL
      Pp_SG_Detections_133_136_AL: nonqueued-sender-com-spec{data-element=Vdp_SG_Detections_133_136_AL, init-value=fields=[DET_AZIMUTH_133:0, DET_AZIMUTH_134:0, DET_AZIMUTH_135:0, DET_AZIMUTH_136:0, DET_AZIMUTH_ERR_133:0, DET_AZIMUTH_ERR_134:0, DET_AZIMUTH_ERR_135:0, DET_AZIMUTH_ERR_136:0, DET_BELOW_RAIN_THOLD_133:0, DET_BELOW_RAIN_THOLD_134:0, DET_BELOW_RAIN_THOLD_135:0, DET_BELOW_RAIN_THOLD_136:0, DET_BI_STATIC_FLAG_133:0, DET_BI_STATIC_FLAG_134:0, DET_BI_STATIC_FLAG_135:0, DET_BI_STATIC_FLAG_136:0, DET_CONFD_AZIMUTH_133:0, DET_CONFD_AZIMUTH_134:0, DET_CONFD_AZIMUTH_135:0, DET_CONFD_AZIMUTH_136:0, DET_CONFD_ELEVATION_133:0, DET_CONFD_ELEVATION_134:0, DET_CONFD_ELEVATION_135:0, DET_CONFD_ELEVATION_136:0, DET_ELEVATION_133:0, DET_ELEVATION_134:0, DET_ELEVATION_135:0, DET_ELEVATION_136:0, DET_ELEVATION_ERR_133:0, DET_ELEVATION_ERR_134:0, DET_ELEVATION_ERR_135:0, DET_ELEVATION_ERR_136:0, DET_EXISTENCE_PROB_133:0, DET_EXISTENCE_PROB_134:0, DET_EXISTENCE_PROB_135:0, DET_EXISTENCE_PROB_136:0, DET_HVC_FLAG_133:0, DET_HVC_FLAG_134:0, DET_HVC_FLAG_135:0, DET_HVC_FLAG_136:0, DET_IDM_133:0, DET_IDM_134:0, DET_IDM_135:0, DET_IDM_136:0, DET_MH_CRC16_133_136:0, DET_MH_CYCLE_COUNTER_133_136:0, DET_MH_SCAN_INDEX_4LSB_133_136:0, DET_MTD_133:0, DET_MTD_134:0, DET_MTD_135:0, DET_MTD_136:0, DET_PROB_1STAZHYPO_133:0, DET_PROB_1STAZHYPO_134:0, DET_PROB_1STAZHYPO_135:0, DET_PROB_1STAZHYPO_136:0, DET_RANGE_133:0, DET_RANGE_134:0, DET_RANGE_135:0, DET_RANGE_136:0, DET_RANGE_ERR_133:0, DET_RANGE_ERR_134:0, DET_RANGE_ERR_135:0, DET_RANGE_ERR_136:0, DET_RANGE_VELOCITY_133:16384, DET_RANGE_VELOCITY_134:16384, DET_RANGE_VELOCITY_135:16384, DET_RANGE_VELOCITY_136:16384, DET_RANGE_VELOCITY_ERR_133:0, DET_RANGE_VELOCITY_ERR_134:0, DET_RANGE_VELOCITY_ERR_135:0, DET_RANGE_VELOCITY_ERR_136:0, DET_RCS_133:128, DET_RCS_134:128, DET_RCS_135:128, DET_RCS_136:128, DET_SNR_133:0, DET_SNR_134:0, DET_SNR_135:0, DET_SNR_136:0, DET_SUPER_RES_TARGET_133:0, DET_SUPER_RES_TARGET_134:0, DET_SUPER_RES_TARGET_135:0, DET_SUPER_RES_TARGET_136:0]}, provided-interface=Pi_SG_Detections_133_136_AL
      Pp_SG_Detections_137_140_AL: nonqueued-sender-com-spec{data-element=Vdp_SG_Detections_137_140_AL, init-value=fields=[DET_AZIMUTH_137:0, DET_AZIMUTH_138:0, DET_AZIMUTH_139:0, DET_AZIMUTH_140:0, DET_AZIMUTH_ERR_137:0, DET_AZIMUTH_ERR_138:0, DET_AZIMUTH_ERR_139:0, DET_AZIMUTH_ERR_140:0, DET_BELOW_RAIN_THOLD_137:0, DET_BELOW_RAIN_THOLD_138:0, DET_BELOW_RAIN_THOLD_139:0, DET_BELOW_RAIN_THOLD_140:0, DET_BI_STATIC_FLAG_137:0, DET_BI_STATIC_FLAG_138:0, DET_BI_STATIC_FLAG_139:0, DET_BI_STATIC_FLAG_140:0, DET_CONFD_AZIMUTH_137:0, DET_CONFD_AZIMUTH_138:0, DET_CONFD_AZIMUTH_139:0, DET_CONFD_AZIMUTH_140:0, DET_CONFD_ELEVATION_137:0, DET_CONFD_ELEVATION_138:0, DET_CONFD_ELEVATION_139:0, DET_CONFD_ELEVATION_140:0, DET_ELEVATION_137:0, DET_ELEVATION_138:0, DET_ELEVATION_139:0, DET_ELEVATION_140:0, DET_ELEVATION_ERR_137:0, DET_ELEVATION_ERR_138:0, DET_ELEVATION_ERR_139:0, DET_ELEVATION_ERR_140:0, DET_EXISTENCE_PROB_137:0, DET_EXISTENCE_PROB_138:0, DET_EXISTENCE_PROB_139:0, DET_EXISTENCE_PROB_140:0, DET_HVC_FLAG_137:0, DET_HVC_FLAG_138:0, DET_HVC_FLAG_139:0, DET_HVC_FLAG_140:0, DET_IDM_137:0, DET_IDM_138:0, DET_IDM_139:0, DET_IDM_140:0, DET_MH_CRC16_137_140:0, DET_MH_CYCLE_COUNTER_137_140:0, DET_MH_SCAN_INDEX_4LSB_137_140:0, DET_MTD_137:0, DET_MTD_138:0, DET_MTD_139:0, DET_MTD_140:0, DET_PROB_1STAZHYPO_137:0, DET_PROB_1STAZHYPO_138:0, DET_PROB_1STAZHYPO_139:0, DET_PROB_1STAZHYPO_140:0, DET_RANGE_137:0, DET_RANGE_138:0, DET_RANGE_139:0, DET_RANGE_140:0, DET_RANGE_ERR_137:0, DET_RANGE_ERR_138:0, DET_RANGE_ERR_139:0, DET_RANGE_ERR_140:0, DET_RANGE_VELOCITY_137:16384, DET_RANGE_VELOCITY_138:16384, DET_RANGE_VELOCITY_139:16384, DET_RANGE_VELOCITY_140:16384, DET_RANGE_VELOCITY_ERR_137:0, DET_RANGE_VELOCITY_ERR_138:0, DET_RANGE_VELOCITY_ERR_139:0, DET_RANGE_VELOCITY_ERR_140:0, DET_RCS_137:128, DET_RCS_138:128, DET_RCS_139:128, DET_RCS_140:128, DET_SNR_137:0, DET_SNR_138:0, DET_SNR_139:0, DET_SNR_140:0, DET_SUPER_RES_TARGET_137:0, DET_SUPER_RES_TARGET_138:0, DET_SUPER_RES_TARGET_139:0, DET_SUPER_RES_TARGET_140:0]}, provided-interface=Pi_SG_Detections_137_140_AL
      Pp_SG_Detections_141_144_AL: nonqueued-sender-com-spec{data-element=Vdp_SG_Detections_141_144_AL, init-value=fields=[DET_AZIMUTH_141:0, DET_AZIMUTH_142:0, DET_AZIMUTH_143:0, DET_AZIMUTH_144:0, DET_AZIMUTH_ERR_141:0, DET_AZIMUTH_ERR_142:0, DET_AZIMUTH_ERR_143:0, DET_AZIMUTH_ERR_144:0, DET_BELOW_RAIN_THOLD_141:0, DET_BELOW_RAIN_THOLD_142:0, DET_BELOW_RAIN_THOLD_143:0, DET_BELOW_RAIN_THOLD_144:0, DET_BI_STATIC_FLAG_141:0, DET_BI_STATIC_FLAG_142:0, DET_BI_STATIC_FLAG_143:0, DET_BI_STATIC_FLAG_144:0, DET_CONFD_AZIMUTH_141:0, DET_CONFD_AZIMUTH_142:0, DET_CONFD_AZIMUTH_143:0, DET_CONFD_AZIMUTH_144:0, DET_CONFD_ELEVATION_141:0, DET_CONFD_ELEVATION_142:0, DET_CONFD_ELEVATION_143:0, DET_CONFD_ELEVATION_144:0, DET_ELEVATION_141:0, DET_ELEVATION_142:0, DET_ELEVATION_143:0, DET_ELEVATION_144:0, DET_ELEVATION_ERR_141:0, DET_ELEVATION_ERR_142:0, DET_ELEVATION_ERR_143:0, DET_ELEVATION_ERR_144:0, DET_EXISTENCE_PROB_141:0, DET_EXISTENCE_PROB_142:0, DET_EXISTENCE_PROB_143:0, DET_EXISTENCE_PROB_144:0, DET_HVC_FLAG_141:0, DET_HVC_FLAG_142:0, DET_HVC_FLAG_143:0, DET_HVC_FLAG_144:0, DET_IDM_141:0, DET_IDM_142:0, DET_IDM_143:0, DET_IDM_144:0, DET_MH_CRC16_141_144:0, DET_MH_CYCLE_COUNTER_141_144:0, DET_MH_SCAN_INDEX_4LSB_141_144:0, DET_MTD_141:0, DET_MTD_142:0, DET_MTD_143:0, DET_MTD_144:0, DET_PROB_1STAZHYPO_141:0, DET_PROB_1STAZHYPO_142:0, DET_PROB_1STAZHYPO_143:0, DET_PROB_1STAZHYPO_144:0, DET_RANGE_141:0, DET_RANGE_142:0, DET_RANGE_143:0, DET_RANGE_144:0, DET_RANGE_ERR_141:0, DET_RANGE_ERR_142:0, DET_RANGE_ERR_143:0, DET_RANGE_ERR_144:0, DET_RANGE_VELOCITY_141:16384, DET_RANGE_VELOCITY_142:16384, DET_RANGE_VELOCITY_143:16384, DET_RANGE_VELOCITY_144:16384, DET_RANGE_VELOCITY_ERR_141:0, DET_RANGE_VELOCITY_ERR_142:0, DET_RANGE_VELOCITY_ERR_143:0, DET_RANGE_VELOCITY_ERR_144:0, DET_RCS_141:128, DET_RCS_142:128, DET_RCS_143:128, DET_RCS_144:128, DET_SNR_141:0, DET_SNR_142:0, DET_SNR_143:0, DET_SNR_144:0, DET_SUPER_RES_TARGET_141:0, DET_SUPER_RES_TARGET_142:0, DET_SUPER_RES_TARGET_143:0, DET_SUPER_RES_TARGET_144:0]}, provided-interface=Pi_SG_Detections_141_144_AL
      Pp_SG_Detections_145_148_AL: nonqueued-sender-com-spec{data-element=Vdp_SG_Detections_145_148_AL, init-value=fields=[DET_AZIMUTH_145:0, DET_AZIMUTH_146:0, DET_AZIMUTH_147:0, DET_AZIMUTH_148:0, DET_AZIMUTH_ERR_145:0, DET_AZIMUTH_ERR_146:0, DET_AZIMUTH_ERR_147:0, DET_AZIMUTH_ERR_148:0, DET_BELOW_RAIN_THOLD_145:0, DET_BELOW_RAIN_THOLD_146:0, DET_BELOW_RAIN_THOLD_147:0, DET_BELOW_RAIN_THOLD_148:0, DET_BI_STATIC_FLAG_145:0, DET_BI_STATIC_FLAG_146:0, DET_BI_STATIC_FLAG_147:0, DET_BI_STATIC_FLAG_148:0, DET_CONFD_AZIMUTH_145:0, DET_CONFD_AZIMUTH_146:0, DET_CONFD_AZIMUTH_147:0, DET_CONFD_AZIMUTH_148:0, DET_CONFD_ELEVATION_145:0, DET_CONFD_ELEVATION_146:0, DET_CONFD_ELEVATION_147:0, DET_CONFD_ELEVATION_148:0, DET_ELEVATION_145:0, DET_ELEVATION_146:0, DET_ELEVATION_147:0, DET_ELEVATION_148:0, DET_ELEVATION_ERR_145:0, DET_ELEVATION_ERR_146:0, DET_ELEVATION_ERR_147:0, DET_ELEVATION_ERR_148:0, DET_EXISTENCE_PROB_145:0, DET_EXISTENCE_PROB_146:0, DET_EXISTENCE_PROB_147:0, DET_EXISTENCE_PROB_148:0, DET_HVC_FLAG_145:0, DET_HVC_FLAG_146:0, DET_HVC_FLAG_147:0, DET_HVC_FLAG_148:0, DET_IDM_145:0, DET_IDM_146:0, DET_IDM_147:0, DET_IDM_148:0, DET_MH_CRC16_145_148:0, DET_MH_CYCLE_COUNTER_145_148:0, DET_MH_SCAN_INDEX_4LSB_145_148:0, DET_MTD_145:0, DET_MTD_146:0, DET_MTD_147:0, DET_MTD_148:0, DET_PROB_1STAZHYPO_145:0, DET_PROB_1STAZHYPO_146:0, DET_PROB_1STAZHYPO_147:0, DET_PROB_1STAZHYPO_148:0, DET_RANGE_145:0, DET_RANGE_146:0, DET_RANGE_147:0, DET_RANGE_148:0, DET_RANGE_ERR_145:0, DET_RANGE_ERR_146:0, DET_RANGE_ERR_147:0, DET_RANGE_ERR_148:0, DET_RANGE_VELOCITY_145:16384, DET_RANGE_VELOCITY_146:16384, DET_RANGE_VELOCITY_147:16384, DET_RANGE_VELOCITY_148:16384, DET_RANGE_VELOCITY_ERR_145:0, DET_RANGE_VELOCITY_ERR_146:0, DET_RANGE_VELOCITY_ERR_147:0, DET_RANGE_VELOCITY_ERR_148:0, DET_RCS_145:128, DET_RCS_146:128, DET_RCS_147:128, DET_RCS_148:128, DET_SNR_145:0, DET_SNR_146:0, DET_SNR_147:0, DET_SNR_148:0, DET_SUPER_RES_TARGET_145:0, DET_SUPER_RES_TARGET_146:0, DET_SUPER_RES_TARGET_147:0, DET_SUPER_RES_TARGET_148:0]}, provided-interface=Pi_SG_Detections_145_148_AL
      Pp_SG_Detections_149_152_AL: nonqueued-sender-com-spec{data-element=Vdp_SG_Detections_149_152_AL, init-value=fields=[DET_AZIMUTH_149:0, DET_AZIMUTH_150:0, DET_AZIMUTH_151:0, DET_AZIMUTH_152:0, DET_AZIMUTH_ERR_149:0, DET_AZIMUTH_ERR_150:0, DET_AZIMUTH_ERR_151:0, DET_AZIMUTH_ERR_152:0, DET_BELOW_RAIN_THOLD_149:0, DET_BELOW_RAIN_THOLD_150:0, DET_BELOW_RAIN_THOLD_151:0, DET_BELOW_RAIN_THOLD_152:0, DET_BI_STATIC_FLAG_149:0, DET_BI_STATIC_FLAG_150:0, DET_BI_STATIC_FLAG_151:0, DET_BI_STATIC_FLAG_152:0, DET_CONFD_AZIMUTH_149:0, DET_CONFD_AZIMUTH_150:0, DET_CONFD_AZIMUTH_151:0, DET_CONFD_AZIMUTH_152:0, DET_CONFD_ELEVATION_149:0, DET_CONFD_ELEVATION_150:0, DET_CONFD_ELEVATION_151:0, DET_CONFD_ELEVATION_152:0, DET_ELEVATION_149:0, DET_ELEVATION_150:0, DET_ELEVATION_151:0, DET_ELEVATION_152:0, DET_ELEVATION_ERR_149:0, DET_ELEVATION_ERR_150:0, DET_ELEVATION_ERR_151:0, DET_ELEVATION_ERR_152:0, DET_EXISTENCE_PROB_149:0, DET_EXISTENCE_PROB_150:0, DET_EXISTENCE_PROB_151:0, DET_EXISTENCE_PROB_152:0, DET_HVC_FLAG_149:0, DET_HVC_FLAG_150:0, DET_HVC_FLAG_151:0, DET_HVC_FLAG_152:0, DET_IDM_149:0, DET_IDM_150:0, DET_IDM_151:0, DET_IDM_152:0, DET_MH_CRC16_149_152:0, DET_MH_CYCLE_COUNTER_149_152:0, DET_MH_SCAN_INDEX_4LSB_149_152:0, DET_MTD_149:0, DET_MTD_150:0, DET_MTD_151:0, DET_MTD_152:0, DET_PROB_1STAZHYPO_149:0, DET_PROB_1STAZHYPO_150:0, DET_PROB_1STAZHYPO_151:0, DET_PROB_1STAZHYPO_152:0, DET_RANGE_149:0, DET_RANGE_150:0, DET_RANGE_151:0, DET_RANGE_152:0, DET_RANGE_ERR_149:0, DET_RANGE_ERR_150:0, DET_RANGE_ERR_151:0, DET_RANGE_ERR_152:0, DET_RANGE_VELOCITY_149:16384, DET_RANGE_VELOCITY_150:16384, DET_RANGE_VELOCITY_151:16384, DET_RANGE_VELOCITY_152:16384, DET_RANGE_VELOCITY_ERR_149:0, DET_RANGE_VELOCITY_ERR_150:0, DET_RANGE_VELOCITY_ERR_151:0, DET_RANGE_VELOCITY_ERR_152:0, DET_RCS_149:128, DET_RCS_150:128, DET_RCS_151:128, DET_RCS_152:128, DET_SNR_149:0, DET_SNR_150:0, DET_SNR_151:0, DET_SNR_152:0, DET_SUPER_RES_TARGET_149:0, DET_SUPER_RES_TARGET_150:0, DET_SUPER_RES_TARGET_151:0, DET_SUPER_RES_TARGET_152:0]}, provided-interface=Pi_SG_Detections_149_152_AL
      Pp_SG_Detections_153_156_AL: nonqueued-sender-com-spec{data-element=Vdp_SG_Detections_153_156_AL, init-value=fields=[DET_AZIMUTH_153:0, DET_AZIMUTH_154:0, DET_AZIMUTH_155:0, DET_AZIMUTH_156:0, DET_AZIMUTH_ERR_153:0, DET_AZIMUTH_ERR_154:0, DET_AZIMUTH_ERR_155:0, DET_AZIMUTH_ERR_156:0, DET_BELOW_RAIN_THOLD_153:0, DET_BELOW_RAIN_THOLD_154:0, DET_BELOW_RAIN_THOLD_155:0, DET_BELOW_RAIN_THOLD_156:0, DET_BI_STATIC_FLAG_153:0, DET_BI_STATIC_FLAG_154:0, DET_BI_STATIC_FLAG_155:0, DET_BI_STATIC_FLAG_156:0, DET_CONFD_AZIMUTH_153:0, DET_CONFD_AZIMUTH_154:0, DET_CONFD_AZIMUTH_155:0, DET_CONFD_AZIMUTH_156:0, DET_CONFD_ELEVATION_153:0, DET_CONFD_ELEVATION_154:0, DET_CONFD_ELEVATION_155:0, DET_CONFD_ELEVATION_156:0, DET_ELEVATION_153:0, DET_ELEVATION_154:0, DET_ELEVATION_155:0, DET_ELEVATION_156:0, DET_ELEVATION_ERR_153:0, DET_ELEVATION_ERR_154:0, DET_ELEVATION_ERR_155:0, DET_ELEVATION_ERR_156:0, DET_EXISTENCE_PROB_153:0, DET_EXISTENCE_PROB_154:0, DET_EXISTENCE_PROB_155:0, DET_EXISTENCE_PROB_156:0, DET_HVC_FLAG_153:0, DET_HVC_FLAG_154:0, DET_HVC_FLAG_155:0, DET_HVC_FLAG_156:0, DET_IDM_153:0, DET_IDM_154:0, DET_IDM_155:0, DET_IDM_156:0, DET_MH_CRC16_153_156:0, DET_MH_CYCLE_COUNTER_153_156:0, DET_MH_SCAN_INDEX_4LSB_153_156:0, DET_MTD_153:0, DET_MTD_154:0, DET_MTD_155:0, DET_MTD_156:0, DET_PROB_1STAZHYPO_153:0, DET_PROB_1STAZHYPO_154:0, DET_PROB_1STAZHYPO_155:0, DET_PROB_1STAZHYPO_156:0, DET_RANGE_153:0, DET_RANGE_154:0, DET_RANGE_155:0, DET_RANGE_156:0, DET_RANGE_ERR_153:0, DET_RANGE_ERR_154:0, DET_RANGE_ERR_155:0, DET_RANGE_ERR_156:0, DET_RANGE_VELOCITY_153:16384, DET_RANGE_VELOCITY_154:16384, DET_RANGE_VELOCITY_155:16384, DET_RANGE_VELOCITY_156:16384, DET_RANGE_VELOCITY_ERR_153:0, DET_RANGE_VELOCITY_ERR_154:0, DET_RANGE_VELOCITY_ERR_155:0, DET_RANGE_VELOCITY_ERR_156:0, DET_RCS_153:128, DET_RCS_154:128, DET_RCS_155:128, DET_RCS_156:128, DET_SNR_153:0, DET_SNR_154:0, DET_SNR_155:0, DET_SNR_156:0, DET_SUPER_RES_TARGET_153:0, DET_SUPER_RES_TARGET_154:0, DET_SUPER_RES_TARGET_155:0, DET_SUPER_RES_TARGET_156:0]}, provided-interface=Pi_SG_Detections_153_156_AL
      Pp_SG_Detections_157_160_AL: nonqueued-sender-com-spec{data-element=Vdp_SG_Detections_157_160_AL, init-value=fields=[DET_AZIMUTH_157:0, DET_AZIMUTH_158:0, DET_AZIMUTH_159:0, DET_AZIMUTH_160:0, DET_AZIMUTH_ERR_157:0, DET_AZIMUTH_ERR_158:0, DET_AZIMUTH_ERR_159:0, DET_AZIMUTH_ERR_160:0, DET_BELOW_RAIN_THOLD_157:0, DET_BELOW_RAIN_THOLD_158:0, DET_BELOW_RAIN_THOLD_159:0, DET_BELOW_RAIN_THOLD_160:0, DET_BI_STATIC_FLAG_157:0, DET_BI_STATIC_FLAG_158:0, DET_BI_STATIC_FLAG_159:0, DET_BI_STATIC_FLAG_160:0, DET_CONFD_AZIMUTH_157:0, DET_CONFD_AZIMUTH_158:0, DET_CONFD_AZIMUTH_159:0, DET_CONFD_AZIMUTH_160:0, DET_CONFD_ELEVATION_157:0, DET_CONFD_ELEVATION_158:0, DET_CONFD_ELEVATION_159:0, DET_CONFD_ELEVATION_160:0, DET_ELEVATION_157:0, DET_ELEVATION_158:0, DET_ELEVATION_159:0, DET_ELEVATION_160:0, DET_ELEVATION_ERR_157:0, DET_ELEVATION_ERR_158:0, DET_ELEVATION_ERR_159:0, DET_ELEVATION_ERR_160:0, DET_EXISTENCE_PROB_157:0, DET_EXISTENCE_PROB_158:0, DET_EXISTENCE_PROB_159:0, DET_EXISTENCE_PROB_160:0, DET_HVC_FLAG_157:0, DET_HVC_FLAG_158:0, DET_HVC_FLAG_159:0, DET_HVC_FLAG_160:0, DET_IDM_157:0, DET_IDM_158:0, DET_IDM_159:0, DET_IDM_160:0, DET_MH_CRC16_157_160:0, DET_MH_CYCLE_COUNTER_157_160:0, DET_MH_SCAN_INDEX_4LSB_157_160:0, DET_MTD_157:0, DET_MTD_158:0, DET_MTD_159:0, DET_MTD_160:0, DET_PROB_1STAZHYPO_157:0, DET_PROB_1STAZHYPO_158:0, DET_PROB_1STAZHYPO_159:0, DET_PROB_1STAZHYPO_160:0, DET_RANGE_157:0, DET_RANGE_158:0, DET_RANGE_159:0, DET_RANGE_160:0, DET_RANGE_ERR_157:0, DET_RANGE_ERR_158:0, DET_RANGE_ERR_159:0, DET_RANGE_ERR_160:0, DET_RANGE_VELOCITY_157:16384, DET_RANGE_VELOCITY_158:16384, DET_RANGE_VELOCITY_159:16384, DET_RANGE_VELOCITY_160:16384, DET_RANGE_VELOCITY_ERR_157:0, DET_RANGE_VELOCITY_ERR_158:0, DET_RANGE_VELOCITY_ERR_159:0, DET_RANGE_VELOCITY_ERR_160:0, DET_RCS_157:128, DET_RCS_158:128, DET_RCS_159:128, DET_RCS_160:128, DET_SNR_157:0, DET_SNR_158:0, DET_SNR_159:0, DET_SNR_160:0, DET_SUPER_RES_TARGET_157:0, DET_SUPER_RES_TARGET_158:0, DET_SUPER_RES_TARGET_159:0, DET_SUPER_RES_TARGET_160:0]}, provided-interface=Pi_SG_Detections_157_160_AL
      Pp_SG_Detections_161_164_AL: nonqueued-sender-com-spec{data-element=Vdp_SG_Detections_161_164_AL, init-value=fields=[DET_AZIMUTH_161:0, DET_AZIMUTH_162:0, DET_AZIMUTH_163:0, DET_AZIMUTH_164:0, DET_AZIMUTH_ERR_161:0, DET_AZIMUTH_ERR_162:0, DET_AZIMUTH_ERR_163:0, DET_AZIMUTH_ERR_164:0, DET_BELOW_RAIN_THOLD_161:0, DET_BELOW_RAIN_THOLD_162:0, DET_BELOW_RAIN_THOLD_163:0, DET_BELOW_RAIN_THOLD_164:0, DET_BI_STATIC_FLAG_161:0, DET_BI_STATIC_FLAG_162:0, DET_BI_STATIC_FLAG_163:0, DET_BI_STATIC_FLAG_164:0, DET_CONFD_AZIMUTH_161:0, DET_CONFD_AZIMUTH_162:0, DET_CONFD_AZIMUTH_163:0, DET_CONFD_AZIMUTH_164:0, DET_CONFD_ELEVATION_161:0, DET_CONFD_ELEVATION_162:0, DET_CONFD_ELEVATION_163:0, DET_CONFD_ELEVATION_164:0, DET_ELEVATION_161:0, DET_ELEVATION_162:0, DET_ELEVATION_163:0, DET_ELEVATION_164:0, DET_ELEVATION_ERR_161:0, DET_ELEVATION_ERR_162:0, DET_ELEVATION_ERR_163:0, DET_ELEVATION_ERR_164:0, DET_EXISTENCE_PROB_161:0, DET_EXISTENCE_PROB_162:0, DET_EXISTENCE_PROB_163:0, DET_EXISTENCE_PROB_164:0, DET_HVC_FLAG_161:0, DET_HVC_FLAG_162:0, DET_HVC_FLAG_163:0, DET_HVC_FLAG_164:0, DET_IDM_161:0, DET_IDM_162:0, DET_IDM_163:0, DET_IDM_164:0, DET_MH_CRC16_161_164:0, DET_MH_CYCLE_COUNTER_161_164:0, DET_MH_SCAN_INDEX_4LSB_161_164:0, DET_MTD_161:0, DET_MTD_162:0, DET_MTD_163:0, DET_MTD_164:0, DET_PROB_1STAZHYPO_161:0, DET_PROB_1STAZHYPO_162:0, DET_PROB_1STAZHYPO_163:0, DET_PROB_1STAZHYPO_164:0, DET_RANGE_161:0, DET_RANGE_162:0, DET_RANGE_163:0, DET_RANGE_164:0, DET_RANGE_ERR_161:0, DET_RANGE_ERR_162:0, DET_RANGE_ERR_163:0, DET_RANGE_ERR_164:0, DET_RANGE_VELOCITY_161:16384, DET_RANGE_VELOCITY_162:16384, DET_RANGE_VELOCITY_163:16384, DET_RANGE_VELOCITY_164:16384, DET_RANGE_VELOCITY_ERR_161:0, DET_RANGE_VELOCITY_ERR_162:0, DET_RANGE_VELOCITY_ERR_163:0, DET_RANGE_VELOCITY_ERR_164:0, DET_RCS_161:128, DET_RCS_162:128, DET_RCS_163:128, DET_RCS_164:128, DET_SNR_161:0, DET_SNR_162:0, DET_SNR_163:0, DET_SNR_164:0, DET_SUPER_RES_TARGET_161:0, DET_SUPER_RES_TARGET_162:0, DET_SUPER_RES_TARGET_163:0, DET_SUPER_RES_TARGET_164:0]}, provided-interface=Pi_SG_Detections_161_164_AL
      Pp_SG_Detections_165_168_AL: nonqueued-sender-com-spec{data-element=Vdp_SG_Detections_165_168_AL, init-value=fields=[DET_AZIMUTH_165:0, DET_AZIMUTH_166:0, DET_AZIMUTH_167:0, DET_AZIMUTH_168:0, DET_AZIMUTH_ERR_165:0, DET_AZIMUTH_ERR_166:0, DET_AZIMUTH_ERR_167:0, DET_AZIMUTH_ERR_168:0, DET_BELOW_RAIN_THOLD_165:0, DET_BELOW_RAIN_THOLD_166:0, DET_BELOW_RAIN_THOLD_167:0, DET_BELOW_RAIN_THOLD_168:0, DET_BI_STATIC_FLAG_165:0, DET_BI_STATIC_FLAG_166:0, DET_BI_STATIC_FLAG_167:0, DET_BI_STATIC_FLAG_168:0, DET_CONFD_AZIMUTH_165:0, DET_CONFD_AZIMUTH_166:0, DET_CONFD_AZIMUTH_167:0, DET_CONFD_AZIMUTH_168:0, DET_CONFD_ELEVATION_165:0, DET_CONFD_ELEVATION_166:0, DET_CONFD_ELEVATION_167:0, DET_CONFD_ELEVATION_168:0, DET_ELEVATION_165:0, DET_ELEVATION_166:0, DET_ELEVATION_167:0, DET_ELEVATION_168:0, DET_ELEVATION_ERR_165:0, DET_ELEVATION_ERR_166:0, DET_ELEVATION_ERR_167:0, DET_ELEVATION_ERR_168:0, DET_EXISTENCE_PROB_165:0, DET_EXISTENCE_PROB_166:0, DET_EXISTENCE_PROB_167:0, DET_EXISTENCE_PROB_168:0, DET_HVC_FLAG_165:0, DET_HVC_FLAG_166:0, DET_HVC_FLAG_167:0, DET_HVC_FLAG_168:0, DET_IDM_165:0, DET_IDM_166:0, DET_IDM_167:0, DET_IDM_168:0, DET_MH_CRC16_165_168:0, DET_MH_CYCLE_COUNTER_165_168:0, DET_MH_SCAN_INDEX_4LSB_165_168:0, DET_MTD_165:0, DET_MTD_166:0, DET_MTD_167:0, DET_MTD_168:0, DET_PROB_1STAZHYPO_165:0, DET_PROB_1STAZHYPO_166:0, DET_PROB_1STAZHYPO_167:0, DET_PROB_1STAZHYPO_168:0, DET_RANGE_165:0, DET_RANGE_166:0, DET_RANGE_167:0, DET_RANGE_168:0, DET_RANGE_ERR_165:0, DET_RANGE_ERR_166:0, DET_RANGE_ERR_167:0, DET_RANGE_ERR_168:0, DET_RANGE_VELOCITY_165:16384, DET_RANGE_VELOCITY_166:16384, DET_RANGE_VELOCITY_167:16384, DET_RANGE_VELOCITY_168:16384, DET_RANGE_VELOCITY_ERR_165:0, DET_RANGE_VELOCITY_ERR_166:0, DET_RANGE_VELOCITY_ERR_167:0, DET_RANGE_VELOCITY_ERR_168:0, DET_RCS_165:128, DET_RCS_166:128, DET_RCS_167:128, DET_RCS_168:128, DET_SNR_165:0, DET_SNR_166:0, DET_SNR_167:0, DET_SNR_168:0, DET_SUPER_RES_TARGET_165:0, DET_SUPER_RES_TARGET_166:0, DET_SUPER_RES_TARGET_167:0, DET_SUPER_RES_TARGET_168:0]}, provided-interface=Pi_SG_Detections_165_168_AL
      Pp_SG_Detections_169_172_AL: nonqueued-sender-com-spec{data-element=Vdp_SG_Detections_169_172_AL, init-value=fields=[DET_AZIMUTH_169:0, DET_AZIMUTH_170:0, DET_AZIMUTH_171:0, DET_AZIMUTH_172:0, DET_AZIMUTH_ERR_169:0, DET_AZIMUTH_ERR_170:0, DET_AZIMUTH_ERR_171:0, DET_AZIMUTH_ERR_172:0, DET_BELOW_RAIN_THOLD_169:0, DET_BELOW_RAIN_THOLD_170:0, DET_BELOW_RAIN_THOLD_171:0, DET_BELOW_RAIN_THOLD_172:0, DET_BI_STATIC_FLAG_169:0, DET_BI_STATIC_FLAG_170:0, DET_BI_STATIC_FLAG_171:0, DET_BI_STATIC_FLAG_172:0, DET_CONFD_AZIMUTH_169:0, DET_CONFD_AZIMUTH_170:0, DET_CONFD_AZIMUTH_171:0, DET_CONFD_AZIMUTH_172:0, DET_CONFD_ELEVATION_169:0, DET_CONFD_ELEVATION_170:0, DET_CONFD_ELEVATION_171:0, DET_CONFD_ELEVATION_172:0, DET_ELEVATION_169:0, DET_ELEVATION_170:0, DET_ELEVATION_171:0, DET_ELEVATION_172:0, DET_ELEVATION_ERR_169:0, DET_ELEVATION_ERR_170:0, DET_ELEVATION_ERR_171:0, DET_ELEVATION_ERR_172:0, DET_EXISTENCE_PROB_169:0, DET_EXISTENCE_PROB_170:0, DET_EXISTENCE_PROB_171:0, DET_EXISTENCE_PROB_172:0, DET_HVC_FLAG_169:0, DET_HVC_FLAG_170:0, DET_HVC_FLAG_171:0, DET_HVC_FLAG_172:0, DET_IDM_169:0, DET_IDM_170:0, DET_IDM_171:0, DET_IDM_172:0, DET_MH_CRC16_169_172:0, DET_MH_CYCLE_COUNTER_169_172:0, DET_MH_SCAN_INDEX_4LSB_169_172:0, DET_MTD_169:0, DET_MTD_170:0, DET_MTD_171:0, DET_MTD_172:0, DET_PROB_1STAZHYPO_169:0, DET_PROB_1STAZHYPO_170:0, DET_PROB_1STAZHYPO_171:0, DET_PROB_1STAZHYPO_172:0, DET_RANGE_169:0, DET_RANGE_170:0, DET_RANGE_171:0, DET_RANGE_172:0, DET_RANGE_ERR_169:0, DET_RANGE_ERR_170:0, DET_RANGE_ERR_171:0, DET_RANGE_ERR_172:0, DET_RANGE_VELOCITY_169:16384, DET_RANGE_VELOCITY_170:16384, DET_RANGE_VELOCITY_171:16384, DET_RANGE_VELOCITY_172:16384, DET_RANGE_VELOCITY_ERR_169:0, DET_RANGE_VELOCITY_ERR_170:0, DET_RANGE_VELOCITY_ERR_171:0, DET_RANGE_VELOCITY_ERR_172:0, DET_RCS_169:128, DET_RCS_170:128, DET_RCS_171:128, DET_RCS_172:128, DET_SNR_169:0, DET_SNR_170:0, DET_SNR_171:0, DET_SNR_172:0, DET_SUPER_RES_TARGET_169:0, DET_SUPER_RES_TARGET_170:0, DET_SUPER_RES_TARGET_171:0, DET_SUPER_RES_TARGET_172:0]}, provided-interface=Pi_SG_Detections_169_172_AL
      Pp_SG_Detections_173_176_AL: nonqueued-sender-com-spec{data-element=Vdp_SG_Detections_173_176_AL, init-value=fields=[DET_AZIMUTH_173:0, DET_AZIMUTH_174:0, DET_AZIMUTH_175:0, DET_AZIMUTH_176:0, DET_AZIMUTH_ERR_173:0, DET_AZIMUTH_ERR_174:0, DET_AZIMUTH_ERR_175:0, DET_AZIMUTH_ERR_176:0, DET_BELOW_RAIN_THOLD_173:0, DET_BELOW_RAIN_THOLD_174:0, DET_BELOW_RAIN_THOLD_175:0, DET_BELOW_RAIN_THOLD_176:0, DET_BI_STATIC_FLAG_173:0, DET_BI_STATIC_FLAG_174:0, DET_BI_STATIC_FLAG_175:0, DET_BI_STATIC_FLAG_176:0, DET_CONFD_AZIMUTH_173:0, DET_CONFD_AZIMUTH_174:0, DET_CONFD_AZIMUTH_175:0, DET_CONFD_AZIMUTH_176:0, DET_CONFD_ELEVATION_173:0, DET_CONFD_ELEVATION_174:0, DET_CONFD_ELEVATION_175:0, DET_CONFD_ELEVATION_176:0, DET_ELEVATION_173:0, DET_ELEVATION_174:0, DET_ELEVATION_175:0, DET_ELEVATION_176:0, DET_ELEVATION_ERR_173:0, DET_ELEVATION_ERR_174:0, DET_ELEVATION_ERR_175:0, DET_ELEVATION_ERR_176:0, DET_EXISTENCE_PROB_173:0, DET_EXISTENCE_PROB_174:0, DET_EXISTENCE_PROB_175:0, DET_EXISTENCE_PROB_176:0, DET_HVC_FLAG_173:0, DET_HVC_FLAG_174:0, DET_HVC_FLAG_175:0, DET_HVC_FLAG_176:0, DET_IDM_173:0, DET_IDM_174:0, DET_IDM_175:0, DET_IDM_176:0, DET_MH_CRC16_173_176:0, DET_MH_CYCLE_COUNTER_173_176:0, DET_MH_SCAN_INDEX_4LSB_173_176:0, DET_MTD_173:0, DET_MTD_174:0, DET_MTD_175:0, DET_MTD_176:0, DET_PROB_1STAZHYPO_173:0, DET_PROB_1STAZHYPO_174:0, DET_PROB_1STAZHYPO_175:0, DET_PROB_1STAZHYPO_176:0, DET_RANGE_173:0, DET_RANGE_174:0, DET_RANGE_175:0, DET_RANGE_176:0, DET_RANGE_ERR_173:0, DET_RANGE_ERR_174:0, DET_RANGE_ERR_175:0, DET_RANGE_ERR_176:0, DET_RANGE_VELOCITY_173:16384, DET_RANGE_VELOCITY_174:16384, DET_RANGE_VELOCITY_175:16384, DET_RANGE_VELOCITY_176:16384, DET_RANGE_VELOCITY_ERR_173:0, DET_RANGE_VELOCITY_ERR_174:0, DET_RANGE_VELOCITY_ERR_175:0, DET_RANGE_VELOCITY_ERR_176:0, DET_RCS_173:128, DET_RCS_174:128, DET_RCS_175:128, DET_RCS_176:128, DET_SNR_173:0, DET_SNR_174:0, DET_SNR_175:0, DET_SNR_176:0, DET_SUPER_RES_TARGET_173:0, DET_SUPER_RES_TARGET_174:0, DET_SUPER_RES_TARGET_175:0, DET_SUPER_RES_TARGET_176:0]}, provided-interface=Pi_SG_Detections_173_176_AL
      Pp_SG_Detections_177_180_AL: nonqueued-sender-com-spec{data-element=Vdp_SG_Detections_177_180_AL, init-value=fields=[DET_AZIMUTH_177:0, DET_AZIMUTH_178:0, DET_AZIMUTH_179:0, DET_AZIMUTH_180:0, DET_AZIMUTH_ERR_177:0, DET_AZIMUTH_ERR_178:0, DET_AZIMUTH_ERR_179:0, DET_AZIMUTH_ERR_180:0, DET_BELOW_RAIN_THOLD_177:0, DET_BELOW_RAIN_THOLD_178:0, DET_BELOW_RAIN_THOLD_179:0, DET_BELOW_RAIN_THOLD_180:0, DET_BI_STATIC_FLAG_177:0, DET_BI_STATIC_FLAG_178:0, DET_BI_STATIC_FLAG_179:0, DET_BI_STATIC_FLAG_180:0, DET_CONFD_AZIMUTH_177:0, DET_CONFD_AZIMUTH_178:0, DET_CONFD_AZIMUTH_179:0, DET_CONFD_AZIMUTH_180:0, DET_CONFD_ELEVATION_177:0, DET_CONFD_ELEVATION_178:0, DET_CONFD_ELEVATION_179:0, DET_CONFD_ELEVATION_180:0, DET_ELEVATION_177:0, DET_ELEVATION_178:0, DET_ELEVATION_179:0, DET_ELEVATION_180:0, DET_ELEVATION_ERR_177:0, DET_ELEVATION_ERR_178:0, DET_ELEVATION_ERR_179:0, DET_ELEVATION_ERR_180:0, DET_EXISTENCE_PROB_177:0, DET_EXISTENCE_PROB_178:0, DET_EXISTENCE_PROB_179:0, DET_EXISTENCE_PROB_180:0, DET_HVC_FLAG_177:0, DET_HVC_FLAG_178:0, DET_HVC_FLAG_179:0, DET_HVC_FLAG_180:0, DET_IDM_177:0, DET_IDM_178:0, DET_IDM_179:0, DET_IDM_180:0, DET_MH_CRC16_177_180:0, DET_MH_CYCLE_COUNTER_177_180:0, DET_MH_SCAN_INDEX_4LSB_177_180:0, DET_MTD_177:0, DET_MTD_178:0, DET_MTD_179:0, DET_MTD_180:0, DET_PROB_1STAZHYPO_177:0, DET_PROB_1STAZHYPO_178:0, DET_PROB_1STAZHYPO_179:0, DET_PROB_1STAZHYPO_180:0, DET_RANGE_177:0, DET_RANGE_178:0, DET_RANGE_179:0, DET_RANGE_180:0, DET_RANGE_ERR_177:0, DET_RANGE_ERR_178:0, DET_RANGE_ERR_179:0, DET_RANGE_ERR_180:0, DET_RANGE_VELOCITY_177:16384, DET_RANGE_VELOCITY_178:16384, DET_RANGE_VELOCITY_179:16384, DET_RANGE_VELOCITY_180:16384, DET_RANGE_VELOCITY_ERR_177:0, DET_RANGE_VELOCITY_ERR_178:0, DET_RANGE_VELOCITY_ERR_179:0, DET_RANGE_VELOCITY_ERR_180:0, DET_RCS_177:128, DET_RCS_178:128, DET_RCS_179:128, DET_RCS_180:128, DET_SNR_177:0, DET_SNR_178:0, DET_SNR_179:0, DET_SNR_180:0, DET_SUPER_RES_TARGET_177:0, DET_SUPER_RES_TARGET_178:0, DET_SUPER_RES_TARGET_179:0, DET_SUPER_RES_TARGET_180:0]}, provided-interface=Pi_SG_Detections_177_180_AL
      Pp_SG_Detections_181_184_AL: nonqueued-sender-com-spec{data-element=Vdp_SG_Detections_181_184_AL, init-value=fields=[DET_AZIMUTH_181:0, DET_AZIMUTH_182:0, DET_AZIMUTH_183:0, DET_AZIMUTH_184:0, DET_AZIMUTH_ERR_181:0, DET_AZIMUTH_ERR_182:0, DET_AZIMUTH_ERR_183:0, DET_AZIMUTH_ERR_184:0, DET_BELOW_RAIN_THOLD_181:0, DET_BELOW_RAIN_THOLD_182:0, DET_BELOW_RAIN_THOLD_183:0, DET_BELOW_RAIN_THOLD_184:0, DET_BI_STATIC_FLAG_181:0, DET_BI_STATIC_FLAG_182:0, DET_BI_STATIC_FLAG_183:0, DET_BI_STATIC_FLAG_184:0, DET_CONFD_AZIMUTH_181:0, DET_CONFD_AZIMUTH_182:0, DET_CONFD_AZIMUTH_183:0, DET_CONFD_AZIMUTH_184:0, DET_CONFD_ELEVATION_181:0, DET_CONFD_ELEVATION_182:0, DET_CONFD_ELEVATION_183:0, DET_CONFD_ELEVATION_184:0, DET_ELEVATION_181:0, DET_ELEVATION_182:0, DET_ELEVATION_183:0, DET_ELEVATION_184:0, DET_ELEVATION_ERR_181:0, DET_ELEVATION_ERR_182:0, DET_ELEVATION_ERR_183:0, DET_ELEVATION_ERR_184:0, DET_EXISTENCE_PROB_181:0, DET_EXISTENCE_PROB_182:0, DET_EXISTENCE_PROB_183:0, DET_EXISTENCE_PROB_184:0, DET_HVC_FLAG_181:0, DET_HVC_FLAG_182:0, DET_HVC_FLAG_183:0, DET_HVC_FLAG_184:0, DET_IDM_181:0, DET_IDM_182:0, DET_IDM_183:0, DET_IDM_184:0, DET_MH_CRC16_181_184:0, DET_MH_CYCLE_COUNTER_181_184:0, DET_MH_SCAN_INDEX_4LSB_181_184:0, DET_MTD_181:0, DET_MTD_182:0, DET_MTD_183:0, DET_MTD_184:0, DET_PROB_1STAZHYPO_181:0, DET_PROB_1STAZHYPO_182:0, DET_PROB_1STAZHYPO_183:0, DET_PROB_1STAZHYPO_184:0, DET_RANGE_181:0, DET_RANGE_182:0, DET_RANGE_183:0, DET_RANGE_184:0, DET_RANGE_ERR_181:0, DET_RANGE_ERR_182:0, DET_RANGE_ERR_183:0, DET_RANGE_ERR_184:0, DET_RANGE_VELOCITY_181:16384, DET_RANGE_VELOCITY_182:16384, DET_RANGE_VELOCITY_183:16384, DET_RANGE_VELOCITY_184:16384, DET_RANGE_VELOCITY_ERR_181:0, DET_RANGE_VELOCITY_ERR_182:0, DET_RANGE_VELOCITY_ERR_183:0, DET_RANGE_VELOCITY_ERR_184:0, DET_RCS_181:128, DET_RCS_182:128, DET_RCS_183:128, DET_RCS_184:128, DET_SNR_181:0, DET_SNR_182:0, DET_SNR_183:0, DET_SNR_184:0, DET_SUPER_RES_TARGET_181:0, DET_SUPER_RES_TARGET_182:0, DET_SUPER_RES_TARGET_183:0, DET_SUPER_RES_TARGET_184:0]}, provided-interface=Pi_SG_Detections_181_184_AL
      Pp_SG_Detections_185_188_AL: nonqueued-sender-com-spec{data-element=Vdp_SG_Detections_185_188_AL, init-value=fields=[DET_AZIMUTH_185:0, DET_AZIMUTH_186:0, DET_AZIMUTH_187:0, DET_AZIMUTH_188:0, DET_AZIMUTH_ERR_185:0, DET_AZIMUTH_ERR_186:0, DET_AZIMUTH_ERR_187:0, DET_AZIMUTH_ERR_188:0, DET_BELOW_RAIN_THOLD_185:0, DET_BELOW_RAIN_THOLD_186:0, DET_BELOW_RAIN_THOLD_187:0, DET_BELOW_RAIN_THOLD_188:0, DET_BI_STATIC_FLAG_185:0, DET_BI_STATIC_FLAG_186:0, DET_BI_STATIC_FLAG_187:0, DET_BI_STATIC_FLAG_188:0, DET_CONFD_AZIMUTH_185:0, DET_CONFD_AZIMUTH_186:0, DET_CONFD_AZIMUTH_187:0, DET_CONFD_AZIMUTH_188:0, DET_CONFD_ELEVATION_185:0, DET_CONFD_ELEVATION_186:0, DET_CONFD_ELEVATION_187:0, DET_CONFD_ELEVATION_188:0, DET_ELEVATION_185:0, DET_ELEVATION_186:0, DET_ELEVATION_187:0, DET_ELEVATION_188:0, DET_ELEVATION_ERR_185:0, DET_ELEVATION_ERR_186:0, DET_ELEVATION_ERR_187:0, DET_ELEVATION_ERR_188:0, DET_EXISTENCE_PROB_185:0, DET_EXISTENCE_PROB_186:0, DET_EXISTENCE_PROB_187:0, DET_EXISTENCE_PROB_188:0, DET_HVC_FLAG_185:0, DET_HVC_FLAG_186:0, DET_HVC_FLAG_187:0, DET_HVC_FLAG_188:0, DET_IDM_185:0, DET_IDM_186:0, DET_IDM_187:0, DET_IDM_188:0, DET_MH_CRC16_185_188:0, DET_MH_CYCLE_COUNTER_185_188:0, DET_MH_SCAN_INDEX_4LSB_185_188:0, DET_MTD_185:0, DET_MTD_186:0, DET_MTD_187:0, DET_MTD_188:0, DET_PROB_1STAZHYPO_185:0, DET_PROB_1STAZHYPO_186:0, DET_PROB_1STAZHYPO_187:0, DET_PROB_1STAZHYPO_188:0, DET_RANGE_185:0, DET_RANGE_186:0, DET_RANGE_187:0, DET_RANGE_188:0, DET_RANGE_ERR_185:0, DET_RANGE_ERR_186:0, DET_RANGE_ERR_187:0, DET_RANGE_ERR_188:0, DET_RANGE_VELOCITY_185:16384, DET_RANGE_VELOCITY_186:16384, DET_RANGE_VELOCITY_187:16384, DET_RANGE_VELOCITY_188:16384, DET_RANGE_VELOCITY_ERR_185:0, DET_RANGE_VELOCITY_ERR_186:0, DET_RANGE_VELOCITY_ERR_187:0, DET_RANGE_VELOCITY_ERR_188:0, DET_RCS_185:128, DET_RCS_186:128, DET_RCS_187:128, DET_RCS_188:128, DET_SNR_185:0, DET_SNR_186:0, DET_SNR_187:0, DET_SNR_188:0, DET_SUPER_RES_TARGET_185:0, DET_SUPER_RES_TARGET_186:0, DET_SUPER_RES_TARGET_187:0, DET_SUPER_RES_TARGET_188:0]}, provided-interface=Pi_SG_Detections_185_188_AL
      Pp_SG_Detections_189_192_AL: nonqueued-sender-com-spec{data-element=Vdp_SG_Detections_189_192_AL, init-value=fields=[DET_AZIMUTH_189:0, DET_AZIMUTH_190:0, DET_AZIMUTH_191:0, DET_AZIMUTH_192:0, DET_AZIMUTH_ERR_189:0, DET_AZIMUTH_ERR_190:0, DET_AZIMUTH_ERR_191:0, DET_AZIMUTH_ERR_192:0, DET_BELOW_RAIN_THOLD_189:0, DET_BELOW_RAIN_THOLD_190:0, DET_BELOW_RAIN_THOLD_191:0, DET_BELOW_RAIN_THOLD_192:0, DET_BI_STATIC_FLAG_189:0, DET_BI_STATIC_FLAG_190:0, DET_BI_STATIC_FLAG_191:0, DET_BI_STATIC_FLAG_192:0, DET_CONFD_AZIMUTH_189:0, DET_CONFD_AZIMUTH_190:0, DET_CONFD_AZIMUTH_191:0, DET_CONFD_AZIMUTH_192:0, DET_CONFD_ELEVATION_189:0, DET_CONFD_ELEVATION_190:0, DET_CONFD_ELEVATION_191:0, DET_CONFD_ELEVATION_192:0, DET_ELEVATION_189:0, DET_ELEVATION_190:0, DET_ELEVATION_191:0, DET_ELEVATION_192:0, DET_ELEVATION_ERR_189:0, DET_ELEVATION_ERR_190:0, DET_ELEVATION_ERR_191:0, DET_ELEVATION_ERR_192:0, DET_EXISTENCE_PROB_189:0, DET_EXISTENCE_PROB_190:0, DET_EXISTENCE_PROB_191:0, DET_EXISTENCE_PROB_192:0, DET_HVC_FLAG_189:0, DET_HVC_FLAG_190:0, DET_HVC_FLAG_191:0, DET_HVC_FLAG_192:0, DET_IDM_189:0, DET_IDM_190:0, DET_IDM_191:0, DET_IDM_192:0, DET_MH_CRC16_189_192:0, DET_MH_CYCLE_COUNTER_189_192:0, DET_MH_SCAN_INDEX_4LSB_189_192:0, DET_MTD_189:0, DET_MTD_190:0, DET_MTD_191:0, DET_MTD_192:0, DET_PROB_1STAZHYPO_189:0, DET_PROB_1STAZHYPO_190:0, DET_PROB_1STAZHYPO_191:0, DET_PROB_1STAZHYPO_192:0, DET_RANGE_189:0, DET_RANGE_190:0, DET_RANGE_191:0, DET_RANGE_192:0, DET_RANGE_ERR_189:0, DET_RANGE_ERR_190:0, DET_RANGE_ERR_191:0, DET_RANGE_ERR_192:0, DET_RANGE_VELOCITY_189:16384, DET_RANGE_VELOCITY_190:16384, DET_RANGE_VELOCITY_191:16384, DET_RANGE_VELOCITY_192:16384, DET_RANGE_VELOCITY_ERR_189:0, DET_RANGE_VELOCITY_ERR_190:0, DET_RANGE_VELOCITY_ERR_191:0, DET_RANGE_VELOCITY_ERR_192:0, DET_RCS_189:128, DET_RCS_190:128, DET_RCS_191:128, DET_RCS_192:128, DET_SNR_189:0, DET_SNR_190:0, DET_SNR_191:0, DET_SNR_192:0, DET_SUPER_RES_TARGET_189:0, DET_SUPER_RES_TARGET_190:0, DET_SUPER_RES_TARGET_191:0, DET_SUPER_RES_TARGET_192:0]}, provided-interface=Pi_SG_Detections_189_192_AL
      Pp_SG_Detections_193_196_AL: nonqueued-sender-com-spec{data-element=Vdp_SG_Detections_193_196_AL, init-value=fields=[DET_AZIMUTH_193:0, DET_AZIMUTH_194:0, DET_AZIMUTH_195:0, DET_AZIMUTH_196:0, DET_AZIMUTH_ERR_193:0, DET_AZIMUTH_ERR_194:0, DET_AZIMUTH_ERR_195:0, DET_AZIMUTH_ERR_196:0, DET_BELOW_RAIN_THOLD_193:0, DET_BELOW_RAIN_THOLD_194:0, DET_BELOW_RAIN_THOLD_195:0, DET_BELOW_RAIN_THOLD_196:0, DET_BI_STATIC_FLAG_193:0, DET_BI_STATIC_FLAG_194:0, DET_BI_STATIC_FLAG_195:0, DET_BI_STATIC_FLAG_196:0, DET_CONFD_AZIMUTH_193:0, DET_CONFD_AZIMUTH_194:0, DET_CONFD_AZIMUTH_195:0, DET_CONFD_AZIMUTH_196:0, DET_CONFD_ELEVATION_193:0, DET_CONFD_ELEVATION_194:0, DET_CONFD_ELEVATION_195:0, DET_CONFD_ELEVATION_196:0, DET_ELEVATION_193:0, DET_ELEVATION_194:0, DET_ELEVATION_195:0, DET_ELEVATION_196:0, DET_ELEVATION_ERR_193:0, DET_ELEVATION_ERR_194:0, DET_ELEVATION_ERR_195:0, DET_ELEVATION_ERR_196:0, DET_EXISTENCE_PROB_193:0, DET_EXISTENCE_PROB_194:0, DET_EXISTENCE_PROB_195:0, DET_EXISTENCE_PROB_196:0, DET_HVC_FLAG_193:0, DET_HVC_FLAG_194:0, DET_HVC_FLAG_195:0, DET_HVC_FLAG_196:0, DET_IDM_193:0, DET_IDM_194:0, DET_IDM_195:0, DET_IDM_196:0, DET_MH_CRC16_193_196:0, DET_MH_CYCLE_COUNTER_193_196:0, DET_MH_SCAN_INDEX_4LSB_193_196:0, DET_MTD_193:0, DET_MTD_194:0, DET_MTD_195:0, DET_MTD_196:0, DET_PROB_1STAZHYPO_193:0, DET_PROB_1STAZHYPO_194:0, DET_PROB_1STAZHYPO_195:0, DET_PROB_1STAZHYPO_196:0, DET_RANGE_193:0, DET_RANGE_194:0, DET_RANGE_195:0, DET_RANGE_196:0, DET_RANGE_ERR_193:0, DET_RANGE_ERR_194:0, DET_RANGE_ERR_195:0, DET_RANGE_ERR_196:0, DET_RANGE_VELOCITY_193:16384, DET_RANGE_VELOCITY_194:16384, DET_RANGE_VELOCITY_195:16384, DET_RANGE_VELOCITY_196:16384, DET_RANGE_VELOCITY_ERR_193:0, DET_RANGE_VELOCITY_ERR_194:0, DET_RANGE_VELOCITY_ERR_195:0, DET_RANGE_VELOCITY_ERR_196:0, DET_RCS_193:128, DET_RCS_194:128, DET_RCS_195:128, DET_RCS_196:128, DET_SNR_193:0, DET_SNR_194:0, DET_SNR_195:0, DET_SNR_196:0, DET_SUPER_RES_TARGET_193:0, DET_SUPER_RES_TARGET_194:0, DET_SUPER_RES_TARGET_195:0, DET_SUPER_RES_TARGET_196:0]}, provided-interface=Pi_SG_Detections_193_196_AL
      Pp_SG_Detections_197_200_AL: nonqueued-sender-com-spec{data-element=Vdp_SG_Detections_197_200_AL, init-value=fields=[DET_AZIMUTH_197:0, DET_AZIMUTH_198:0, DET_AZIMUTH_199:0, DET_AZIMUTH_200:0, DET_AZIMUTH_ERR_197:0, DET_AZIMUTH_ERR_198:0, DET_AZIMUTH_ERR_199:0, DET_AZIMUTH_ERR_200:0, DET_BELOW_RAIN_THOLD_197:0, DET_BELOW_RAIN_THOLD_198:0, DET_BELOW_RAIN_THOLD_199:0, DET_BELOW_RAIN_THOLD_200:0, DET_BI_STATIC_FLAG_197:0, DET_BI_STATIC_FLAG_198:0, DET_BI_STATIC_FLAG_199:0, DET_BI_STATIC_FLAG_200:0, DET_CONFD_AZIMUTH_197:0, DET_CONFD_AZIMUTH_198:0, DET_CONFD_AZIMUTH_199:0, DET_CONFD_AZIMUTH_200:0, DET_CONFD_ELEVATION_197:0, DET_CONFD_ELEVATION_198:0, DET_CONFD_ELEVATION_199:0, DET_CONFD_ELEVATION_200:0, DET_ELEVATION_197:0, DET_ELEVATION_198:0, DET_ELEVATION_199:0, DET_ELEVATION_200:0, DET_ELEVATION_ERR_197:0, DET_ELEVATION_ERR_198:0, DET_ELEVATION_ERR_199:0, DET_ELEVATION_ERR_200:0, DET_EXISTENCE_PROB_197:0, DET_EXISTENCE_PROB_198:0, DET_EXISTENCE_PROB_199:0, DET_EXISTENCE_PROB_200:0, DET_HVC_FLAG_197:0, DET_HVC_FLAG_198:0, DET_HVC_FLAG_199:0, DET_HVC_FLAG_200:0, DET_IDM_197:0, DET_IDM_198:0, DET_IDM_199:0, DET_IDM_200:0, DET_MH_CRC16_197_200:0, DET_MH_CYCLE_COUNTER_197_200:0, DET_MH_SCAN_INDEX_4LSB_197_200:0, DET_MTD_197:0, DET_MTD_198:0, DET_MTD_199:0, DET_MTD_200:0, DET_PROB_1STAZHYPO_197:0, DET_PROB_1STAZHYPO_198:0, DET_PROB_1STAZHYPO_199:0, DET_PROB_1STAZHYPO_200:0, DET_RANGE_197:0, DET_RANGE_198:0, DET_RANGE_199:0, DET_RANGE_200:0, DET_RANGE_ERR_197:0, DET_RANGE_ERR_198:0, DET_RANGE_ERR_199:0, DET_RANGE_ERR_200:0, DET_RANGE_VELOCITY_197:16384, DET_RANGE_VELOCITY_198:16384, DET_RANGE_VELOCITY_199:16384, DET_RANGE_VELOCITY_200:16384, DET_RANGE_VELOCITY_ERR_197:0, DET_RANGE_VELOCITY_ERR_198:0, DET_RANGE_VELOCITY_ERR_199:0, DET_RANGE_VELOCITY_ERR_200:0, DET_RCS_197:128, DET_RCS_198:128, DET_RCS_199:128, DET_RCS_200:128, DET_SNR_197:0, DET_SNR_198:0, DET_SNR_199:0, DET_SNR_200:0, DET_SUPER_RES_TARGET_197:0, DET_SUPER_RES_TARGET_198:0, DET_SUPER_RES_TARGET_199:0, DET_SUPER_RES_TARGET_200:0]}, provided-interface=Pi_SG_Detections_197_200_AL
      Pp_SG_Detections_201_204_AL: nonqueued-sender-com-spec{data-element=Vdp_SG_Detections_201_204_AL, init-value=fields=[DET_AZIMUTH_201:0, DET_AZIMUTH_202:0, DET_AZIMUTH_203:0, DET_AZIMUTH_204:0, DET_AZIMUTH_ERR_201:0, DET_AZIMUTH_ERR_202:0, DET_AZIMUTH_ERR_203:0, DET_AZIMUTH_ERR_204:0, DET_BELOW_RAIN_THOLD_201:0, DET_BELOW_RAIN_THOLD_202:0, DET_BELOW_RAIN_THOLD_203:0, DET_BELOW_RAIN_THOLD_204:0, DET_BI_STATIC_FLAG_201:0, DET_BI_STATIC_FLAG_202:0, DET_BI_STATIC_FLAG_203:0, DET_BI_STATIC_FLAG_204:0, DET_CONFD_AZIMUTH_201:0, DET_CONFD_AZIMUTH_202:0, DET_CONFD_AZIMUTH_203:0, DET_CONFD_AZIMUTH_204:0, DET_CONFD_ELEVATION_201:0, DET_CONFD_ELEVATION_202:0, DET_CONFD_ELEVATION_203:0, DET_CONFD_ELEVATION_204:0, DET_ELEVATION_201:0, DET_ELEVATION_202:0, DET_ELEVATION_203:0, DET_ELEVATION_204:0, DET_ELEVATION_ERR_201:0, DET_ELEVATION_ERR_202:0, DET_ELEVATION_ERR_203:0, DET_ELEVATION_ERR_204:0, DET_EXISTENCE_PROB_201:0, DET_EXISTENCE_PROB_202:0, DET_EXISTENCE_PROB_203:0, DET_EXISTENCE_PROB_204:0, DET_HVC_FLAG_201:0, DET_HVC_FLAG_202:0, DET_HVC_FLAG_203:0, DET_HVC_FLAG_204:0, DET_IDM_201:0, DET_IDM_202:0, DET_IDM_203:0, DET_IDM_204:0, DET_MH_CRC16_201_204:0, DET_MH_CYCLE_COUNTER_201_204:0, DET_MH_SCAN_INDEX_4LSB_201_204:0, DET_MTD_201:0, DET_MTD_202:0, DET_MTD_203:0, DET_MTD_204:0, DET_PROB_1STAZHYPO_201:0, DET_PROB_1STAZHYPO_202:0, DET_PROB_1STAZHYPO_203:0, DET_PROB_1STAZHYPO_204:0, DET_RANGE_201:0, DET_RANGE_202:0, DET_RANGE_203:0, DET_RANGE_204:0, DET_RANGE_ERR_201:0, DET_RANGE_ERR_202:0, DET_RANGE_ERR_203:0, DET_RANGE_ERR_204:0, DET_RANGE_VELOCITY_201:16384, DET_RANGE_VELOCITY_202:16384, DET_RANGE_VELOCITY_203:16384, DET_RANGE_VELOCITY_204:16384, DET_RANGE_VELOCITY_ERR_201:0, DET_RANGE_VELOCITY_ERR_202:0, DET_RANGE_VELOCITY_ERR_203:0, DET_RANGE_VELOCITY_ERR_204:0, DET_RCS_201:128, DET_RCS_202:128, DET_RCS_203:128, DET_RCS_204:128, DET_SNR_201:0, DET_SNR_202:0, DET_SNR_203:0, DET_SNR_204:0, DET_SUPER_RES_TARGET_201:0, DET_SUPER_RES_TARGET_202:0, DET_SUPER_RES_TARGET_203:0, DET_SUPER_RES_TARGET_204:0]}, provided-interface=Pi_SG_Detections_201_204_AL
      Pp_SG_Detections_205_208_AL: nonqueued-sender-com-spec{data-element=Vdp_SG_Detections_205_208_AL, init-value=fields=[DET_AZIMUTH_205:0, DET_AZIMUTH_206:0, DET_AZIMUTH_207:0, DET_AZIMUTH_208:0, DET_AZIMUTH_ERR_205:0, DET_AZIMUTH_ERR_206:0, DET_AZIMUTH_ERR_207:0, DET_AZIMUTH_ERR_208:0, DET_BELOW_RAIN_THOLD_205:0, DET_BELOW_RAIN_THOLD_206:0, DET_BELOW_RAIN_THOLD_207:0, DET_BELOW_RAIN_THOLD_208:0, DET_BI_STATIC_FLAG_205:0, DET_BI_STATIC_FLAG_206:0, DET_BI_STATIC_FLAG_207:0, DET_BI_STATIC_FLAG_208:0, DET_CONFD_AZIMUTH_205:0, DET_CONFD_AZIMUTH_206:0, DET_CONFD_AZIMUTH_207:0, DET_CONFD_AZIMUTH_208:0, DET_CONFD_ELEVATION_205:0, DET_CONFD_ELEVATION_206:0, DET_CONFD_ELEVATION_207:0, DET_CONFD_ELEVATION_208:0, DET_ELEVATION_205:0, DET_ELEVATION_206:0, DET_ELEVATION_207:0, DET_ELEVATION_208:0, DET_ELEVATION_ERR_205:0, DET_ELEVATION_ERR_206:0, DET_ELEVATION_ERR_207:0, DET_ELEVATION_ERR_208:0, DET_EXISTENCE_PROB_205:0, DET_EXISTENCE_PROB_206:0, DET_EXISTENCE_PROB_207:0, DET_EXISTENCE_PROB_208:0, DET_HVC_FLAG_205:0, DET_HVC_FLAG_206:0, DET_HVC_FLAG_207:0, DET_HVC_FLAG_208:0, DET_IDM_205:0, DET_IDM_206:0, DET_IDM_207:0, DET_IDM_208:0, DET_MH_CRC16_205_208:0, DET_MH_CYCLE_COUNTER_205_208:0, DET_MH_SCAN_INDEX_4LSB_205_208:0, DET_MTD_205:0, DET_MTD_206:0, DET_MTD_207:0, DET_MTD_208:0, DET_PROB_1STAZHYPO_205:0, DET_PROB_1STAZHYPO_206:0, DET_PROB_1STAZHYPO_207:0, DET_PROB_1STAZHYPO_208:0, DET_RANGE_205:0, DET_RANGE_206:0, DET_RANGE_207:0, DET_RANGE_208:0, DET_RANGE_ERR_205:0, DET_RANGE_ERR_206:0, DET_RANGE_ERR_207:0, DET_RANGE_ERR_208:0, DET_RANGE_VELOCITY_205:16384, DET_RANGE_VELOCITY_206:16384, DET_RANGE_VELOCITY_207:16384, DET_RANGE_VELOCITY_208:16384, DET_RANGE_VELOCITY_ERR_205:0, DET_RANGE_VELOCITY_ERR_206:0, DET_RANGE_VELOCITY_ERR_207:0, DET_RANGE_VELOCITY_ERR_208:0, DET_RCS_205:128, DET_RCS_206:128, DET_RCS_207:128, DET_RCS_208:128, DET_SNR_205:0, DET_SNR_206:0, DET_SNR_207:0, DET_SNR_208:0, DET_SUPER_RES_TARGET_205:0, DET_SUPER_RES_TARGET_206:0, DET_SUPER_RES_TARGET_207:0, DET_SUPER_RES_TARGET_208:0]}, provided-interface=Pi_SG_Detections_205_208_AL
      Pp_SG_Detections_209_212_AL: nonqueued-sender-com-spec{data-element=Vdp_SG_Detections_209_212_AL, init-value=fields=[DET_AZIMUTH_209:0, DET_AZIMUTH_210:0, DET_AZIMUTH_211:0, DET_AZIMUTH_212:0, DET_AZIMUTH_ERR_209:0, DET_AZIMUTH_ERR_210:0, DET_AZIMUTH_ERR_211:0, DET_AZIMUTH_ERR_212:0, DET_BELOW_RAIN_THOLD_209:0, DET_BELOW_RAIN_THOLD_210:0, DET_BELOW_RAIN_THOLD_211:0, DET_BELOW_RAIN_THOLD_212:0, DET_BI_STATIC_FLAG_209:0, DET_BI_STATIC_FLAG_210:0, DET_BI_STATIC_FLAG_211:0, DET_BI_STATIC_FLAG_212:0, DET_CONFD_AZIMUTH_209:0, DET_CONFD_AZIMUTH_210:0, DET_CONFD_AZIMUTH_211:0, DET_CONFD_AZIMUTH_212:0, DET_CONFD_ELEVATION_209:0, DET_CONFD_ELEVATION_210:0, DET_CONFD_ELEVATION_211:0, DET_CONFD_ELEVATION_212:0, DET_ELEVATION_209:0, DET_ELEVATION_210:0, DET_ELEVATION_211:0, DET_ELEVATION_212:0, DET_ELEVATION_ERR_209:0, DET_ELEVATION_ERR_210:0, DET_ELEVATION_ERR_211:0, DET_ELEVATION_ERR_212:0, DET_EXISTENCE_PROB_209:0, DET_EXISTENCE_PROB_210:0, DET_EXISTENCE_PROB_211:0, DET_EXISTENCE_PROB_212:0, DET_HVC_FLAG_209:0, DET_HVC_FLAG_210:0, DET_HVC_FLAG_211:0, DET_HVC_FLAG_212:0, DET_IDM_209:0, DET_IDM_210:0, DET_IDM_211:0, DET_IDM_212:0, DET_MH_CRC16_209_212:0, DET_MH_CYCLE_COUNTER_209_212:0, DET_MH_SCAN_INDEX_4LSB_209_212:0, DET_MTD_209:0, DET_MTD_210:0, DET_MTD_211:0, DET_MTD_212:0, DET_PROB_1STAZHYPO_209:0, DET_PROB_1STAZHYPO_210:0, DET_PROB_1STAZHYPO_211:0, DET_PROB_1STAZHYPO_212:0, DET_RANGE_209:0, DET_RANGE_210:0, DET_RANGE_211:0, DET_RANGE_212:0, DET_RANGE_ERR_209:0, DET_RANGE_ERR_210:0, DET_RANGE_ERR_211:0, DET_RANGE_ERR_212:0, DET_RANGE_VELOCITY_209:16384, DET_RANGE_VELOCITY_210:16384, DET_RANGE_VELOCITY_211:16384, DET_RANGE_VELOCITY_212:16384, DET_RANGE_VELOCITY_ERR_209:0, DET_RANGE_VELOCITY_ERR_210:0, DET_RANGE_VELOCITY_ERR_211:0, DET_RANGE_VELOCITY_ERR_212:0, DET_RCS_209:128, DET_RCS_210:128, DET_RCS_211:128, DET_RCS_212:128, DET_SNR_209:0, DET_SNR_210:0, DET_SNR_211:0, DET_SNR_212:0, DET_SUPER_RES_TARGET_209:0, DET_SUPER_RES_TARGET_210:0, DET_SUPER_RES_TARGET_211:0, DET_SUPER_RES_TARGET_212:0]}, provided-interface=Pi_SG_Detections_209_212_AL
      Pp_SG_Detections_213_216_AL: nonqueued-sender-com-spec{data-element=Vdp_SG_Detections_213_216_AL, init-value=fields=[DET_AZIMUTH_213:0, DET_AZIMUTH_214:0, DET_AZIMUTH_215:0, DET_AZIMUTH_216:0, DET_AZIMUTH_ERR_213:0, DET_AZIMUTH_ERR_214:0, DET_AZIMUTH_ERR_215:0, DET_AZIMUTH_ERR_216:0, DET_BELOW_RAIN_THOLD_213:0, DET_BELOW_RAIN_THOLD_214:0, DET_BELOW_RAIN_THOLD_215:0, DET_BELOW_RAIN_THOLD_216:0, DET_BI_STATIC_FLAG_213:0, DET_BI_STATIC_FLAG_214:0, DET_BI_STATIC_FLAG_215:0, DET_BI_STATIC_FLAG_216:0, DET_CONFD_AZIMUTH_213:0, DET_CONFD_AZIMUTH_214:0, DET_CONFD_AZIMUTH_215:0, DET_CONFD_AZIMUTH_216:0, DET_CONFD_ELEVATION_213:0, DET_CONFD_ELEVATION_214:0, DET_CONFD_ELEVATION_215:0, DET_CONFD_ELEVATION_216:0, DET_ELEVATION_213:0, DET_ELEVATION_214:0, DET_ELEVATION_215:0, DET_ELEVATION_216:0, DET_ELEVATION_ERR_213:0, DET_ELEVATION_ERR_214:0, DET_ELEVATION_ERR_215:0, DET_ELEVATION_ERR_216:0, DET_EXISTENCE_PROB_213:0, DET_EXISTENCE_PROB_214:0, DET_EXISTENCE_PROB_215:0, DET_EXISTENCE_PROB_216:0, DET_HVC_FLAG_213:0, DET_HVC_FLAG_214:0, DET_HVC_FLAG_215:0, DET_HVC_FLAG_216:0, DET_IDM_213:0, DET_IDM_214:0, DET_IDM_215:0, DET_IDM_216:0, DET_MH_CRC16_213_216:0, DET_MH_CYCLE_COUNTER_213_216:0, DET_MH_SCAN_INDEX_4LSB_213_216:0, DET_MTD_213:0, DET_MTD_214:0, DET_MTD_215:0, DET_MTD_216:0, DET_PROB_1STAZHYPO_213:0, DET_PROB_1STAZHYPO_214:0, DET_PROB_1STAZHYPO_215:0, DET_PROB_1STAZHYPO_216:0, DET_RANGE_213:0, DET_RANGE_214:0, DET_RANGE_215:0, DET_RANGE_216:0, DET_RANGE_ERR_213:0, DET_RANGE_ERR_214:0, DET_RANGE_ERR_215:0, DET_RANGE_ERR_216:0, DET_RANGE_VELOCITY_213:16384, DET_RANGE_VELOCITY_214:16384, DET_RANGE_VELOCITY_215:16384, DET_RANGE_VELOCITY_216:16384, DET_RANGE_VELOCITY_ERR_213:0, DET_RANGE_VELOCITY_ERR_214:0, DET_RANGE_VELOCITY_ERR_215:0, DET_RANGE_VELOCITY_ERR_216:0, DET_RCS_213:128, DET_RCS_214:128, DET_RCS_215:128, DET_RCS_216:128, DET_SNR_213:0, DET_SNR_214:0, DET_SNR_215:0, DET_SNR_216:0, DET_SUPER_RES_TARGET_213:0, DET_SUPER_RES_TARGET_214:0, DET_SUPER_RES_TARGET_215:0, DET_SUPER_RES_TARGET_216:0]}, provided-interface=Pi_SG_Detections_213_216_AL
      Pp_SG_Detections_217_220_AL: nonqueued-sender-com-spec{data-element=Vdp_SG_Detections_217_220_AL, init-value=fields=[DET_AZIMUTH_217:0, DET_AZIMUTH_218:0, DET_AZIMUTH_219:0, DET_AZIMUTH_220:0, DET_AZIMUTH_ERR_217:0, DET_AZIMUTH_ERR_218:0, DET_AZIMUTH_ERR_219:0, DET_AZIMUTH_ERR_220:0, DET_BELOW_RAIN_THOLD_217:0, DET_BELOW_RAIN_THOLD_218:0, DET_BELOW_RAIN_THOLD_219:0, DET_BELOW_RAIN_THOLD_220:0, DET_BI_STATIC_FLAG_217:0, DET_BI_STATIC_FLAG_218:0, DET_BI_STATIC_FLAG_219:0, DET_BI_STATIC_FLAG_220:0, DET_CONFD_AZIMUTH_217:0, DET_CONFD_AZIMUTH_218:0, DET_CONFD_AZIMUTH_219:0, DET_CONFD_AZIMUTH_220:0, DET_CONFD_ELEVATION_217:0, DET_CONFD_ELEVATION_218:0, DET_CONFD_ELEVATION_219:0, DET_CONFD_ELEVATION_220:0, DET_ELEVATION_217:0, DET_ELEVATION_218:0, DET_ELEVATION_219:0, DET_ELEVATION_220:0, DET_ELEVATION_ERR_217:0, DET_ELEVATION_ERR_218:0, DET_ELEVATION_ERR_219:0, DET_ELEVATION_ERR_220:0, DET_EXISTENCE_PROB_217:0, DET_EXISTENCE_PROB_218:0, DET_EXISTENCE_PROB_219:0, DET_EXISTENCE_PROB_220:0, DET_HVC_FLAG_217:0, DET_HVC_FLAG_218:0, DET_HVC_FLAG_219:0, DET_HVC_FLAG_220:0, DET_IDM_217:0, DET_IDM_218:0, DET_IDM_219:0, DET_IDM_220:0, DET_MH_CRC16_217_220:0, DET_MH_CYCLE_COUNTER_217_220:0, DET_MH_SCAN_INDEX_4LSB_217_220:0, DET_MTD_217:0, DET_MTD_218:0, DET_MTD_219:0, DET_MTD_220:0, DET_PROB_1STAZHYPO_217:0, DET_PROB_1STAZHYPO_218:0, DET_PROB_1STAZHYPO_219:0, DET_PROB_1STAZHYPO_220:0, DET_RANGE_217:0, DET_RANGE_218:0, DET_RANGE_219:0, DET_RANGE_220:0, DET_RANGE_ERR_217:0, DET_RANGE_ERR_218:0, DET_RANGE_ERR_219:0, DET_RANGE_ERR_220:0, DET_RANGE_VELOCITY_217:16384, DET_RANGE_VELOCITY_218:16384, DET_RANGE_VELOCITY_219:16384, DET_RANGE_VELOCITY_220:16384, DET_RANGE_VELOCITY_ERR_217:0, DET_RANGE_VELOCITY_ERR_218:0, DET_RANGE_VELOCITY_ERR_219:0, DET_RANGE_VELOCITY_ERR_220:0, DET_RCS_217:128, DET_RCS_218:128, DET_RCS_219:128, DET_RCS_220:128, DET_SNR_217:0, DET_SNR_218:0, DET_SNR_219:0, DET_SNR_220:0, DET_SUPER_RES_TARGET_217:0, DET_SUPER_RES_TARGET_218:0, DET_SUPER_RES_TARGET_219:0, DET_SUPER_RES_TARGET_220:0]}, provided-interface=Pi_SG_Detections_217_220_AL
      Pp_SG_Detections_221_224_AL: nonqueued-sender-com-spec{data-element=Vdp_SG_Detections_221_224_AL, init-value=fields=[DET_AZIMUTH_221:0, DET_AZIMUTH_222:0, DET_AZIMUTH_223:0, DET_AZIMUTH_224:0, DET_AZIMUTH_ERR_221:0, DET_AZIMUTH_ERR_222:0, DET_AZIMUTH_ERR_223:0, DET_AZIMUTH_ERR_224:0, DET_BELOW_RAIN_THOLD_221:0, DET_BELOW_RAIN_THOLD_222:0, DET_BELOW_RAIN_THOLD_223:0, DET_BELOW_RAIN_THOLD_224:0, DET_BI_STATIC_FLAG_221:0, DET_BI_STATIC_FLAG_222:0, DET_BI_STATIC_FLAG_223:0, DET_BI_STATIC_FLAG_224:0, DET_CONFD_AZIMUTH_221:0, DET_CONFD_AZIMUTH_222:0, DET_CONFD_AZIMUTH_223:0, DET_CONFD_AZIMUTH_224:0, DET_CONFD_ELEVATION_221:0, DET_CONFD_ELEVATION_222:0, DET_CONFD_ELEVATION_223:0, DET_CONFD_ELEVATION_224:0, DET_ELEVATION_221:0, DET_ELEVATION_222:0, DET_ELEVATION_223:0, DET_ELEVATION_224:0, DET_ELEVATION_ERR_221:0, DET_ELEVATION_ERR_222:0, DET_ELEVATION_ERR_223:0, DET_ELEVATION_ERR_224:0, DET_EXISTENCE_PROB_221:0, DET_EXISTENCE_PROB_222:0, DET_EXISTENCE_PROB_223:0, DET_EXISTENCE_PROB_224:0, DET_HVC_FLAG_221:0, DET_HVC_FLAG_222:0, DET_HVC_FLAG_223:0, DET_HVC_FLAG_224:0, DET_IDM_221:0, DET_IDM_222:0, DET_IDM_223:0, DET_IDM_224:0, DET_MH_CRC16_221_224:0, DET_MH_CYCLE_COUNTER_221_224:0, DET_MH_SCAN_INDEX_4LSB_221_224:0, DET_MTD_221:0, DET_MTD_222:0, DET_MTD_223:0, DET_MTD_224:0, DET_PROB_1STAZHYPO_221:0, DET_PROB_1STAZHYPO_222:0, DET_PROB_1STAZHYPO_223:0, DET_PROB_1STAZHYPO_224:0, DET_RANGE_221:0, DET_RANGE_222:0, DET_RANGE_223:0, DET_RANGE_224:0, DET_RANGE_ERR_221:0, DET_RANGE_ERR_222:0, DET_RANGE_ERR_223:0, DET_RANGE_ERR_224:0, DET_RANGE_VELOCITY_221:16384, DET_RANGE_VELOCITY_222:16384, DET_RANGE_VELOCITY_223:16384, DET_RANGE_VELOCITY_224:16384, DET_RANGE_VELOCITY_ERR_221:0, DET_RANGE_VELOCITY_ERR_222:0, DET_RANGE_VELOCITY_ERR_223:0, DET_RANGE_VELOCITY_ERR_224:0, DET_RCS_221:128, DET_RCS_222:128, DET_RCS_223:128, DET_RCS_224:128, DET_SNR_221:0, DET_SNR_222:0, DET_SNR_223:0, DET_SNR_224:0, DET_SUPER_RES_TARGET_221:0, DET_SUPER_RES_TARGET_222:0, DET_SUPER_RES_TARGET_223:0, DET_SUPER_RES_TARGET_224:0]}, provided-interface=Pi_SG_Detections_221_224_AL
      Pp_SG_Detections_225_228_AL: nonqueued-sender-com-spec{data-element=Vdp_SG_Detections_225_228_AL, init-value=fields=[DET_AZIMUTH_225:0, DET_AZIMUTH_226:0, DET_AZIMUTH_227:0, DET_AZIMUTH_228:0, DET_AZIMUTH_ERR_225:0, DET_AZIMUTH_ERR_226:0, DET_AZIMUTH_ERR_227:0, DET_AZIMUTH_ERR_228:0, DET_BELOW_RAIN_THOLD_225:0, DET_BELOW_RAIN_THOLD_226:0, DET_BELOW_RAIN_THOLD_227:0, DET_BELOW_RAIN_THOLD_228:0, DET_BI_STATIC_FLAG_225:0, DET_BI_STATIC_FLAG_226:0, DET_BI_STATIC_FLAG_227:0, DET_BI_STATIC_FLAG_228:0, DET_CONFD_AZIMUTH_225:0, DET_CONFD_AZIMUTH_226:0, DET_CONFD_AZIMUTH_227:0, DET_CONFD_AZIMUTH_228:0, DET_CONFD_ELEVATION_225:0, DET_CONFD_ELEVATION_226:0, DET_CONFD_ELEVATION_227:0, DET_CONFD_ELEVATION_228:0, DET_ELEVATION_225:0, DET_ELEVATION_226:0, DET_ELEVATION_227:0, DET_ELEVATION_228:0, DET_ELEVATION_ERR_225:0, DET_ELEVATION_ERR_226:0, DET_ELEVATION_ERR_227:0, DET_ELEVATION_ERR_228:0, DET_EXISTENCE_PROB_225:0, DET_EXISTENCE_PROB_226:0, DET_EXISTENCE_PROB_227:0, DET_EXISTENCE_PROB_228:0, DET_HVC_FLAG_225:0, DET_HVC_FLAG_226:0, DET_HVC_FLAG_227:0, DET_HVC_FLAG_228:0, DET_IDM_225:0, DET_IDM_226:0, DET_IDM_227:0, DET_IDM_228:0, DET_MH_CRC16_225_228:0, DET_MH_CYCLE_COUNTER_225_228:0, DET_MH_SCAN_INDEX_4LSB_225_228:0, DET_MTD_225:0, DET_MTD_226:0, DET_MTD_227:0, DET_MTD_228:0, DET_PROB_1STAZHYPO_225:0, DET_PROB_1STAZHYPO_226:0, DET_PROB_1STAZHYPO_227:0, DET_PROB_1STAZHYPO_228:0, DET_RANGE_225:0, DET_RANGE_226:0, DET_RANGE_227:0, DET_RANGE_228:0, DET_RANGE_ERR_225:0, DET_RANGE_ERR_226:0, DET_RANGE_ERR_227:0, DET_RANGE_ERR_228:0, DET_RANGE_VELOCITY_225:16384, DET_RANGE_VELOCITY_226:16384, DET_RANGE_VELOCITY_227:16384, DET_RANGE_VELOCITY_228:16384, DET_RANGE_VELOCITY_ERR_225:0, DET_RANGE_VELOCITY_ERR_226:0, DET_RANGE_VELOCITY_ERR_227:0, DET_RANGE_VELOCITY_ERR_228:0, DET_RCS_225:128, DET_RCS_226:128, DET_RCS_227:128, DET_RCS_228:128, DET_SNR_225:0, DET_SNR_226:0, DET_SNR_227:0, DET_SNR_228:0, DET_SUPER_RES_TARGET_225:0, DET_SUPER_RES_TARGET_226:0, DET_SUPER_RES_TARGET_227:0, DET_SUPER_RES_TARGET_228:0]}, provided-interface=Pi_SG_Detections_225_228_AL
      Pp_SG_Detections_229_232_AL: nonqueued-sender-com-spec{data-element=Vdp_SG_Detections_229_232_AL, init-value=fields=[DET_AZIMUTH_229:0, DET_AZIMUTH_230:0, DET_AZIMUTH_231:0, DET_AZIMUTH_232:0, DET_AZIMUTH_ERR_229:0, DET_AZIMUTH_ERR_230:0, DET_AZIMUTH_ERR_231:0, DET_AZIMUTH_ERR_232:0, DET_BELOW_RAIN_THOLD_229:0, DET_BELOW_RAIN_THOLD_230:0, DET_BELOW_RAIN_THOLD_231:0, DET_BELOW_RAIN_THOLD_232:0, DET_BI_STATIC_FLAG_229:0, DET_BI_STATIC_FLAG_230:0, DET_BI_STATIC_FLAG_231:0, DET_BI_STATIC_FLAG_232:0, DET_CONFD_AZIMUTH_229:0, DET_CONFD_AZIMUTH_230:0, DET_CONFD_AZIMUTH_231:0, DET_CONFD_AZIMUTH_232:0, DET_CONFD_ELEVATION_229:0, DET_CONFD_ELEVATION_230:0, DET_CONFD_ELEVATION_231:0, DET_CONFD_ELEVATION_232:0, DET_ELEVATION_229:0, DET_ELEVATION_230:0, DET_ELEVATION_231:0, DET_ELEVATION_232:0, DET_ELEVATION_ERR_229:0, DET_ELEVATION_ERR_230:0, DET_ELEVATION_ERR_231:0, DET_ELEVATION_ERR_232:0, DET_EXISTENCE_PROB_229:0, DET_EXISTENCE_PROB_230:0, DET_EXISTENCE_PROB_231:0, DET_EXISTENCE_PROB_232:0, DET_HVC_FLAG_229:0, DET_HVC_FLAG_230:0, DET_HVC_FLAG_231:0, DET_HVC_FLAG_232:0, DET_IDM_229:0, DET_IDM_230:0, DET_IDM_231:0, DET_IDM_232:0, DET_MH_CRC16_229_232:0, DET_MH_CYCLE_COUNTER_229_232:0, DET_MH_SCAN_INDEX_4LSB_229_232:0, DET_MTD_229:0, DET_MTD_230:0, DET_MTD_231:0, DET_MTD_232:0, DET_PROB_1STAZHYPO_229:0, DET_PROB_1STAZHYPO_230:0, DET_PROB_1STAZHYPO_231:0, DET_PROB_1STAZHYPO_232:0, DET_RANGE_229:0, DET_RANGE_230:0, DET_RANGE_231:0, DET_RANGE_232:0, DET_RANGE_ERR_229:0, DET_RANGE_ERR_230:0, DET_RANGE_ERR_231:0, DET_RANGE_ERR_232:0, DET_RANGE_VELOCITY_229:16384, DET_RANGE_VELOCITY_230:16384, DET_RANGE_VELOCITY_231:16384, DET_RANGE_VELOCITY_232:16384, DET_RANGE_VELOCITY_ERR_229:0, DET_RANGE_VELOCITY_ERR_230:0, DET_RANGE_VELOCITY_ERR_231:0, DET_RANGE_VELOCITY_ERR_232:0, DET_RCS_229:128, DET_RCS_230:128, DET_RCS_231:128, DET_RCS_232:128, DET_SNR_229:0, DET_SNR_230:0, DET_SNR_231:0, DET_SNR_232:0, DET_SUPER_RES_TARGET_229:0, DET_SUPER_RES_TARGET_230:0, DET_SUPER_RES_TARGET_231:0, DET_SUPER_RES_TARGET_232:0]}, provided-interface=Pi_SG_Detections_229_232_AL
      Pp_SG_Detections_233_236_AL: nonqueued-sender-com-spec{data-element=Vdp_SG_Detections_233_236_AL, init-value=fields=[DET_AZIMUTH_233:0, DET_AZIMUTH_234:0, DET_AZIMUTH_235:0, DET_AZIMUTH_236:0, DET_AZIMUTH_ERR_233:0, DET_AZIMUTH_ERR_234:0, DET_AZIMUTH_ERR_235:0, DET_AZIMUTH_ERR_236:0, DET_BELOW_RAIN_THOLD_233:0, DET_BELOW_RAIN_THOLD_234:0, DET_BELOW_RAIN_THOLD_235:0, DET_BELOW_RAIN_THOLD_236:0, DET_BI_STATIC_FLAG_233:0, DET_BI_STATIC_FLAG_234:0, DET_BI_STATIC_FLAG_235:0, DET_BI_STATIC_FLAG_236:0, DET_CONFD_AZIMUTH_233:0, DET_CONFD_AZIMUTH_234:0, DET_CONFD_AZIMUTH_235:0, DET_CONFD_AZIMUTH_236:0, DET_CONFD_ELEVATION_233:0, DET_CONFD_ELEVATION_234:0, DET_CONFD_ELEVATION_235:0, DET_CONFD_ELEVATION_236:0, DET_ELEVATION_233:0, DET_ELEVATION_234:0, DET_ELEVATION_235:0, DET_ELEVATION_236:0, DET_ELEVATION_ERR_233:0, DET_ELEVATION_ERR_234:0, DET_ELEVATION_ERR_235:0, DET_ELEVATION_ERR_236:0, DET_EXISTENCE_PROB_233:0, DET_EXISTENCE_PROB_234:0, DET_EXISTENCE_PROB_235:0, DET_EXISTENCE_PROB_236:0, DET_HVC_FLAG_233:0, DET_HVC_FLAG_234:0, DET_HVC_FLAG_235:0, DET_HVC_FLAG_236:0, DET_IDM_233:0, DET_IDM_234:0, DET_IDM_235:0, DET_IDM_236:0, DET_MH_CRC16_233_236:0, DET_MH_CYCLE_COUNTER_233_236:0, DET_MH_SCAN_INDEX_4LSB_233_236:0, DET_MTD_233:0, DET_MTD_234:0, DET_MTD_235:0, DET_MTD_236:0, DET_PROB_1STAZHYPO_233:0, DET_PROB_1STAZHYPO_234:0, DET_PROB_1STAZHYPO_235:0, DET_PROB_1STAZHYPO_236:0, DET_RANGE_233:0, DET_RANGE_234:0, DET_RANGE_235:0, DET_RANGE_236:0, DET_RANGE_ERR_233:0, DET_RANGE_ERR_234:0, DET_RANGE_ERR_235:0, DET_RANGE_ERR_236:0, DET_RANGE_VELOCITY_233:16384, DET_RANGE_VELOCITY_234:16384, DET_RANGE_VELOCITY_235:16384, DET_RANGE_VELOCITY_236:16384, DET_RANGE_VELOCITY_ERR_233:0, DET_RANGE_VELOCITY_ERR_234:0, DET_RANGE_VELOCITY_ERR_235:0, DET_RANGE_VELOCITY_ERR_236:0, DET_RCS_233:128, DET_RCS_234:128, DET_RCS_235:128, DET_RCS_236:128, DET_SNR_233:0, DET_SNR_234:0, DET_SNR_235:0, DET_SNR_236:0, DET_SUPER_RES_TARGET_233:0, DET_SUPER_RES_TARGET_234:0, DET_SUPER_RES_TARGET_235:0, DET_SUPER_RES_TARGET_236:0]}, provided-interface=Pi_SG_Detections_233_236_AL
      Pp_SG_Detections_237_240_AL: nonqueued-sender-com-spec{data-element=Vdp_SG_Detections_237_240_AL, init-value=fields=[DET_AZIMUTH_237:0, DET_AZIMUTH_238:0, DET_AZIMUTH_239:0, DET_AZIMUTH_240:0, DET_AZIMUTH_ERR_237:0, DET_AZIMUTH_ERR_238:0, DET_AZIMUTH_ERR_239:0, DET_AZIMUTH_ERR_240:0, DET_BELOW_RAIN_THOLD_237:0, DET_BELOW_RAIN_THOLD_238:0, DET_BELOW_RAIN_THOLD_239:0, DET_BELOW_RAIN_THOLD_240:0, DET_BI_STATIC_FLAG_237:0, DET_BI_STATIC_FLAG_238:0, DET_BI_STATIC_FLAG_239:0, DET_BI_STATIC_FLAG_240:0, DET_CONFD_AZIMUTH_237:0, DET_CONFD_AZIMUTH_238:0, DET_CONFD_AZIMUTH_239:0, DET_CONFD_AZIMUTH_240:0, DET_CONFD_ELEVATION_237:0, DET_CONFD_ELEVATION_238:0, DET_CONFD_ELEVATION_239:0, DET_CONFD_ELEVATION_240:0, DET_ELEVATION_237:0, DET_ELEVATION_238:0, DET_ELEVATION_239:0, DET_ELEVATION_240:0, DET_ELEVATION_ERR_237:0, DET_ELEVATION_ERR_238:0, DET_ELEVATION_ERR_239:0, DET_ELEVATION_ERR_240:0, DET_EXISTENCE_PROB_237:0, DET_EXISTENCE_PROB_238:0, DET_EXISTENCE_PROB_239:0, DET_EXISTENCE_PROB_240:0, DET_HVC_FLAG_237:0, DET_HVC_FLAG_238:0, DET_HVC_FLAG_239:0, DET_HVC_FLAG_240:0, DET_IDM_237:0, DET_IDM_238:0, DET_IDM_239:0, DET_IDM_240:0, DET_MH_CRC16_237_240:0, DET_MH_CYCLE_COUNTER_237_240:0, DET_MH_SCAN_INDEX_4LSB_237_240:0, DET_MTD_237:0, DET_MTD_238:0, DET_MTD_239:0, DET_MTD_240:0, DET_PROB_1STAZHYPO_237:0, DET_PROB_1STAZHYPO_238:0, DET_PROB_1STAZHYPO_239:0, DET_PROB_1STAZHYPO_240:0, DET_RANGE_237:0, DET_RANGE_238:0, DET_RANGE_239:0, DET_RANGE_240:0, DET_RANGE_ERR_237:0, DET_RANGE_ERR_238:0, DET_RANGE_ERR_239:0, DET_RANGE_ERR_240:0, DET_RANGE_VELOCITY_237:16384, DET_RANGE_VELOCITY_238:16384, DET_RANGE_VELOCITY_239:16384, DET_RANGE_VELOCITY_240:16384, DET_RANGE_VELOCITY_ERR_237:0, DET_RANGE_VELOCITY_ERR_238:0, DET_RANGE_VELOCITY_ERR_239:0, DET_RANGE_VELOCITY_ERR_240:0, DET_RCS_237:128, DET_RCS_238:128, DET_RCS_239:128, DET_RCS_240:128, DET_SNR_237:0, DET_SNR_238:0, DET_SNR_239:0, DET_SNR_240:0, DET_SUPER_RES_TARGET_237:0, DET_SUPER_RES_TARGET_238:0, DET_SUPER_RES_TARGET_239:0, DET_SUPER_RES_TARGET_240:0]}, provided-interface=Pi_SG_Detections_237_240_AL
      Pp_SG_Detections_241_244_AL: nonqueued-sender-com-spec{data-element=Vdp_SG_Detections_241_244_AL, init-value=fields=[DET_AZIMUTH_241:0, DET_AZIMUTH_242:0, DET_AZIMUTH_243:0, DET_AZIMUTH_244:0, DET_AZIMUTH_ERR_241:0, DET_AZIMUTH_ERR_242:0, DET_AZIMUTH_ERR_243:0, DET_AZIMUTH_ERR_244:0, DET_BELOW_RAIN_THOLD_241:0, DET_BELOW_RAIN_THOLD_242:0, DET_BELOW_RAIN_THOLD_243:0, DET_BELOW_RAIN_THOLD_244:0, DET_BI_STATIC_FLAG_241:0, DET_BI_STATIC_FLAG_242:0, DET_BI_STATIC_FLAG_243:0, DET_BI_STATIC_FLAG_244:0, DET_CONFD_AZIMUTH_241:0, DET_CONFD_AZIMUTH_242:0, DET_CONFD_AZIMUTH_243:0, DET_CONFD_AZIMUTH_244:0, DET_CONFD_ELEVATION_241:0, DET_CONFD_ELEVATION_242:0, DET_CONFD_ELEVATION_243:0, DET_CONFD_ELEVATION_244:0, DET_ELEVATION_241:0, DET_ELEVATION_242:0, DET_ELEVATION_243:0, DET_ELEVATION_244:0, DET_ELEVATION_ERR_241:0, DET_ELEVATION_ERR_242:0, DET_ELEVATION_ERR_243:0, DET_ELEVATION_ERR_244:0, DET_EXISTENCE_PROB_241:0, DET_EXISTENCE_PROB_242:0, DET_EXISTENCE_PROB_243:0, DET_EXISTENCE_PROB_244:0, DET_HVC_FLAG_241:0, DET_HVC_FLAG_242:0, DET_HVC_FLAG_243:0, DET_HVC_FLAG_244:0, DET_IDM_241:0, DET_IDM_242:0, DET_IDM_243:0, DET_IDM_244:0, DET_MH_CRC16_241_244:0, DET_MH_CYCLE_COUNTER_241_244:0, DET_MH_SCAN_INDEX_4LSB_241_244:0, DET_MTD_241:0, DET_MTD_242:0, DET_MTD_243:0, DET_MTD_244:0, DET_PROB_1STAZHYPO_241:0, DET_PROB_1STAZHYPO_242:0, DET_PROB_1STAZHYPO_243:0, DET_PROB_1STAZHYPO_244:0, DET_RANGE_241:0, DET_RANGE_242:0, DET_RANGE_243:0, DET_RANGE_244:0, DET_RANGE_ERR_241:0, DET_RANGE_ERR_242:0, DET_RANGE_ERR_243:0, DET_RANGE_ERR_244:0, DET_RANGE_VELOCITY_241:16384, DET_RANGE_VELOCITY_242:16384, DET_RANGE_VELOCITY_243:16384, DET_RANGE_VELOCITY_244:16384, DET_RANGE_VELOCITY_ERR_241:0, DET_RANGE_VELOCITY_ERR_242:0, DET_RANGE_VELOCITY_ERR_243:0, DET_RANGE_VELOCITY_ERR_244:0, DET_RCS_241:128, DET_RCS_242:128, DET_RCS_243:128, DET_RCS_244:128, DET_SNR_241:0, DET_SNR_242:0, DET_SNR_243:0, DET_SNR_244:0, DET_SUPER_RES_TARGET_241:0, DET_SUPER_RES_TARGET_242:0, DET_SUPER_RES_TARGET_243:0, DET_SUPER_RES_TARGET_244:0]}, provided-interface=Pi_SG_Detections_241_244_AL
      Pp_SG_Detections_245_248_AL: nonqueued-sender-com-spec{data-element=Vdp_SG_Detections_245_248_AL, init-value=fields=[DET_AZIMUTH_245:0, DET_AZIMUTH_246:0, DET_AZIMUTH_247:0, DET_AZIMUTH_248:0, DET_AZIMUTH_ERR_245:0, DET_AZIMUTH_ERR_246:0, DET_AZIMUTH_ERR_247:0, DET_AZIMUTH_ERR_248:0, DET_BELOW_RAIN_THOLD_245:0, DET_BELOW_RAIN_THOLD_246:0, DET_BELOW_RAIN_THOLD_247:0, DET_BELOW_RAIN_THOLD_248:0, DET_BI_STATIC_FLAG_245:0, DET_BI_STATIC_FLAG_246:0, DET_BI_STATIC_FLAG_247:0, DET_BI_STATIC_FLAG_248:0, DET_CONFD_AZIMUTH_245:0, DET_CONFD_AZIMUTH_246:0, DET_CONFD_AZIMUTH_247:0, DET_CONFD_AZIMUTH_248:0, DET_CONFD_ELEVATION_245:0, DET_CONFD_ELEVATION_246:0, DET_CONFD_ELEVATION_247:0, DET_CONFD_ELEVATION_248:0, DET_ELEVATION_245:0, DET_ELEVATION_246:0, DET_ELEVATION_247:0, DET_ELEVATION_248:0, DET_ELEVATION_ERR_245:0, DET_ELEVATION_ERR_246:0, DET_ELEVATION_ERR_247:0, DET_ELEVATION_ERR_248:0, DET_EXISTENCE_PROB_245:0, DET_EXISTENCE_PROB_246:0, DET_EXISTENCE_PROB_247:0, DET_EXISTENCE_PROB_248:0, DET_HVC_FLAG_245:0, DET_HVC_FLAG_246:0, DET_HVC_FLAG_247:0, DET_HVC_FLAG_248:0, DET_IDM_245:0, DET_IDM_246:0, DET_IDM_247:0, DET_IDM_248:0, DET_MH_CRC16_245_248:0, DET_MH_CYCLE_COUNTER_245_248:0, DET_MH_SCAN_INDEX_4LSB_245_248:0, DET_MTD_245:0, DET_MTD_246:0, DET_MTD_247:0, DET_MTD_248:0, DET_PROB_1STAZHYPO_245:0, DET_PROB_1STAZHYPO_246:0, DET_PROB_1STAZHYPO_247:0, DET_PROB_1STAZHYPO_248:0, DET_RANGE_245:0, DET_RANGE_246:0, DET_RANGE_247:0, DET_RANGE_248:0, DET_RANGE_ERR_245:0, DET_RANGE_ERR_246:0, DET_RANGE_ERR_247:0, DET_RANGE_ERR_248:0, DET_RANGE_VELOCITY_245:16384, DET_RANGE_VELOCITY_246:16384, DET_RANGE_VELOCITY_247:16384, DET_RANGE_VELOCITY_248:16384, DET_RANGE_VELOCITY_ERR_245:0, DET_RANGE_VELOCITY_ERR_246:0, DET_RANGE_VELOCITY_ERR_247:0, DET_RANGE_VELOCITY_ERR_248:0, DET_RCS_245:128, DET_RCS_246:128, DET_RCS_247:128, DET_RCS_248:128, DET_SNR_245:0, DET_SNR_246:0, DET_SNR_247:0, DET_SNR_248:0, DET_SUPER_RES_TARGET_245:0, DET_SUPER_RES_TARGET_246:0, DET_SUPER_RES_TARGET_247:0, DET_SUPER_RES_TARGET_248:0]}, provided-interface=Pi_SG_Detections_245_248_AL
      Pp_SG_Detections_249_252_AL: nonqueued-sender-com-spec{data-element=Vdp_SG_Detections_249_252_AL, init-value=fields=[DET_AZIMUTH_249:0, DET_AZIMUTH_250:0, DET_AZIMUTH_251:0, DET_AZIMUTH_252:0, DET_AZIMUTH_ERR_249:0, DET_AZIMUTH_ERR_250:0, DET_AZIMUTH_ERR_251:0, DET_AZIMUTH_ERR_252:0, DET_BELOW_RAIN_THOLD_249:0, DET_BELOW_RAIN_THOLD_250:0, DET_BELOW_RAIN_THOLD_251:0, DET_BELOW_RAIN_THOLD_252:0, DET_BI_STATIC_FLAG_249:0, DET_BI_STATIC_FLAG_250:0, DET_BI_STATIC_FLAG_251:0, DET_BI_STATIC_FLAG_252:0, DET_CONFD_AZIMUTH_249:0, DET_CONFD_AZIMUTH_250:0, DET_CONFD_AZIMUTH_251:0, DET_CONFD_AZIMUTH_252:0, DET_CONFD_ELEVATION_249:0, DET_CONFD_ELEVATION_250:0, DET_CONFD_ELEVATION_251:0, DET_CONFD_ELEVATION_252:0, DET_ELEVATION_249:0, DET_ELEVATION_250:0, DET_ELEVATION_251:0, DET_ELEVATION_252:0, DET_ELEVATION_ERR_249:0, DET_ELEVATION_ERR_250:0, DET_ELEVATION_ERR_251:0, DET_ELEVATION_ERR_252:0, DET_EXISTENCE_PROB_249:0, DET_EXISTENCE_PROB_250:0, DET_EXISTENCE_PROB_251:0, DET_EXISTENCE_PROB_252:0, DET_HVC_FLAG_249:0, DET_HVC_FLAG_250:0, DET_HVC_FLAG_251:0, DET_HVC_FLAG_252:0, DET_IDM_249:0, DET_IDM_250:0, DET_IDM_251:0, DET_IDM_252:0, DET_MH_CRC16_249_252:0, DET_MH_CYCLE_COUNTER_249_252:0, DET_MH_SCAN_INDEX_4LSB_249_252:0, DET_MTD_249:0, DET_MTD_250:0, DET_MTD_251:0, DET_MTD_252:0, DET_PROB_1STAZHYPO_249:0, DET_PROB_1STAZHYPO_250:0, DET_PROB_1STAZHYPO_251:0, DET_PROB_1STAZHYPO_252:0, DET_RANGE_249:0, DET_RANGE_250:0, DET_RANGE_251:0, DET_RANGE_252:0, DET_RANGE_ERR_249:0, DET_RANGE_ERR_250:0, DET_RANGE_ERR_251:0, DET_RANGE_ERR_252:0, DET_RANGE_VELOCITY_249:16384, DET_RANGE_VELOCITY_250:16384, DET_RANGE_VELOCITY_251:16384, DET_RANGE_VELOCITY_252:16384, DET_RANGE_VELOCITY_ERR_249:0, DET_RANGE_VELOCITY_ERR_250:0, DET_RANGE_VELOCITY_ERR_251:0, DET_RANGE_VELOCITY_ERR_252:0, DET_RCS_249:128, DET_RCS_250:128, DET_RCS_251:128, DET_RCS_252:128, DET_SNR_249:0, DET_SNR_250:0, DET_SNR_251:0, DET_SNR_252:0, DET_SUPER_RES_TARGET_249:0, DET_SUPER_RES_TARGET_250:0, DET_SUPER_RES_TARGET_251:0, DET_SUPER_RES_TARGET_252:0]}, provided-interface=Pi_SG_Detections_249_252_AL
      Pp_SG_Detections_253_256_AL: nonqueued-sender-com-spec{data-element=Vdp_SG_Detections_253_256_AL, init-value=fields=[DET_AZIMUTH_253:0, DET_AZIMUTH_254:0, DET_AZIMUTH_255:0, DET_AZIMUTH_256:0, DET_AZIMUTH_ERR_253:0, DET_AZIMUTH_ERR_254:0, DET_AZIMUTH_ERR_255:0, DET_AZIMUTH_ERR_256:0, DET_BELOW_RAIN_THOLD_253:0, DET_BELOW_RAIN_THOLD_254:0, DET_BELOW_RAIN_THOLD_255:0, DET_BELOW_RAIN_THOLD_256:0, DET_BI_STATIC_FLAG_253:0, DET_BI_STATIC_FLAG_254:0, DET_BI_STATIC_FLAG_255:0, DET_BI_STATIC_FLAG_256:0, DET_CONFD_AZIMUTH_253:0, DET_CONFD_AZIMUTH_254:0, DET_CONFD_AZIMUTH_255:0, DET_CONFD_AZIMUTH_256:0, DET_CONFD_ELEVATION_253:0, DET_CONFD_ELEVATION_254:0, DET_CONFD_ELEVATION_255:0, DET_CONFD_ELEVATION_256:0, DET_ELEVATION_253:0, DET_ELEVATION_254:0, DET_ELEVATION_255:0, DET_ELEVATION_256:0, DET_ELEVATION_ERR_253:0, DET_ELEVATION_ERR_254:0, DET_ELEVATION_ERR_255:0, DET_ELEVATION_ERR_256:0, DET_EXISTENCE_PROB_253:0, DET_EXISTENCE_PROB_254:0, DET_EXISTENCE_PROB_255:0, DET_EXISTENCE_PROB_256:0, DET_HVC_FLAG_253:0, DET_HVC_FLAG_254:0, DET_HVC_FLAG_255:0, DET_HVC_FLAG_256:0, DET_IDM_253:0, DET_IDM_254:0, DET_IDM_255:0, DET_IDM_256:0, DET_MH_CRC16_253_256:0, DET_MH_CYCLE_COUNTER_253_256:0, DET_MH_SCAN_INDEX_4LSB_253_256:0, DET_MTD_253:0, DET_MTD_254:0, DET_MTD_255:0, DET_MTD_256:0, DET_PROB_1STAZHYPO_253:0, DET_PROB_1STAZHYPO_254:0, DET_PROB_1STAZHYPO_255:0, DET_PROB_1STAZHYPO_256:0, DET_RANGE_253:0, DET_RANGE_254:0, DET_RANGE_255:0, DET_RANGE_256:0, DET_RANGE_ERR_253:0, DET_RANGE_ERR_254:0, DET_RANGE_ERR_255:0, DET_RANGE_ERR_256:0, DET_RANGE_VELOCITY_253:16384, DET_RANGE_VELOCITY_254:16384, DET_RANGE_VELOCITY_255:16384, DET_RANGE_VELOCITY_256:16384, DET_RANGE_VELOCITY_ERR_253:0, DET_RANGE_VELOCITY_ERR_254:0, DET_RANGE_VELOCITY_ERR_255:0, DET_RANGE_VELOCITY_ERR_256:0, DET_RCS_253:128, DET_RCS_254:128, DET_RCS_255:128, DET_RCS_256:128, DET_SNR_253:0, DET_SNR_254:0, DET_SNR_255:0, DET_SNR_256:0, DET_SUPER_RES_TARGET_253:0, DET_SUPER_RES_TARGET_254:0, DET_SUPER_RES_TARGET_255:0, DET_SUPER_RES_TARGET_256:0]}, provided-interface=Pi_SG_Detections_253_256_AL
      Pp_SG_Detections_257_260_AL: nonqueued-sender-com-spec{data-element=Vdp_SG_Detections_257_260_AL, init-value=fields=[DET_AZIMUTH_257:0, DET_AZIMUTH_258:0, DET_AZIMUTH_259:0, DET_AZIMUTH_260:0, DET_AZIMUTH_ERR_257:0, DET_AZIMUTH_ERR_258:0, DET_AZIMUTH_ERR_259:0, DET_AZIMUTH_ERR_260:0, DET_BELOW_RAIN_THOLD_257:0, DET_BELOW_RAIN_THOLD_258:0, DET_BELOW_RAIN_THOLD_259:0, DET_BELOW_RAIN_THOLD_260:0, DET_BI_STATIC_FLAG_257:0, DET_BI_STATIC_FLAG_258:0, DET_BI_STATIC_FLAG_259:0, DET_BI_STATIC_FLAG_260:0, DET_CONFD_AZIMUTH_257:0, DET_CONFD_AZIMUTH_258:0, DET_CONFD_AZIMUTH_259:0, DET_CONFD_AZIMUTH_260:0, DET_CONFD_ELEVATION_257:0, DET_CONFD_ELEVATION_258:0, DET_CONFD_ELEVATION_259:0, DET_CONFD_ELEVATION_260:0, DET_ELEVATION_257:0, DET_ELEVATION_258:0, DET_ELEVATION_259:0, DET_ELEVATION_260:0, DET_ELEVATION_ERR_257:0, DET_ELEVATION_ERR_258:0, DET_ELEVATION_ERR_259:0, DET_ELEVATION_ERR_260:0, DET_EXISTENCE_PROB_257:0, DET_EXISTENCE_PROB_258:0, DET_EXISTENCE_PROB_259:0, DET_EXISTENCE_PROB_260:0, DET_HVC_FLAG_257:0, DET_HVC_FLAG_258:0, DET_HVC_FLAG_259:0, DET_HVC_FLAG_260:0, DET_IDM_257:0, DET_IDM_258:0, DET_IDM_259:0, DET_IDM_260:0, DET_MH_CRC16_257_260:0, DET_MH_CYCLE_COUNTER_257_260:0, DET_MH_SCAN_INDEX_4LSB_257_260:0, DET_MTD_257:0, DET_MTD_258:0, DET_MTD_259:0, DET_MTD_260:0, DET_PROB_1STAZHYPO_257:0, DET_PROB_1STAZHYPO_258:0, DET_PROB_1STAZHYPO_259:0, DET_PROB_1STAZHYPO_260:0, DET_RANGE_257:0, DET_RANGE_258:0, DET_RANGE_259:0, DET_RANGE_260:0, DET_RANGE_ERR_257:0, DET_RANGE_ERR_258:0, DET_RANGE_ERR_259:0, DET_RANGE_ERR_260:0, DET_RANGE_VELOCITY_257:16384, DET_RANGE_VELOCITY_258:16384, DET_RANGE_VELOCITY_259:16384, DET_RANGE_VELOCITY_260:16384, DET_RANGE_VELOCITY_ERR_257:0, DET_RANGE_VELOCITY_ERR_258:0, DET_RANGE_VELOCITY_ERR_259:0, DET_RANGE_VELOCITY_ERR_260:0, DET_RCS_257:128, DET_RCS_258:128, DET_RCS_259:128, DET_RCS_260:128, DET_SNR_257:0, DET_SNR_258:0, DET_SNR_259:0, DET_SNR_260:0, DET_SUPER_RES_TARGET_257:0, DET_SUPER_RES_TARGET_258:0, DET_SUPER_RES_TARGET_259:0, DET_SUPER_RES_TARGET_260:0]}, provided-interface=Pi_SG_Detections_257_260_AL
      Pp_SG_Detections_261_264_AL: nonqueued-sender-com-spec{data-element=Vdp_SG_Detections_261_264_AL, init-value=fields=[DET_AZIMUTH_261:0, DET_AZIMUTH_262:0, DET_AZIMUTH_263:0, DET_AZIMUTH_264:0, DET_AZIMUTH_ERR_261:0, DET_AZIMUTH_ERR_262:0, DET_AZIMUTH_ERR_263:0, DET_AZIMUTH_ERR_264:0, DET_BELOW_RAIN_THOLD_261:0, DET_BELOW_RAIN_THOLD_262:0, DET_BELOW_RAIN_THOLD_263:0, DET_BELOW_RAIN_THOLD_264:0, DET_BI_STATIC_FLAG_261:0, DET_BI_STATIC_FLAG_262:0, DET_BI_STATIC_FLAG_263:0, DET_BI_STATIC_FLAG_264:0, DET_CONFD_AZIMUTH_261:0, DET_CONFD_AZIMUTH_262:0, DET_CONFD_AZIMUTH_263:0, DET_CONFD_AZIMUTH_264:0, DET_CONFD_ELEVATION_261:0, DET_CONFD_ELEVATION_262:0, DET_CONFD_ELEVATION_263:0, DET_CONFD_ELEVATION_264:0, DET_ELEVATION_261:0, DET_ELEVATION_262:0, DET_ELEVATION_263:0, DET_ELEVATION_264:0, DET_ELEVATION_ERR_261:0, DET_ELEVATION_ERR_262:0, DET_ELEVATION_ERR_263:0, DET_ELEVATION_ERR_264:0, DET_EXISTENCE_PROB_261:0, DET_EXISTENCE_PROB_262:0, DET_EXISTENCE_PROB_263:0, DET_EXISTENCE_PROB_264:0, DET_HVC_FLAG_261:0, DET_HVC_FLAG_262:0, DET_HVC_FLAG_263:0, DET_HVC_FLAG_264:0, DET_IDM_261:0, DET_IDM_262:0, DET_IDM_263:0, DET_IDM_264:0, DET_MH_CRC16_261_264:0, DET_MH_CYCLE_COUNTER_261_264:0, DET_MH_SCAN_INDEX_4LSB_261_264:0, DET_MTD_261:0, DET_MTD_262:0, DET_MTD_263:0, DET_MTD_264:0, DET_PROB_1STAZHYPO_261:0, DET_PROB_1STAZHYPO_262:0, DET_PROB_1STAZHYPO_263:0, DET_PROB_1STAZHYPO_264:0, DET_RANGE_261:0, DET_RANGE_262:0, DET_RANGE_263:0, DET_RANGE_264:0, DET_RANGE_ERR_261:0, DET_RANGE_ERR_262:0, DET_RANGE_ERR_263:0, DET_RANGE_ERR_264:0, DET_RANGE_VELOCITY_261:16384, DET_RANGE_VELOCITY_262:16384, DET_RANGE_VELOCITY_263:16384, DET_RANGE_VELOCITY_264:16384, DET_RANGE_VELOCITY_ERR_261:0, DET_RANGE_VELOCITY_ERR_262:0, DET_RANGE_VELOCITY_ERR_263:0, DET_RANGE_VELOCITY_ERR_264:0, DET_RCS_261:128, DET_RCS_262:128, DET_RCS_263:128, DET_RCS_264:128, DET_SNR_261:0, DET_SNR_262:0, DET_SNR_263:0, DET_SNR_264:0, DET_SUPER_RES_TARGET_261:0, DET_SUPER_RES_TARGET_262:0, DET_SUPER_RES_TARGET_263:0, DET_SUPER_RES_TARGET_264:0]}, provided-interface=Pi_SG_Detections_261_264_AL
      Pp_SG_Detections_265_268_AL: nonqueued-sender-com-spec{data-element=Vdp_SG_Detections_265_268_AL, init-value=fields=[DET_AZIMUTH_265:0, DET_AZIMUTH_266:0, DET_AZIMUTH_267:0, DET_AZIMUTH_268:0, DET_AZIMUTH_ERR_265:0, DET_AZIMUTH_ERR_266:0, DET_AZIMUTH_ERR_267:0, DET_AZIMUTH_ERR_268:0, DET_BELOW_RAIN_THOLD_265:0, DET_BELOW_RAIN_THOLD_266:0, DET_BELOW_RAIN_THOLD_267:0, DET_BELOW_RAIN_THOLD_268:0, DET_BI_STATIC_FLAG_265:0, DET_BI_STATIC_FLAG_266:0, DET_BI_STATIC_FLAG_267:0, DET_BI_STATIC_FLAG_268:0, DET_CONFD_AZIMUTH_265:0, DET_CONFD_AZIMUTH_266:0, DET_CONFD_AZIMUTH_267:0, DET_CONFD_AZIMUTH_268:0, DET_CONFD_ELEVATION_265:0, DET_CONFD_ELEVATION_266:0, DET_CONFD_ELEVATION_267:0, DET_CONFD_ELEVATION_268:0, DET_ELEVATION_265:0, DET_ELEVATION_266:0, DET_ELEVATION_267:0, DET_ELEVATION_268:0, DET_ELEVATION_ERR_265:0, DET_ELEVATION_ERR_266:0, DET_ELEVATION_ERR_267:0, DET_ELEVATION_ERR_268:0, DET_EXISTENCE_PROB_265:0, DET_EXISTENCE_PROB_266:0, DET_EXISTENCE_PROB_267:0, DET_EXISTENCE_PROB_268:0, DET_HVC_FLAG_265:0, DET_HVC_FLAG_266:0, DET_HVC_FLAG_267:0, DET_HVC_FLAG_268:0, DET_IDM_265:0, DET_IDM_266:0, DET_IDM_267:0, DET_IDM_268:0, DET_MH_CRC16_265_268:0, DET_MH_CYCLE_COUNTER_265_268:0, DET_MH_SCAN_INDEX_4LSB_265_268:0, DET_MTD_265:0, DET_MTD_266:0, DET_MTD_267:0, DET_MTD_268:0, DET_PROB_1STAZHYPO_265:0, DET_PROB_1STAZHYPO_266:0, DET_PROB_1STAZHYPO_267:0, DET_PROB_1STAZHYPO_268:0, DET_RANGE_265:0, DET_RANGE_266:0, DET_RANGE_267:0, DET_RANGE_268:0, DET_RANGE_ERR_265:0, DET_RANGE_ERR_266:0, DET_RANGE_ERR_267:0, DET_RANGE_ERR_268:0, DET_RANGE_VELOCITY_265:16384, DET_RANGE_VELOCITY_266:16384, DET_RANGE_VELOCITY_267:16384, DET_RANGE_VELOCITY_268:16384, DET_RANGE_VELOCITY_ERR_265:0, DET_RANGE_VELOCITY_ERR_266:0, DET_RANGE_VELOCITY_ERR_267:0, DET_RANGE_VELOCITY_ERR_268:0, DET_RCS_265:128, DET_RCS_266:128, DET_RCS_267:128, DET_RCS_268:128, DET_SNR_265:0, DET_SNR_266:0, DET_SNR_267:0, DET_SNR_268:0, DET_SUPER_RES_TARGET_265:0, DET_SUPER_RES_TARGET_266:0, DET_SUPER_RES_TARGET_267:0, DET_SUPER_RES_TARGET_268:0]}, provided-interface=Pi_SG_Detections_265_268_AL
      Pp_SG_Detections_269_272_AL: nonqueued-sender-com-spec{data-element=Vdp_SG_Detections_269_272_AL, init-value=fields=[DET_AZIMUTH_269:0, DET_AZIMUTH_270:0, DET_AZIMUTH_271:0, DET_AZIMUTH_272:0, DET_AZIMUTH_ERR_269:0, DET_AZIMUTH_ERR_270:0, DET_AZIMUTH_ERR_271:0, DET_AZIMUTH_ERR_272:0, DET_BELOW_RAIN_THOLD_269:0, DET_BELOW_RAIN_THOLD_270:0, DET_BELOW_RAIN_THOLD_271:0, DET_BELOW_RAIN_THOLD_272:0, DET_BI_STATIC_FLAG_269:0, DET_BI_STATIC_FLAG_270:0, DET_BI_STATIC_FLAG_271:0, DET_BI_STATIC_FLAG_272:0, DET_CONFD_AZIMUTH_269:0, DET_CONFD_AZIMUTH_270:0, DET_CONFD_AZIMUTH_271:0, DET_CONFD_AZIMUTH_272:0, DET_CONFD_ELEVATION_269:0, DET_CONFD_ELEVATION_270:0, DET_CONFD_ELEVATION_271:0, DET_CONFD_ELEVATION_272:0, DET_ELEVATION_269:0, DET_ELEVATION_270:0, DET_ELEVATION_271:0, DET_ELEVATION_272:0, DET_ELEVATION_ERR_269:0, DET_ELEVATION_ERR_270:0, DET_ELEVATION_ERR_271:0, DET_ELEVATION_ERR_272:0, DET_EXISTENCE_PROB_269:0, DET_EXISTENCE_PROB_270:0, DET_EXISTENCE_PROB_271:0, DET_EXISTENCE_PROB_272:0, DET_HVC_FLAG_269:0, DET_HVC_FLAG_270:0, DET_HVC_FLAG_271:0, DET_HVC_FLAG_272:0, DET_IDM_269:0, DET_IDM_270:0, DET_IDM_271:0, DET_IDM_272:0, DET_MH_CRC16_269_272:0, DET_MH_CYCLE_COUNTER_269_272:0, DET_MH_SCAN_INDEX_4LSB_269_272:0, DET_MTD_269:0, DET_MTD_270:0, DET_MTD_271:0, DET_MTD_272:0, DET_PROB_1STAZHYPO_269:0, DET_PROB_1STAZHYPO_270:0, DET_PROB_1STAZHYPO_271:0, DET_PROB_1STAZHYPO_272:0, DET_RANGE_269:0, DET_RANGE_270:0, DET_RANGE_271:0, DET_RANGE_272:0, DET_RANGE_ERR_269:0, DET_RANGE_ERR_270:0, DET_RANGE_ERR_271:0, DET_RANGE_ERR_272:0, DET_RANGE_VELOCITY_269:16384, DET_RANGE_VELOCITY_270:16384, DET_RANGE_VELOCITY_271:16384, DET_RANGE_VELOCITY_272:16384, DET_RANGE_VELOCITY_ERR_269:0, DET_RANGE_VELOCITY_ERR_270:0, DET_RANGE_VELOCITY_ERR_271:0, DET_RANGE_VELOCITY_ERR_272:0, DET_RCS_269:128, DET_RCS_270:128, DET_RCS_271:128, DET_RCS_272:128, DET_SNR_269:0, DET_SNR_270:0, DET_SNR_271:0, DET_SNR_272:0, DET_SUPER_RES_TARGET_269:0, DET_SUPER_RES_TARGET_270:0, DET_SUPER_RES_TARGET_271:0, DET_SUPER_RES_TARGET_272:0]}, provided-interface=Pi_SG_Detections_269_272_AL
      Pp_SG_Detections_273_276_AL: nonqueued-sender-com-spec{data-element=Vdp_SG_Detections_273_276_AL, init-value=fields=[DET_AZIMUTH_273:0, DET_AZIMUTH_274:0, DET_AZIMUTH_275:0, DET_AZIMUTH_276:0, DET_AZIMUTH_ERR_273:0, DET_AZIMUTH_ERR_274:0, DET_AZIMUTH_ERR_275:0, DET_AZIMUTH_ERR_276:0, DET_BELOW_RAIN_THOLD_273:0, DET_BELOW_RAIN_THOLD_274:0, DET_BELOW_RAIN_THOLD_275:0, DET_BELOW_RAIN_THOLD_276:0, DET_BI_STATIC_FLAG_273:0, DET_BI_STATIC_FLAG_274:0, DET_BI_STATIC_FLAG_275:0, DET_BI_STATIC_FLAG_276:0, DET_CONFD_AZIMUTH_273:0, DET_CONFD_AZIMUTH_274:0, DET_CONFD_AZIMUTH_275:0, DET_CONFD_AZIMUTH_276:0, DET_CONFD_ELEVATION_273:0, DET_CONFD_ELEVATION_274:0, DET_CONFD_ELEVATION_275:0, DET_CONFD_ELEVATION_276:0, DET_ELEVATION_273:0, DET_ELEVATION_274:0, DET_ELEVATION_275:0, DET_ELEVATION_276:0, DET_ELEVATION_ERR_273:0, DET_ELEVATION_ERR_274:0, DET_ELEVATION_ERR_275:0, DET_ELEVATION_ERR_276:0, DET_EXISTENCE_PROB_273:0, DET_EXISTENCE_PROB_274:0, DET_EXISTENCE_PROB_275:0, DET_EXISTENCE_PROB_276:0, DET_HVC_FLAG_273:0, DET_HVC_FLAG_274:0, DET_HVC_FLAG_275:0, DET_HVC_FLAG_276:0, DET_IDM_273:0, DET_IDM_274:0, DET_IDM_275:0, DET_IDM_276:0, DET_MH_CRC16_273_276:0, DET_MH_CYCLE_COUNTER_273_276:0, DET_MH_SCAN_INDEX_4LSB_273_276:0, DET_MTD_273:0, DET_MTD_274:0, DET_MTD_275:0, DET_MTD_276:0, DET_PROB_1STAZHYPO_273:0, DET_PROB_1STAZHYPO_274:0, DET_PROB_1STAZHYPO_275:0, DET_PROB_1STAZHYPO_276:0, DET_RANGE_273:0, DET_RANGE_274:0, DET_RANGE_275:0, DET_RANGE_276:0, DET_RANGE_ERR_273:0, DET_RANGE_ERR_274:0, DET_RANGE_ERR_275:0, DET_RANGE_ERR_276:0, DET_RANGE_VELOCITY_273:16384, DET_RANGE_VELOCITY_274:16384, DET_RANGE_VELOCITY_275:16384, DET_RANGE_VELOCITY_276:16384, DET_RANGE_VELOCITY_ERR_273:0, DET_RANGE_VELOCITY_ERR_274:0, DET_RANGE_VELOCITY_ERR_275:0, DET_RANGE_VELOCITY_ERR_276:0, DET_RCS_273:128, DET_RCS_274:128, DET_RCS_275:128, DET_RCS_276:128, DET_SNR_273:0, DET_SNR_274:0, DET_SNR_275:0, DET_SNR_276:0, DET_SUPER_RES_TARGET_273:0, DET_SUPER_RES_TARGET_274:0, DET_SUPER_RES_TARGET_275:0, DET_SUPER_RES_TARGET_276:0]}, provided-interface=Pi_SG_Detections_273_276_AL
      Pp_SG_Detections_277_280_AL: nonqueued-sender-com-spec{data-element=Vdp_SG_Detections_277_280_AL, init-value=fields=[DET_AZIMUTH_277:0, DET_AZIMUTH_278:0, DET_AZIMUTH_279:0, DET_AZIMUTH_280:0, DET_AZIMUTH_ERR_277:0, DET_AZIMUTH_ERR_278:0, DET_AZIMUTH_ERR_279:0, DET_AZIMUTH_ERR_280:0, DET_BELOW_RAIN_THOLD_277:0, DET_BELOW_RAIN_THOLD_278:0, DET_BELOW_RAIN_THOLD_279:0, DET_BELOW_RAIN_THOLD_280:0, DET_BI_STATIC_FLAG_277:0, DET_BI_STATIC_FLAG_278:0, DET_BI_STATIC_FLAG_279:0, DET_BI_STATIC_FLAG_280:0, DET_CONFD_AZIMUTH_277:0, DET_CONFD_AZIMUTH_278:0, DET_CONFD_AZIMUTH_279:0, DET_CONFD_AZIMUTH_280:0, DET_CONFD_ELEVATION_277:0, DET_CONFD_ELEVATION_278:0, DET_CONFD_ELEVATION_279:0, DET_CONFD_ELEVATION_280:0, DET_ELEVATION_277:0, DET_ELEVATION_278:0, DET_ELEVATION_279:0, DET_ELEVATION_280:0, DET_ELEVATION_ERR_277:0, DET_ELEVATION_ERR_278:0, DET_ELEVATION_ERR_279:0, DET_ELEVATION_ERR_280:0, DET_EXISTENCE_PROB_277:0, DET_EXISTENCE_PROB_278:0, DET_EXISTENCE_PROB_279:0, DET_EXISTENCE_PROB_280:0, DET_HVC_FLAG_277:0, DET_HVC_FLAG_278:0, DET_HVC_FLAG_279:0, DET_HVC_FLAG_280:0, DET_IDM_277:0, DET_IDM_278:0, DET_IDM_279:0, DET_IDM_280:0, DET_MH_CRC16_277_280:0, DET_MH_CYCLE_COUNTER_277_280:0, DET_MH_SCAN_INDEX_4LSB_277_280:0, DET_MTD_277:0, DET_MTD_278:0, DET_MTD_279:0, DET_MTD_280:0, DET_PROB_1STAZHYPO_277:0, DET_PROB_1STAZHYPO_278:0, DET_PROB_1STAZHYPO_279:0, DET_PROB_1STAZHYPO_280:0, DET_RANGE_277:0, DET_RANGE_278:0, DET_RANGE_279:0, DET_RANGE_280:0, DET_RANGE_ERR_277:0, DET_RANGE_ERR_278:0, DET_RANGE_ERR_279:0, DET_RANGE_ERR_280:0, DET_RANGE_VELOCITY_277:16384, DET_RANGE_VELOCITY_278:16384, DET_RANGE_VELOCITY_279:16384, DET_RANGE_VELOCITY_280:16384, DET_RANGE_VELOCITY_ERR_277:0, DET_RANGE_VELOCITY_ERR_278:0, DET_RANGE_VELOCITY_ERR_279:0, DET_RANGE_VELOCITY_ERR_280:0, DET_RCS_277:128, DET_RCS_278:128, DET_RCS_279:128, DET_RCS_280:128, DET_SNR_277:0, DET_SNR_278:0, DET_SNR_279:0, DET_SNR_280:0, DET_SUPER_RES_TARGET_277:0, DET_SUPER_RES_TARGET_278:0, DET_SUPER_RES_TARGET_279:0, DET_SUPER_RES_TARGET_280:0]}, provided-interface=Pi_SG_Detections_277_280_AL
      Pp_SG_Detections_281_284_AL: nonqueued-sender-com-spec{data-element=Vdp_SG_Detections_281_284_AL, init-value=fields=[DET_AZIMUTH_281:0, DET_AZIMUTH_282:0, DET_AZIMUTH_283:0, DET_AZIMUTH_284:0, DET_AZIMUTH_ERR_281:0, DET_AZIMUTH_ERR_282:0, DET_AZIMUTH_ERR_283:0, DET_AZIMUTH_ERR_284:0, DET_BELOW_RAIN_THOLD_281:0, DET_BELOW_RAIN_THOLD_282:0, DET_BELOW_RAIN_THOLD_283:0, DET_BELOW_RAIN_THOLD_284:0, DET_BI_STATIC_FLAG_281:0, DET_BI_STATIC_FLAG_282:0, DET_BI_STATIC_FLAG_283:0, DET_BI_STATIC_FLAG_284:0, DET_CONFD_AZIMUTH_281:0, DET_CONFD_AZIMUTH_282:0, DET_CONFD_AZIMUTH_283:0, DET_CONFD_AZIMUTH_284:0, DET_CONFD_ELEVATION_281:0, DET_CONFD_ELEVATION_282:0, DET_CONFD_ELEVATION_283:0, DET_CONFD_ELEVATION_284:0, DET_ELEVATION_281:0, DET_ELEVATION_282:0, DET_ELEVATION_283:0, DET_ELEVATION_284:0, DET_ELEVATION_ERR_281:0, DET_ELEVATION_ERR_282:0, DET_ELEVATION_ERR_283:0, DET_ELEVATION_ERR_284:0, DET_EXISTENCE_PROB_281:0, DET_EXISTENCE_PROB_282:0, DET_EXISTENCE_PROB_283:0, DET_EXISTENCE_PROB_284:0, DET_HVC_FLAG_281:0, DET_HVC_FLAG_282:0, DET_HVC_FLAG_283:0, DET_HVC_FLAG_284:0, DET_IDM_281:0, DET_IDM_282:0, DET_IDM_283:0, DET_IDM_284:0, DET_MH_CRC16_281_284:0, DET_MH_CYCLE_COUNTER_281_284:0, DET_MH_SCAN_INDEX_4LSB_281_284:0, DET_MTD_281:0, DET_MTD_282:0, DET_MTD_283:0, DET_MTD_284:0, DET_PROB_1STAZHYPO_281:0, DET_PROB_1STAZHYPO_282:0, DET_PROB_1STAZHYPO_283:0, DET_PROB_1STAZHYPO_284:0, DET_RANGE_281:0, DET_RANGE_282:0, DET_RANGE_283:0, DET_RANGE_284:0, DET_RANGE_ERR_281:0, DET_RANGE_ERR_282:0, DET_RANGE_ERR_283:0, DET_RANGE_ERR_284:0, DET_RANGE_VELOCITY_281:16384, DET_RANGE_VELOCITY_282:16384, DET_RANGE_VELOCITY_283:16384, DET_RANGE_VELOCITY_284:16384, DET_RANGE_VELOCITY_ERR_281:0, DET_RANGE_VELOCITY_ERR_282:0, DET_RANGE_VELOCITY_ERR_283:0, DET_RANGE_VELOCITY_ERR_284:0, DET_RCS_281:128, DET_RCS_282:128, DET_RCS_283:128, DET_RCS_284:128, DET_SNR_281:0, DET_SNR_282:0, DET_SNR_283:0, DET_SNR_284:0, DET_SUPER_RES_TARGET_281:0, DET_SUPER_RES_TARGET_282:0, DET_SUPER_RES_TARGET_283:0, DET_SUPER_RES_TARGET_284:0]}, provided-interface=Pi_SG_Detections_281_284_AL
      Pp_SG_Detections_285_288_AL: nonqueued-sender-com-spec{data-element=Vdp_SG_Detections_285_288_AL, init-value=fields=[DET_AZIMUTH_285:0, DET_AZIMUTH_286:0, DET_AZIMUTH_287:0, DET_AZIMUTH_288:0, DET_AZIMUTH_ERR_285:0, DET_AZIMUTH_ERR_286:0, DET_AZIMUTH_ERR_287:0, DET_AZIMUTH_ERR_288:0, DET_BELOW_RAIN_THOLD_285:0, DET_BELOW_RAIN_THOLD_286:0, DET_BELOW_RAIN_THOLD_287:0, DET_BELOW_RAIN_THOLD_288:0, DET_BI_STATIC_FLAG_285:0, DET_BI_STATIC_FLAG_286:0, DET_BI_STATIC_FLAG_287:0, DET_BI_STATIC_FLAG_288:0, DET_CONFD_AZIMUTH_285:0, DET_CONFD_AZIMUTH_286:0, DET_CONFD_AZIMUTH_287:0, DET_CONFD_AZIMUTH_288:0, DET_CONFD_ELEVATION_285:0, DET_CONFD_ELEVATION_286:0, DET_CONFD_ELEVATION_287:0, DET_CONFD_ELEVATION_288:0, DET_ELEVATION_285:0, DET_ELEVATION_286:0, DET_ELEVATION_287:0, DET_ELEVATION_288:0, DET_ELEVATION_ERR_285:0, DET_ELEVATION_ERR_286:0, DET_ELEVATION_ERR_287:0, DET_ELEVATION_ERR_288:0, DET_EXISTENCE_PROB_285:0, DET_EXISTENCE_PROB_286:0, DET_EXISTENCE_PROB_287:0, DET_EXISTENCE_PROB_288:0, DET_HVC_FLAG_285:0, DET_HVC_FLAG_286:0, DET_HVC_FLAG_287:0, DET_HVC_FLAG_288:0, DET_IDM_285:0, DET_IDM_286:0, DET_IDM_287:0, DET_IDM_288:0, DET_MH_CRC16_285_288:0, DET_MH_CYCLE_COUNTER_285_288:0, DET_MH_SCAN_INDEX_4LSB_285_288:0, DET_MTD_285:0, DET_MTD_286:0, DET_MTD_287:0, DET_MTD_288:0, DET_PROB_1STAZHYPO_285:0, DET_PROB_1STAZHYPO_286:0, DET_PROB_1STAZHYPO_287:0, DET_PROB_1STAZHYPO_288:0, DET_RANGE_285:0, DET_RANGE_286:0, DET_RANGE_287:0, DET_RANGE_288:0, DET_RANGE_ERR_285:0, DET_RANGE_ERR_286:0, DET_RANGE_ERR_287:0, DET_RANGE_ERR_288:0, DET_RANGE_VELOCITY_285:16384, DET_RANGE_VELOCITY_286:16384, DET_RANGE_VELOCITY_287:16384, DET_RANGE_VELOCITY_288:16384, DET_RANGE_VELOCITY_ERR_285:0, DET_RANGE_VELOCITY_ERR_286:0, DET_RANGE_VELOCITY_ERR_287:0, DET_RANGE_VELOCITY_ERR_288:0, DET_RCS_285:128, DET_RCS_286:128, DET_RCS_287:128, DET_RCS_288:128, DET_SNR_285:0, DET_SNR_286:0, DET_SNR_287:0, DET_SNR_288:0, DET_SUPER_RES_TARGET_285:0, DET_SUPER_RES_TARGET_286:0, DET_SUPER_RES_TARGET_287:0, DET_SUPER_RES_TARGET_288:0]}, provided-interface=Pi_SG_Detections_285_288_AL
      Pp_SG_Detections_289_292_AL: nonqueued-sender-com-spec{data-element=Vdp_SG_Detections_289_292_AL, init-value=fields=[DET_AZIMUTH_289:0, DET_AZIMUTH_290:0, DET_AZIMUTH_291:0, DET_AZIMUTH_292:0, DET_AZIMUTH_ERR_289:0, DET_AZIMUTH_ERR_290:0, DET_AZIMUTH_ERR_291:0, DET_AZIMUTH_ERR_292:0, DET_BELOW_RAIN_THOLD_289:0, DET_BELOW_RAIN_THOLD_290:0, DET_BELOW_RAIN_THOLD_291:0, DET_BELOW_RAIN_THOLD_292:0, DET_BI_STATIC_FLAG_289:0, DET_BI_STATIC_FLAG_290:0, DET_BI_STATIC_FLAG_291:0, DET_BI_STATIC_FLAG_292:0, DET_CONFD_AZIMUTH_289:0, DET_CONFD_AZIMUTH_290:0, DET_CONFD_AZIMUTH_291:0, DET_CONFD_AZIMUTH_292:0, DET_CONFD_ELEVATION_289:0, DET_CONFD_ELEVATION_290:0, DET_CONFD_ELEVATION_291:0, DET_CONFD_ELEVATION_292:0, DET_ELEVATION_289:0, DET_ELEVATION_290:0, DET_ELEVATION_291:0, DET_ELEVATION_292:0, DET_ELEVATION_ERR_289:0, DET_ELEVATION_ERR_290:0, DET_ELEVATION_ERR_291:0, DET_ELEVATION_ERR_292:0, DET_EXISTENCE_PROB_289:0, DET_EXISTENCE_PROB_290:0, DET_EXISTENCE_PROB_291:0, DET_EXISTENCE_PROB_292:0, DET_HVC_FLAG_289:0, DET_HVC_FLAG_290:0, DET_HVC_FLAG_291:0, DET_HVC_FLAG_292:0, DET_IDM_289:0, DET_IDM_290:0, DET_IDM_291:0, DET_IDM_292:0, DET_MH_CRC16_289_292:0, DET_MH_CYCLE_COUNTER_289_292:0, DET_MH_SCAN_INDEX_4LSB_289_292:0, DET_MTD_289:0, DET_MTD_290:0, DET_MTD_291:0, DET_MTD_292:0, DET_PROB_1STAZHYPO_289:0, DET_PROB_1STAZHYPO_290:0, DET_PROB_1STAZHYPO_291:0, DET_PROB_1STAZHYPO_292:0, DET_RANGE_289:0, DET_RANGE_290:0, DET_RANGE_291:0, DET_RANGE_292:0, DET_RANGE_ERR_289:0, DET_RANGE_ERR_290:0, DET_RANGE_ERR_291:0, DET_RANGE_ERR_292:0, DET_RANGE_VELOCITY_289:16384, DET_RANGE_VELOCITY_290:16384, DET_RANGE_VELOCITY_291:16384, DET_RANGE_VELOCITY_292:16384, DET_RANGE_VELOCITY_ERR_289:0, DET_RANGE_VELOCITY_ERR_290:0, DET_RANGE_VELOCITY_ERR_291:0, DET_RANGE_VELOCITY_ERR_292:0, DET_RCS_289:128, DET_RCS_290:128, DET_RCS_291:128, DET_RCS_292:128, DET_SNR_289:0, DET_SNR_290:0, DET_SNR_291:0, DET_SNR_292:0, DET_SUPER_RES_TARGET_289:0, DET_SUPER_RES_TARGET_290:0, DET_SUPER_RES_TARGET_291:0, DET_SUPER_RES_TARGET_292:0]}, provided-interface=Pi_SG_Detections_289_292_AL
      Pp_SG_Detections_293_296_AL: nonqueued-sender-com-spec{data-element=Vdp_SG_Detections_293_296_AL, init-value=fields=[DET_AZIMUTH_293:0, DET_AZIMUTH_294:0, DET_AZIMUTH_295:0, DET_AZIMUTH_296:0, DET_AZIMUTH_ERR_293:0, DET_AZIMUTH_ERR_294:0, DET_AZIMUTH_ERR_295:0, DET_AZIMUTH_ERR_296:0, DET_BELOW_RAIN_THOLD_293:0, DET_BELOW_RAIN_THOLD_294:0, DET_BELOW_RAIN_THOLD_295:0, DET_BELOW_RAIN_THOLD_296:0, DET_BI_STATIC_FLAG_293:0, DET_BI_STATIC_FLAG_294:0, DET_BI_STATIC_FLAG_295:0, DET_BI_STATIC_FLAG_296:0, DET_CONFD_AZIMUTH_293:0, DET_CONFD_AZIMUTH_294:0, DET_CONFD_AZIMUTH_295:0, DET_CONFD_AZIMUTH_296:0, DET_CONFD_ELEVATION_293:0, DET_CONFD_ELEVATION_294:0, DET_CONFD_ELEVATION_295:0, DET_CONFD_ELEVATION_296:0, DET_ELEVATION_293:0, DET_ELEVATION_294:0, DET_ELEVATION_295:0, DET_ELEVATION_296:0, DET_ELEVATION_ERR_293:0, DET_ELEVATION_ERR_294:0, DET_ELEVATION_ERR_295:0, DET_ELEVATION_ERR_296:0, DET_EXISTENCE_PROB_293:0, DET_EXISTENCE_PROB_294:0, DET_EXISTENCE_PROB_295:0, DET_EXISTENCE_PROB_296:0, DET_HVC_FLAG_293:0, DET_HVC_FLAG_294:0, DET_HVC_FLAG_295:0, DET_HVC_FLAG_296:0, DET_IDM_293:0, DET_IDM_294:0, DET_IDM_295:0, DET_IDM_296:0, DET_MH_CRC16_293_296:0, DET_MH_CYCLE_COUNTER_293_296:0, DET_MH_SCAN_INDEX_4LSB_293_296:0, DET_MTD_293:0, DET_MTD_294:0, DET_MTD_295:0, DET_MTD_296:0, DET_PROB_1STAZHYPO_293:0, DET_PROB_1STAZHYPO_294:0, DET_PROB_1STAZHYPO_295:0, DET_PROB_1STAZHYPO_296:0, DET_RANGE_293:0, DET_RANGE_294:0, DET_RANGE_295:0, DET_RANGE_296:0, DET_RANGE_ERR_293:0, DET_RANGE_ERR_294:0, DET_RANGE_ERR_295:0, DET_RANGE_ERR_296:0, DET_RANGE_VELOCITY_293:16384, DET_RANGE_VELOCITY_294:16384, DET_RANGE_VELOCITY_295:16384, DET_RANGE_VELOCITY_296:16384, DET_RANGE_VELOCITY_ERR_293:0, DET_RANGE_VELOCITY_ERR_294:0, DET_RANGE_VELOCITY_ERR_295:0, DET_RANGE_VELOCITY_ERR_296:0, DET_RCS_293:128, DET_RCS_294:128, DET_RCS_295:128, DET_RCS_296:128, DET_SNR_293:0, DET_SNR_294:0, DET_SNR_295:0, DET_SNR_296:0, DET_SUPER_RES_TARGET_293:0, DET_SUPER_RES_TARGET_294:0, DET_SUPER_RES_TARGET_295:0, DET_SUPER_RES_TARGET_296:0]}, provided-interface=Pi_SG_Detections_293_296_AL
      Pp_SG_Detections_297_300_AL: nonqueued-sender-com-spec{data-element=Vdp_SG_Detections_297_300_AL, init-value=fields=[DET_AZIMUTH_297:0, DET_AZIMUTH_298:0, DET_AZIMUTH_299:0, DET_AZIMUTH_300:0, DET_AZIMUTH_ERR_297:0, DET_AZIMUTH_ERR_298:0, DET_AZIMUTH_ERR_299:0, DET_AZIMUTH_ERR_300:0, DET_BELOW_RAIN_THOLD_297:0, DET_BELOW_RAIN_THOLD_298:0, DET_BELOW_RAIN_THOLD_299:0, DET_BELOW_RAIN_THOLD_300:0, DET_BI_STATIC_FLAG_297:0, DET_BI_STATIC_FLAG_298:0, DET_BI_STATIC_FLAG_299:0, DET_BI_STATIC_FLAG_300:0, DET_CONFD_AZIMUTH_297:0, DET_CONFD_AZIMUTH_298:0, DET_CONFD_AZIMUTH_299:0, DET_CONFD_AZIMUTH_300:0, DET_CONFD_ELEVATION_297:0, DET_CONFD_ELEVATION_298:0, DET_CONFD_ELEVATION_299:0, DET_CONFD_ELEVATION_300:0, DET_ELEVATION_297:0, DET_ELEVATION_298:0, DET_ELEVATION_299:0, DET_ELEVATION_300:0, DET_ELEVATION_ERR_297:0, DET_ELEVATION_ERR_298:0, DET_ELEVATION_ERR_299:0, DET_ELEVATION_ERR_300:0, DET_EXISTENCE_PROB_297:0, DET_EXISTENCE_PROB_298:0, DET_EXISTENCE_PROB_299:0, DET_EXISTENCE_PROB_300:0, DET_HVC_FLAG_297:0, DET_HVC_FLAG_298:0, DET_HVC_FLAG_299:0, DET_HVC_FLAG_300:0, DET_IDM_297:0, DET_IDM_298:0, DET_IDM_299:0, DET_IDM_300:0, DET_MH_CRC16_297_300:0, DET_MH_CYCLE_COUNTER_297_300:0, DET_MH_SCAN_INDEX_4LSB_297_300:0, DET_MTD_297:0, DET_MTD_298:0, DET_MTD_299:0, DET_MTD_300:0, DET_PROB_1STAZHYPO_297:0, DET_PROB_1STAZHYPO_298:0, DET_PROB_1STAZHYPO_299:0, DET_PROB_1STAZHYPO_300:0, DET_RANGE_297:0, DET_RANGE_298:0, DET_RANGE_299:0, DET_RANGE_300:0, DET_RANGE_ERR_297:0, DET_RANGE_ERR_298:0, DET_RANGE_ERR_299:0, DET_RANGE_ERR_300:0, DET_RANGE_VELOCITY_297:16384, DET_RANGE_VELOCITY_298:16384, DET_RANGE_VELOCITY_299:16384, DET_RANGE_VELOCITY_300:16384, DET_RANGE_VELOCITY_ERR_297:0, DET_RANGE_VELOCITY_ERR_298:0, DET_RANGE_VELOCITY_ERR_299:0, DET_RANGE_VELOCITY_ERR_300:0, DET_RCS_297:128, DET_RCS_298:128, DET_RCS_299:128, DET_RCS_300:128, DET_SNR_297:0, DET_SNR_298:0, DET_SNR_299:0, DET_SNR_300:0, DET_SUPER_RES_TARGET_297:0, DET_SUPER_RES_TARGET_298:0, DET_SUPER_RES_TARGET_299:0, DET_SUPER_RES_TARGET_300:0]}, provided-interface=Pi_SG_Detections_297_300_AL
      Pp_SG_Detections_301_304_AL: nonqueued-sender-com-spec{data-element=Vdp_SG_Detections_301_304_AL, init-value=fields=[DET_AZIMUTH_301:0, DET_AZIMUTH_302:0, DET_AZIMUTH_303:0, DET_AZIMUTH_304:0, DET_AZIMUTH_ERR_301:0, DET_AZIMUTH_ERR_302:0, DET_AZIMUTH_ERR_303:0, DET_AZIMUTH_ERR_304:0, DET_BELOW_RAIN_THOLD_301:0, DET_BELOW_RAIN_THOLD_302:0, DET_BELOW_RAIN_THOLD_303:0, DET_BELOW_RAIN_THOLD_304:0, DET_BI_STATIC_FLAG_301:0, DET_BI_STATIC_FLAG_302:0, DET_BI_STATIC_FLAG_303:0, DET_BI_STATIC_FLAG_304:0, DET_CONFD_AZIMUTH_301:0, DET_CONFD_AZIMUTH_302:0, DET_CONFD_AZIMUTH_303:0, DET_CONFD_AZIMUTH_304:0, DET_CONFD_ELEVATION_301:0, DET_CONFD_ELEVATION_302:0, DET_CONFD_ELEVATION_303:0, DET_CONFD_ELEVATION_304:0, DET_ELEVATION_301:0, DET_ELEVATION_302:0, DET_ELEVATION_303:0, DET_ELEVATION_304:0, DET_ELEVATION_ERR_301:0, DET_ELEVATION_ERR_302:0, DET_ELEVATION_ERR_303:0, DET_ELEVATION_ERR_304:0, DET_EXISTENCE_PROB_301:0, DET_EXISTENCE_PROB_302:0, DET_EXISTENCE_PROB_303:0, DET_EXISTENCE_PROB_304:0, DET_HVC_FLAG_301:0, DET_HVC_FLAG_302:0, DET_HVC_FLAG_303:0, DET_HVC_FLAG_304:0, DET_IDM_301:0, DET_IDM_302:0, DET_IDM_303:0, DET_IDM_304:0, DET_MH_CRC16_301_304:0, DET_MH_CYCLE_COUNTER_301_304:0, DET_MH_SCAN_INDEX_4LSB_301_304:0, DET_MTD_301:0, DET_MTD_302:0, DET_MTD_303:0, DET_MTD_304:0, DET_PROB_1STAZHYPO_301:0, DET_PROB_1STAZHYPO_302:0, DET_PROB_1STAZHYPO_303:0, DET_PROB_1STAZHYPO_304:0, DET_RANGE_301:0, DET_RANGE_302:0, DET_RANGE_303:0, DET_RANGE_304:0, DET_RANGE_ERR_301:0, DET_RANGE_ERR_302:0, DET_RANGE_ERR_303:0, DET_RANGE_ERR_304:0, DET_RANGE_VELOCITY_301:16384, DET_RANGE_VELOCITY_302:16384, DET_RANGE_VELOCITY_303:16384, DET_RANGE_VELOCITY_304:16384, DET_RANGE_VELOCITY_ERR_301:0, DET_RANGE_VELOCITY_ERR_302:0, DET_RANGE_VELOCITY_ERR_303:0, DET_RANGE_VELOCITY_ERR_304:0, DET_RCS_301:128, DET_RCS_302:128, DET_RCS_303:128, DET_RCS_304:128, DET_SNR_301:0, DET_SNR_302:0, DET_SNR_303:0, DET_SNR_304:0, DET_SUPER_RES_TARGET_301:0, DET_SUPER_RES_TARGET_302:0, DET_SUPER_RES_TARGET_303:0, DET_SUPER_RES_TARGET_304:0]}, provided-interface=Pi_SG_Detections_301_304_AL
      Pp_SG_Detections_305_308_AL: nonqueued-sender-com-spec{data-element=Vdp_SG_Detections_305_308_AL, init-value=fields=[DET_AZIMUTH_305:0, DET_AZIMUTH_306:0, DET_AZIMUTH_307:0, DET_AZIMUTH_308:0, DET_AZIMUTH_ERR_305:0, DET_AZIMUTH_ERR_306:0, DET_AZIMUTH_ERR_307:0, DET_AZIMUTH_ERR_308:0, DET_BELOW_RAIN_THOLD_305:0, DET_BELOW_RAIN_THOLD_306:0, DET_BELOW_RAIN_THOLD_307:0, DET_BELOW_RAIN_THOLD_308:0, DET_BI_STATIC_FLAG_305:0, DET_BI_STATIC_FLAG_306:0, DET_BI_STATIC_FLAG_307:0, DET_BI_STATIC_FLAG_308:0, DET_CONFD_AZIMUTH_305:0, DET_CONFD_AZIMUTH_306:0, DET_CONFD_AZIMUTH_307:0, DET_CONFD_AZIMUTH_308:0, DET_CONFD_ELEVATION_305:0, DET_CONFD_ELEVATION_306:0, DET_CONFD_ELEVATION_307:0, DET_CONFD_ELEVATION_308:0, DET_ELEVATION_305:0, DET_ELEVATION_306:0, DET_ELEVATION_307:0, DET_ELEVATION_308:0, DET_ELEVATION_ERR_305:0, DET_ELEVATION_ERR_306:0, DET_ELEVATION_ERR_307:0, DET_ELEVATION_ERR_308:0, DET_EXISTENCE_PROB_305:0, DET_EXISTENCE_PROB_306:0, DET_EXISTENCE_PROB_307:0, DET_EXISTENCE_PROB_308:0, DET_HVC_FLAG_305:0, DET_HVC_FLAG_306:0, DET_HVC_FLAG_307:0, DET_HVC_FLAG_308:0, DET_IDM_305:0, DET_IDM_306:0, DET_IDM_307:0, DET_IDM_308:0, DET_MH_CRC16_305_308:0, DET_MH_CYCLE_COUNTER_305_308:0, DET_MH_SCAN_INDEX_4LSB_305_308:0, DET_MTD_305:0, DET_MTD_306:0, DET_MTD_307:0, DET_MTD_308:0, DET_PROB_1STAZHYPO_305:0, DET_PROB_1STAZHYPO_306:0, DET_PROB_1STAZHYPO_307:0, DET_PROB_1STAZHYPO_308:0, DET_RANGE_305:0, DET_RANGE_306:0, DET_RANGE_307:0, DET_RANGE_308:0, DET_RANGE_ERR_305:0, DET_RANGE_ERR_306:0, DET_RANGE_ERR_307:0, DET_RANGE_ERR_308:0, DET_RANGE_VELOCITY_305:16384, DET_RANGE_VELOCITY_306:16384, DET_RANGE_VELOCITY_307:16384, DET_RANGE_VELOCITY_308:16384, DET_RANGE_VELOCITY_ERR_305:0, DET_RANGE_VELOCITY_ERR_306:0, DET_RANGE_VELOCITY_ERR_307:0, DET_RANGE_VELOCITY_ERR_308:0, DET_RCS_305:128, DET_RCS_306:128, DET_RCS_307:128, DET_RCS_308:128, DET_SNR_305:0, DET_SNR_306:0, DET_SNR_307:0, DET_SNR_308:0, DET_SUPER_RES_TARGET_305:0, DET_SUPER_RES_TARGET_306:0, DET_SUPER_RES_TARGET_307:0, DET_SUPER_RES_TARGET_308:0]}, provided-interface=Pi_SG_Detections_305_308_AL
